VERSION ""

NS_ :

BS_:

BU_: VCU EAC EDS EPS BMS DCDC EVCC OBC
VAL_TABLE_ ALIVE_VCU_0xAB 15 "Invalid" ;
VAL_TABLE_ VCU_EDS_CtrModeReq 2 "Speed" 1 "Tqctr" 0 "inactive" ;
VAL_TABLE_ VCU_EDS_TargetTrqReq 4095 "Invalid" ;
VAL_TABLE_ VCU_EDS_TargetTrqReqV 0 "Valid" 1 "Invalid" ;
VAL_TABLE_ VCU_EDS_TargetSpeedReq 65535 "Invalid" ;
VAL_TABLE_ VCU_EDS_TargetSpeedReqV 0 "Valid" 1 "Invalid" ;
VAL_TABLE_ VCU_EDS_StsModeReq 15 "invaild" 14 "power oFF" 13 "Failure" 12 "aFter run" 11 "shut down" 5 "HVReady" 4 "normal" 3 "precharge" 2 "standby" 1 "init" 0 "deFault" ;
VAL_TABLE_ VCU_ACEnaReq 0 "No request" 1 "request" ;
VAL_TABLE_ VCU_ACSpdReq 8191 "Invalid" ;
VAL_TABLE_ VCU_ACPanelReqLevel 3 "Invalid" 2 "level 2 " 1 "level 1" 0 "oFF" ;
VAL_TABLE_ VCU_FanControl_Sts 0 "oFF" 1 "on" ;
VAL_TABLE_ VCU_ACPipePressSw_Sts 1 "close" 0 "open" ;
VAL_TABLE_ VCU_HVACInletTemp 1023 "Invalid" ;
VAL_TABLE_ ALIVE_VCU_0x155 15 "Invalid" ;
VAL_TABLE_ VCU_VecChrgRqst 0 "Default" 1 "permit" 2 "forbid" ;
VAL_TABLE_ VCU_Vechg_Status 3 "Charging Fault" 2 "Charging Complete" 1 "Charging in process" 0 "Charging not in process" ;
VAL_TABLE_ VCU_VecOptMod 0 "Sleep(休眠)" 1 "Initial(初始化)" 2 "PowerOn(上电)" 3 "Drive(行驶)" 4 "Charging(充电)" 5 "PowerOFF(下电)" 6 "Err(故障)" 7 "LimpHome" 8 "LVCharging(馈电补电)" ;
VAL_TABLE_ VCU_BMSHvPowOnRqst 1 "allow" 0 "forbid" ;
VAL_TABLE_ VCU_VecActGearStsV 1 "Invalid" 0 "Valid" ;
VAL_TABLE_ VCU_VecActGearSts 7 "Fault" 6 "Reserved" 5 "Reserved" 4 "Reserved" 3 "D" 2 "N" 1 "R" 0 "P" ;
VAL_TABLE_ VCU_LV_topupSts 3 "Rserved" 2 "Finish supply" 1 "suppling" 0 "dissupply" ;
VAL_TABLE_ VCU_DrTorqRqstV 1 "Invalid" 0 "Valid" ;
VAL_TABLE_ VCU_ABS_TrqReqOrLmt 65535 "Invalid" ;
VAL_TABLE_ VCU_CreepDisable_stt 0 "Enable" 1 "disable" ;
VAL_TABLE_ VCU_RDCSts 0 "inactive" 1 "Active" ;
VAL_TABLE_ VCU_RBCSts 0 "inactive" 1 "Active" ;
VAL_TABLE_ VCU_BrkPedalSWSts 0 "Notpressed" 1 "pressed" 2 "notused" 3 "Invalid" ;
VAL_TABLE_ Brakefluid_levelSts 0 "Normal" 1 "Low" 2 "Disconnect" 3 "reserve" ;
VAL_TABLE_ VCU_HandBrakeSts 0 "released" 1 "notreleased" ;
VAL_TABLE_ VCU_RegenLevelfeed 0 "OFF" 1 "ON" ;
VAL_TABLE_ VCU_PowerLimit 0 "NoLimit" 1 "Limit" ;
VAL_TABLE_ VCU_AccPedaPosValid 0 "Valid" 1 "Invalid" ;
VAL_TABLE_ VCU_VehicleHVStatus 0 "NotReady" 1 "HVOn" 2 "Ready" ;
VAL_TABLE_ VCUVacuumPresWrn 0 "Normal" 1 "Slight Insufficient" 2 "Serious Insufficient" 3 "Invalid" ;
VAL_TABLE_ VCUVacuumSts 0 "Normal" 1 "slow leak" 2 "quick leak" 3 "Invalid" ;
VAL_TABLE_ VCU_InstantPowerConsump 1023 "Invalid" ;
VAL_TABLE_ VCU_AveragePowerConsump 1023 "Invalid" ;
VAL_TABLE_ VCU_LowSOCWarning 0 "Normal" 1 "Low SOC" ;
VAL_TABLE_ VCU_TqReductionRqstResponse 0 "inactive" 1 "Active" ;
VAL_TABLE_ VCU_DrvModeSts 0 "Normal(正常模式)" 1 "Eco(经济模式)" 2 "Sport(运动模式)" 3 "Reserved(预留)" ;
VAL_TABLE_ VCU_VacuumPumpEna 1 "Enable" 0 "Disable" ;
VAL_TABLE_ VCU_VehicleFailureLevel 0 "Normal" 1 "Slight Fault" 2 "Minor fault" 3 "General fault" 4 "Serious Fault" 5 "Fatal fault" ;
VAL_TABLE_ VCU_EDSCAN_ERR 1 "Error" 0 "Normal" ;
VAL_TABLE_ VCU_BmsCAN_ERR 1 "Error" 0 "Normal" ;
VAL_TABLE_ VCU_DcdcCAN_ERR 1 "Error" 0 "Normal" ;
VAL_TABLE_ VCU_AbsCAN_ERR 1 "Error" 0 "Normal" ;
VAL_TABLE_ VCU_ACUCAN_ERR 1 "Error" 0 "Normal" ;
VAL_TABLE_ VCU_BcmCAN_ERR_reserved 1 "Error" 0 "Normal" ;
VAL_TABLE_ VCU_BrakeSys_Err 1 "Error" 0 "Normal" ;
VAL_TABLE_ VCU_AccPed_ERR 1 "Error" 0 "Normal" ;
VAL_TABLE_ VCU_Shift_ERR 1 "Error" 0 "Normal" ;
VAL_TABLE_ VCU_EPSCAN_ERR 1 "Error" 0 "Normal" ;
VAL_TABLE_ VCU_EvccCAN_ERR 1 "Error" 0 "Normal" ;
VAL_TABLE_ VCU_FlgHVIL_ERR 1 "Error" 0 "Normal" ;
VAL_TABLE_ VCU_ObcCAN_ERR 1 "Error" 0 "Normal" ;
VAL_TABLE_ VCU_SSCAN_ERR 1 "Error" 0 "Normal" ;
VAL_TABLE_ VCU_EacCAN_ERR 1 "Error" 0 "Normal" ;
VAL_TABLE_ VCU_AccPedalOutRange 1 "Error" 0 "Normal" ;
VAL_TABLE_ EDS_VCU_CtrMode 0 "Inactive" 1 "Toque control mode" 2 "Anti-slide slope" 3 "reserved" ;
VAL_TABLE_ EDS_MotorSpdVD 0 "Valid" 1 "Invalid" ;
VAL_TABLE_ EDS_MotorTqVD 0 "Valid" 1 "Invalid" ;
VAL_TABLE_ EDS_MotorTq 65534 "Abnormal" 65535 "Invaild" ;
VAL_TABLE_ EDS_MotorSpd 65534 "Abnormal" 65535 "Invaild" ;
VAL_TABLE_ EDS_HSA_Sts 0 "Inactive" 1 "Active" 2 "Reserved" 3 "Invalid" ;
VAL_TABLE_ EDS_DriveSTS 0 "Regeneration control" 1 "Drive control" 2 "Zero control" ;
VAL_TABLE_ EDS_StsMode 0 "DeFault(默认值)" 1 "Init(初始化)" 2 "Standby(待机)" 3 "Precharge(预充)" 4 "Normal(正常运行)" 5 "HVReady(高压上电完成)" 11 "ShutDown(关闭)" 12 "AFterRun(运行后)" 13 "Failure" 14 "PowerOFF(下电)" ;
VAL_TABLE_ EDS_VehicleFailureLevel 0 "Normal" 1 "Slight Fault" 2 "Minor fault" 3 "General fault" 4 "Serious Fault" 5 "Fatal fault" ;
VAL_TABLE_ EDS_HSA_Fault 0 "Normal" 1 "Level 1" 2 "Level 2" 3 "Invalid" ;
VAL_TABLE_ ALIVE_EDS_0xCA 15 "Invalid" ;
VAL_TABLE_ EDS_ActHV_VoltVD 1 "valid" 0 "invalid" ;
VAL_TABLE_ EDS_ActHV_CurVD 1 "valid" 0 "invalid" ;
VAL_TABLE_ EDS_ActHV_Cur 4095 "Invalid" ;
VAL_TABLE_ EDS_ActHV_Volt 4095 "Invalid" ;
VAL_TABLE_ ALIVE_EDS_0xCE 15 "Invalid" ;
VAL_TABLE_ EDS_MaxSpeedLimit 65535 "Invalid" ;
VAL_TABLE_ ALIVE_EDS_0x367 15 "Invalid" ;
VAL_TABLE_ EDS_MotTempSenFault 0 "Normal" 1 "Error" ;
VAL_TABLE_ EDS_EDSOverTempAlarm 0 "Normal" 1 "Error" ;
VAL_TABLE_ EDS_EDSOverTempFault 0 "Normal" 1 "Error" ;
VAL_TABLE_ EDS_LV_VotagtFault 0 "Normal" 1 "Error" ;
VAL_TABLE_ EDS_PhashOverCurrentSWFault 0 "Normal" 1 "Error" ;
VAL_TABLE_ EDS_EDSCurrentSenVFault 0 "Normal" 1 "Error" ;
VAL_TABLE_ EDS_EDSCurrentSenWFault 0 "Normal" 1 "Error" ;
VAL_TABLE_ EDS_EDSHVOverVoltageAlarm 0 "Normal" 1 "Error" ;
VAL_TABLE_ EDS_EDSHVOverVoltageFault 0 "Normal" 1 "Error" ;
VAL_TABLE_ EDS_EDSHVUnderVoltageAlarm 0 "Normal" 1 "Error" ;
VAL_TABLE_ EDS_EDSHVUnderVoltageFault 0 "Normal" 1 "Error" ;
VAL_TABLE_ EDS_MotOverTempAlarm 0 "Normal" 1 "Error" ;
VAL_TABLE_ EDS_MotOverTempFault 0 "Normal" 1 "Error" ;
VAL_TABLE_ EDS_EDSDisChgFault 0 "Normal" 1 "Error" ;
VAL_TABLE_ EDS_EDSHVSenFault 0 "Normal" 1 "Error" ;
VAL_TABLE_ EDS_12VOverVoltageAlarm 0 "Normal" 1 "Error" ;
VAL_TABLE_ EDS_12VUnderVoltageAlarm 0 "Normal" 1 "Error" ;
VAL_TABLE_ EDS_MotOverAlarm 0 "Normal" 1 "Error" ;
VAL_TABLE_ EDS_MotOverFault 0 "Normal" 1 "Error" ;
VAL_TABLE_ EDS_PhashOverCurrentHWFault 0 "Normal" 1 "Error" ;
VAL_TABLE_ EDS_EDSCurrentSenUFault 0 "Normal" 1 "Error" ;
VAL_TABLE_ EDS_VCULostFault 0 "Normal" 1 "Error" ;
VAL_TABLE_ EDS_BMSLostFault 0 "Normal" 1 "Error" ;
VAL_TABLE_ EDS_MotRotSenFault 0 "Normal" 1 "Error" ;
VAL_TABLE_ EDS_MotBlockedFault 0 "Normal" 1 "Error" ;
VAL_TABLE_ EDS_EDSChksumFault 0 "Normal" 1 "Error" ;
VAL_TABLE_ EDS_MotTrqLimtFault 0 "Normal" 1 "Error" ;
VAL_TABLE_ EDS_VCUChksumFault 0 "Normal" 1 "Error" ;
VAL_TABLE_ EDS_EDSEnableFault 0 "Normal" 1 "Error" ;
VAL_TABLE_ EDS_IGBTFault 0 "Normal" 1 "Error" ;
VAL_TABLE_ EDS_CANBUSOFFFault 0 "Normal" 1 "Error" ;
VAL_TABLE_ EDS_EDSTempSensorErr 0 "Normal" 1 "Error" ;
VAL_TABLE_ EDS_HWCapOverVolt 0 "Normal" 1 "Error" ;
VAL_TABLE_ EDS_SWCapOverVolt 0 "Normal" 1 "Error" ;
VAL_TABLE_ EDS_EDSMemoryFlt 0 "Normal" 1 "Error" ;
VAL_TABLE_ EDS_InitMode 0 "Normal" 1 "Error" ;
VAL_TABLE_ ALIVE_EDS_0x369 15 "Invalid" ;
VAL_TABLE_ EDS_IGBTState 3 "Normal operation" 2 "ASC From lower bridge arm" 1 "Enter ASC From upper bridge arm " 0 "OFF" ;
VAL_TABLE_ EDS_DampingState 1 "Dampingactive" 0 "Dampingdisable" ;
VAL_TABLE_ EDS_StsActiveDisChg 0 "NotActiveDischarge" 1 "ActiveDischarge" 2 "FailedActiveDischarge" 3 "FinishedActiveDischarge" ;
VAL_TABLE_ EDS_Motor_Phase_Curr 65535 "Invalid" ;
VAL_TABLE_ Rolling_counter_0x17E 15 "Invalid" ;
VAL_TABLE_ EPS_S_WarningLampYellow 0 "OFF" 1 "ON" ;
VAL_TABLE_ EPS_S_SaFeLampRed 0 "OFF" 1 "ON" ;
VAL_TABLE_ EPS_SteerWheelAngle 65535 "Invalid" ;
VAL_TABLE_ EPS_SteerWhlRotSpd 16383 "Invalid" ;
VAL_TABLE_ EPS_SteerWheelRotSpdStatus 0 "Valid" 1 "Invalid" ;
VAL_TABLE_ EPS_SteeringAngleValid 0 "Valid" 1 "Invalid" ;
VAL_TABLE_ EPS_VehicleFailureLevel 0 "Normal" 1 "Slight Fault" 2 "Minor fault" 3 "General fault" 4 "Serious Fault" 5 "Fatal fault" ;
VAL_TABLE_ EPS_status 0 "NoFailure" 1 "SlightFailure" 2 "CriticalFailure" 3 "FatalFailure" ;
VAL_TABLE_ EPS_Calibrated 0 "NotCalibrated" 1 "Calibrated" ;
VAL_TABLE_ EPS_Systemstatus 0 "NoFailure" 1 "SlightFailure" 2 "CriticalFailure" 3 "FatalFailure" ;
VAL_TABLE_ Alive_SAS_0x17F 15 "Invalid" ;
VAL_TABLE_ EPS_SteeringTorque 4095 "Invalid" ;
VAL_TABLE_ EPS_SASFailure 0 "Failure" 1 "No failure" ;
VAL_TABLE_ EPS_SASStsSnsr 1 "sensor value valid" 0 "sensor value Invalid" ;
VAL_TABLE_ EPS_TorqSensorStatus 0 "Valid" 1 "Invalid" ;
VAL_TABLE_ EPS_Mode 3 " Invalid" 1 "low assist" 0 "Full assist" ;
VAL_TABLE_ EPS_EpsFailed 1 "Failed" 0 "not Failed" ;
VAL_TABLE_ EAC_Sts 0 "Stop" 1 "Work" ;
VAL_TABLE_ EAC_VehicleFailureLevel 0 "Normal" 1 "Slight Fault" 2 "Minor fault" 3 "General fault" 4 "Serious Fault" 5 "Fatal fault" ;
VAL_TABLE_ EAC_ErrorCode 0 "Normal" 1 "Under Voltage" 2 "Over Voltage" 3 "Over Temperature" 4 "Over Current" 5 "IGBT Fault" 6 "Over Pressure" ;
VAL_TABLE_ Rolling_Counter_0x85 15 "Invalid" ;
VAL_TABLE_ ACU_Crash_Sts 3 "Invalid Value" 2 "Invalid Value" 1 "Crash_Detected" 0 "No_Event" ;
VAL_TABLE_ ACU_Airbag_Deployment_Status 3 "Invalid Value" 2 "Invalid Value" 1 "Airbag_Deployment" 0 "No_Airbag_Deployment" ;
VAL_TABLE_ ALIVE_ABS_0x118 15 "Invalid" ;
VAL_TABLE_ ABS_HazardLightsOnReq 0 "No request" 1 "request" ;
VAL_TABLE_ ABS_BrakeLightsOnReq 0 "No request" 1 "request" ;
VAL_TABLE_ ABS_TcsFlgFlt 1 "Failure" 0 "no Failure" ;
VAL_TABLE_ ABS_TCS_Active 1 "active" 0 "inactive" ;
VAL_TABLE_ ABS_ABSActive 1 "active" 0 "inactive" ;
VAL_TABLE_ ABS_EBDFault 1 "Fault" 0 "Normal" ;
VAL_TABLE_ ABS_ABSFault 1 "Fault" 0 "Normal" ;
VAL_TABLE_ ABS_TCS_OFF_State 1 "open" 0 "close" ;
VAL_TABLE_ ABS_VehicleFailureLevel 0 "Normal" 1 "Slight Fault" 2 "Minor fault" 3 "General fault" 4 "Serious Fault" 5 "Fatal fault" ;
VAL_TABLE_ ABS_RBSInhibitFlag 0 "Not Inhibit" 1 "Inhibit" ;
VAL_TABLE_ ABS_EBDActive 1 "active" 0 "inactive" ;
VAL_TABLE_ ABS_VehicleSpeed 32767 "Invalid" ;
VAL_TABLE_ ABS_VehicleSpeedV 0 "Invalid" 1 "Valid" ;
VAL_TABLE_ BCM_FrontLeftDoorAjarStatus 0 "Closed" 1 "Opened" 2 "Reserved" 3 "Signal invalid" ;
VAL_TABLE_ BCM_FrontRightDoorAjarStatus 0 "Closed" 1 "Opened" 2 "Reserved" 3 "Signal invalid" ;
VAL_TABLE_ BCM_RightDoorLockStatusDrv 0 "Unlcoked" 1 "Locked" 2 "Reserved" 3 "Signal invalid" ;
VAL_TABLE_ BCM_LeftDoorLockStatusDrv 0 "Unlcoked" 1 "Locked" 2 "Reserved" 3 "Signal invalid" ;
VAL_TABLE_ BCM_ATWS_St 0 "Secured" 1 "Unsecured" 2 "Alarm" 3 "Partly secured" 4 "Security Failure" 5 "Reserved" 6 "Reserved" 7 "Signal invalid" ;
VAL_TABLE_ BCM_STAT_DoorSpeedLock 0 "OFF" 1 "5KMH" 2 "10KMH" 3 "15KMH" 4 "20KMH" 5 "25KMH" 6 "Signal invalid" ;
VAL_TABLE_ BCM_LV_topupReq 0 "inactive" 1 "Active" 2 "Rserved" 3 "Rserved" ;
VAL_TABLE_ BCM_BatteryVoltage 597 "Invalid" ;
VAL_TABLE_ BCM_Key_CheckSts 0 "Passed" 1 "Invalid" ;
VAL_TABLE_ BCM_Press_BrkPedal_Alert 0 "inactive" 1 "Active" ;
VAL_TABLE_ BCM_EmergencyStop 0 "Normal" 1 "EmergencyStop" 2 "Rserved" 3 "Invalid" ;
VAL_TABLE_ BCM_IGN1RelayOutputSts 0 "inactive" 1 "Active" 2 "Reserved" 3 "Reserved" ;
VAL_TABLE_ BCM_ACCRelayOutputSts 0 "inactive" 1 "Active" 2 "Reserved" 3 "Reserved" ;
VAL_TABLE_ BCM_FLWIN_Postion_Reserved 0 "NotActive" 1 "Closed(Top)" 2 "Open(Bottom)" 3 "80%-Close(Reserved)" 4 "Open-80%(Reserved)" 5 "opening" 6 "closing" 7 "Reserved" ;
VAL_TABLE_ BCM_KEY_MatchSts 0 "No Match" 1 "Match Success" 2 "Match Failed" 3 "Matching" ;
VAL_TABLE_ BCM_FRWIN_Postion_Reserved 0 "NotActive" 1 "Closed(Top)" 2 "Open(Bottom)" 3 "80%-Close(Reserved)" 4 "Open-80%(Reserved)" 5 "opening" 6 "closing" 7 "Reserved" ;
VAL_TABLE_ BCM_PowerMode 0 "OFF" 1 "ACC" 2 "ON" 3 "START" ;
VAL_TABLE_ BCM_BrakeSwSts 0 "Notpressed" 1 "pressed" 2 "notused" 3 "Invalid" ;
VAL_TABLE_ BCM_VehicleFailureLevel 0 "Normal" 1 "Slight Fault" 2 "Minor fault" 3 "General fault" 4 "Serious Fault" 5 "Fatal fault" ;
VAL_TABLE_ BCM_Anti_theftAlarmSetSts 0 "Light" 1 "Horn" 2 "Both" 3 "Invalid" ;
VAL_TABLE_ BCM_FMH_SetSts 0 "OFF" 1 "30s" 2 "60s" 3 "90s" ;
VAL_TABLE_ BCM_IGN1RelayFaultSts 0 "No Fault" 1 "Fault" 2 "Reserved" 3 "Signal Invalid" ;
VAL_TABLE_ BCM_ACCRelayFaultSts 0 "No Fault" 1 "Fault" 2 "Reserved" 3 "Signal Invalid" ;
VAL_TABLE_ IPC_EnergyRecSet 0 "OFF(关闭)" 1 "ON(开启)" 2 "Reserved(预留)" 3 "Reserved(预留)" ;
VAL_TABLE_ IPC_HSA_Set 0 "OFF" 1 "ON" 2 "Reserved" 3 "Invalid" ;
VAL_TABLE_ IPC_DriveModeSet 0 "NoReq" 1 "NormalMode" 2 "ECOmode" 3 "SportMode(预留)" ;
VAL_TABLE_ IPC_VCU_CreepDisable_Stt 0 "No request" 1 "request" ;
VAL_TABLE_ IPC_DriveLockSpeedCtl 0 "OFF" 1 "5KMH" 2 "10KMH" 3 "15KMH" 4 "20KMH" 5 "25KMH" 6 "Signal invalid" ;
VAL_TABLE_ Rolling_Counter_0x432 15 "Invalid" ;
VAL_TABLE_ IPC_FOTA_State 0 "INIT" 1 "NORMAL" 2 "FOTA FLASHING" 3 "Reserved" 4 "FAIL-SAFE-ERROR" 5 "Reserved" 6 "REMOTE DIAGNOSTICS" 7 "Invalid" ;
VAL_TABLE_ IPC_ChargeScheduleSet 0 "Disable" 1 "Enabled" 2 "No Action" 3 "Reserved" ;
VAL_TABLE_ IPC_ChargingRequest 0 "No Effect" 1 "Request scheduled start charging" 2 "Request stop" 3 "Reserved" ;
VAL_TABLE_ IPC_Year 255 "Invalid" ;
VAL_TABLE_ IPC_Month 15 "Invalid" ;
VAL_TABLE_ IPC_SelFCheckStatus 1 "selF-check Finish" 0 "selF-checking" ;
VAL_TABLE_ IPC_Day 31 "Invalid" ;
VAL_TABLE_ IPC_Hour 31 "Invalid" ;
VAL_TABLE_ IPC_Min 63 "Invalid" ;
VAL_TABLE_ IPC_Sec 63 "Invalid" ;
VAL_TABLE_ IPC_ODO 1048575 "Invalid" ;
VAL_TABLE_ Rolling_Counter_0x108 15 "Invalid" ;
VAL_TABLE_ SS_DriveModeReq_reserved 1 "press" 0 "no press" ;
VAL_TABLE_ SS_TargetGearReq 7 "Reserved" 4 "Invalid" 3 "D" 2 "N" 1 "R" 0 "Stop Charging" ;
VAL_TABLE_ SS_Fault 6 "Received Date from BCM is invalid" 5 "Received Date from VCU is invalid" 4 "Supply voltage failure" 3 "Position sensor failure" 2 "CAN communication fail" 1 "Shifter failure" 0 "normal" ;
VAL_TABLE_ FR_Wipercontrol_switch 7 "Invalid " 6 "reserved " 5 "reserved " 4 "High " 3 "Int2 " 2 "Int1 " 1 "Low " 0 "OFF" ;
VAL_TABLE_ Front_Wash 3 "Invalid " 2 "Wash " 1 "Mist" 0 "OFF" ;
VAL_TABLE_ SS_FogLight_reserved 0 "OFF" 1 "ON" ;
VAL_TABLE_ RR_Wiper 3 "Invalid " 2 "Wash " 1 "Wipe " 0 "OFF" ;
VAL_TABLE_ SS_lane_change_lampSts 0 "OFF" 1 "Left lane change" 2 "Right lane change" 3 "Reserved" ;
VAL_TABLE_ SS_Overtaking_lamp 0 "OFF" 1 "ON" ;
VAL_TABLE_ SS_TurnIndicatorSts 0 "OFF" 1 "Left On" 2 "Right On" 3 "Reserved" ;
VAL_TABLE_ SS_PosLmpSts 0 "OFF " 1 "ON" ;
VAL_TABLE_ SS_LowBeamSts 0 "OFF" 1 "ON" ;
VAL_TABLE_ SS_HighBeamSts 0 "OFF" 1 "ON" ;
VAL_TABLE_ Rolling_Counter_0x216 15 "Invalid" ;
VAL_TABLE_ BMS_RemainChargeTime 16383 "Invalid" ;
VAL_TABLE_ BMS_ChgVoltage_REQ 16383 "Invalid" ;
VAL_TABLE_ BMS_ChgCurrent_REQ 65535 "Invalid" ;
VAL_TABLE_ Rolling_Counter_0x126 15 "Invalid" ;
VAL_TABLE_ BMS_AllowRegCurrPeak 65535 "Invalid" ;
VAL_TABLE_ BMS_AllowRegCurr 65535 "Invalid" ;
VAL_TABLE_ Rolling_Counter_0x209 15 "Invalid" ;
VAL_TABLE_ BMS_MaxDischgPwr_ALW 4095 "Invalid" ;
VAL_TABLE_ BMS_MaxChgPwr_ALW 4095 "Invalid" ;
VAL_TABLE_ BMS_MaxDischgPwr_Peak 4095 "Invalid" ;
VAL_TABLE_ BMS_MaxChgPwr_Peak 4095 "Invalid" ;
VAL_TABLE_ Rolling_Counter_0x249 15 "Invalid" ;
VAL_TABLE_ Rolling_Counter_0x248 15 "Invalid" ;
VAL_TABLE_ BMS_FlowRate_Req 255 "Invalid" ;
VAL_TABLE_ BMS_CoolPwrDemand 4095 "Invalid" ;
VAL_TABLE_ BMS_VCU_ValveOnOff_Req 1 "open " 0 "close" ;
VAL_TABLE_ BMS_HeatPwrDemand 4095 "Invalid" ;
VAL_TABLE_ BMS_VCU_PTCOnOff_Req 1 "ON" 0 "OFF" ;
VAL_TABLE_ Rolling_Counter_0x206 15 "Invalid" ;
VAL_TABLE_ BMS_MaxMinDiffCellVol 8191 "Invalid value if diff > 500mV" ;
VAL_TABLE_ Rolling_Counter_0x332 15 "Invalid" ;
VAL_TABLE_ BMS_PackTemp_Infor 255 "Invalid" ;
VAL_TABLE_ Rolling_Counter_0x330 15 "Invalid" ;
VAL_TABLE_ BMS_ContactorAging 2 "Fault: counter reach 98%" 1 "Warning: counter reach 90%" 0 "Normal" ;
VAL_TABLE_ Rolling_Counter_0x176 15 "Invalid" ;
VAL_TABLE_ BMS_HVLinkVol_MEAS 65535 "Invalid" ;
VAL_TABLE_ BMS_HVPackVol_MEAS 65535 "Invalid" ;
VAL_TABLE_ Rolling_Counter_0x177 15 "Invalid" ;
VAL_TABLE_ BMS_HVBusVol_MEAS 65535 "Invalid" ;
VAL_TABLE_ BMS_HVFuseVol_MEAS 65535 "Invalid" ;
VAL_TABLE_ Rolling_Counter_0x174 15 "Invalid" ;
VAL_TABLE_ BMS_PackCur_MEAS 65535 "Invalid" ;
VAL_TABLE_ BMS_AllowDischgCurr 65535 "Invalid" ;
VAL_TABLE_ BMS_AllowDischgCurrPeak 65535 "Invalid" ;
VAL_TABLE_ Rolling_Counter_0x214 15 "Invalid" ;
VAL_TABLE_ BMS_Display_SOC 1023 "Invalid" ;
VAL_TABLE_ Rolling_Counter_0x215 15 "Invalid" ;
VAL_TABLE_ BMS_SOE 255 "Invalid" ;
VAL_TABLE_ BMS_HWCrash_Sts 1 "Crash " 0 "No Crash" ;
VAL_TABLE_ BMS_HVIL_STS 2 "out of range" 1 "Open" 0 "Closed" ;
VAL_TABLE_ BMS_IGN_Sts 1 "ON " 0 "OFF" ;
VAL_TABLE_ BMS_Sys_STS 8 "Invalid" 7 "Failure, unable to operate" 6 "BCU Sleep mode" 5 "Successful Power Down" 4 "Power Down process" 3 "Successful Power Down of HV" 2 "Successful High Voltage Power Up" 1 "Self-check passes, can be high-voltage" 0 "Initialization of power on, self-checking" ;
VAL_TABLE_ BMS_HVOnOff_STS 3 "Fail to HV on " 2 "HV On " 1 "Precharge " 0 "HV Off" ;
VAL_TABLE_ BMS_Balance_STS 1 "active " 0 "Inactive" ;
VAL_TABLE_ BMS_BatBalance_ERR 1 "normal " 0 "Error" ;
VAL_TABLE_ BMS_ISU_Status 3 "Level3(<100 Ohms/V)" 2 "Level2(<200 Ohms/V)" 1 "Level1 <500 Ohms/V ~ >200 Ohms/V" 0 "Normal (> 500 Ohms/V)" ;
VAL_TABLE_ BMS_ERR_LEV 7 "Battery locked -Reserved" 6 "Fault, needs Shutdown and Wakeup" 5 "Emergency off condition" 4 "Delayed power down with FTTI" 3 "Power down without FTTI" 2 "Limp Home" 1 " Warning (any warning in system)" 0 "No error" ;
VAL_TABLE_ BMS_Vehicle_ERR_LEV 0 "Normal" 1 "Slight Fault" 2 "Minor fault" 3 "General fault" 4 "Serious Fault" 5 "Fatal fault" ;
VAL_TABLE_ BMS_HV_Sts 4 "AC Charging" 3 "DC Charging" 2 "HV ON" 1 "Precharge" 0 "HV Off" ;
VAL_TABLE_ Rolling_Counter_0x225 15 "Invalid" ;
VAL_TABLE_ CDM_bAcvCanComStblMon 1 "Error" 0 "No error" ;
VAL_TABLE_ FRMo_bErrHvbatStReqExtMon 1 "Error" 0 "No error" ;
VAL_TABLE_ FRMo_bErrChrgnAllwdExtMon 1 "Error" 0 "No error" ;
VAL_TABLE_ FRMo_bErrVehCrashStExtMon 1 "Error" 0 "No error" ;
VAL_TABLE_ CDM_bErrComctnLossCanMon 1 "Error" 0 "No error" ;
VAL_TABLE_ CTCMon_bErrCtctrSopcMon 1 "Error" 0 "No error" ;
VAL_TABLE_ CTCMon_bInvldCtctrHisdIFbMon 1 "Error" 0 "No error" ;
VAL_TABLE_ CTCMon_bInvldCtctrLosdUFbMon 1 "Error" 0 "No error" ;
VAL_TABLE_ CTM_bErrCellTDifMaxMon 1 "Error" 0 "No error" ;
VAL_TABLE_ CTM_bErrCellTMaxMon 1 "Error" 0 "No error" ;
VAL_TABLE_ CTM_bErrCellTMinMon 1 "Error" 0 "No error" ;
VAL_TABLE_ CTM_bErrThrwyPredMon 1 "Error" 0 "No error" ;
VAL_TABLE_ CUM_bErrCellUDifMaxMon 1 "Error" 0 "No error" ;
VAL_TABLE_ CUM_bErrCellUMaxMon 1 "Error" 0 "No error" ;
VAL_TABLE_ CUM_bErrCellUMinMon 1 "Error" 0 "No error" ;
VAL_TABLE_ CUM_bErrCellUProtnMaxNvMon 1 "Error" 0 "No error" ;
VAL_TABLE_ CUM_bErrCellUProtnMinNvMon 1 "Error" 0 "No error" ;
VAL_TABLE_ CUM_bErrPackUImplyMon 1 "Error" 0 "No error" ;
VAL_TABLE_ EHPMon_bRdyHvilMon 1 "Error" 0 "No error" ;
VAL_TABLE_ EHPMon_bErrWlddNegNvMon 1 "Error" 0 "No error" ;
VAL_TABLE_ EHPMon_bErrWlddPosNvMon 1 "Error" 0 "No error" ;
VAL_TABLE_ EHPMon_bErrWlddPrechNvMon 1 "Error" 0 "No error" ;
VAL_TABLE_ EHPMon_bErrHvilMon 1 "Error" 0 "No error" ;
VAL_TABLE_ EHPMon_bErrHvilShoMon 1 "Error" 0 "No error" ;
VAL_TABLE_ EHPMon_bErrPackIslnRNvMon 1 "Error" 0 "No error" ;
VAL_TABLE_ EHPMon_bErrVehCrashNvMon 1 "Error" 0 "No error" ;
VAL_TABLE_ EHPMon_bErrVehIslnRNvMon 1 "Error" 0 "No error" ;
VAL_TABLE_ FRMo_bErrMemStorgNvMon 1 "Error" 0 "No error" ;
VAL_TABLE_ L1IM_bErrClmp30MaxMonInp 1 "Error" 0 "No error" ;
VAL_TABLE_ L1IM_bErrClmp30MinMonInp 1 "Error" 0 "No error" ;
VAL_TABLE_ L1IM_bErrCtctrDtrtMonInp 1 "Error" 0 "No error" ;
VAL_TABLE_ L1IM_bErrUActImplyMonInp 1 "Error" 0 "No error" ;
VAL_TABLE_ MCCM_bAcvMdulCtlrStsMon 1 "Error" 0 "No error" ;
VAL_TABLE_ MCCM_bErrLntecSngFltMon 1 "Error" 0 "No error" ;
VAL_TABLE_ MCCM_bErrLntecLtntFltMon 1 "Error" 0 "No error" ;
VAL_TABLE_ MCCM_bErrMdulCellSnsrCfgMon 1 "Error" 0 "No error" ;
VAL_TABLE_ MCCM_bErrMdulCtlrComMon 1 "Error" 0 "No error" ;
VAL_TABLE_ MCCM_bErrSnsrTEltlMon 1 "Error" 0 "No error" ;
VAL_TABLE_ MCCM_bWarnSnsrTEltlMon 1 "Error" 0 "No error" ;
VAL_TABLE_ PCM_bRdySnsrIMon 1 "Error" 0 "No error" ;
VAL_TABLE_ PCM_bErrPackEFlowMaxLimMon 1 "Error" 0 "No error" ;
VAL_TABLE_ PCM_bErrPackIChDchaMaxLimMon 1 "Error" 0 "No error" ;
VAL_TABLE_ PCM_bErrSnsrIImplyMon 1 "Error" 0 "No error" ;
VAL_TABLE_ FRMo_bErrSnsrI1ExtMon 1 "Error" 0 "No error" ;
VAL_TABLE_ PCM_bInvldSnsrI1Mon 1 "Error" 0 "No error" ;
VAL_TABLE_ PCM_bInvldSnsrI2Mon 1 "Error" 0 "No error" ;
VAL_TABLE_ FRMo_bErrSopcLvl3Mon 1 "Error" 0 "No error" ;
VAL_TABLE_ BMS_FRMo_Reserved_1 1 "Error" 0 "No error" ;
VAL_TABLE_ BMS_FRMo_Reserved_2 1 "Error" 0 "No error" ;
VAL_TABLE_ BMS_FRMo_Reserved_3 1 "Error" 0 "No error" ;
VAL_TABLE_ BMS_FRMo_Reserved_4 1 "Error" 0 "No error" ;
VAL_TABLE_ BMS_FRMo_Reserved_5 1 "Error" 0 "No error" ;
VAL_TABLE_ Rolling_Counter_0x125 15 "Invalid" ;
VAL_TABLE_ Rolling_Counter_0x375 15 "Invalid" ;
VAL_TABLE_ BMS_MainPosRelay_ERR 1 "normal " 0 "Error" ;
VAL_TABLE_ BMS_MainPosRelay_STS 4 "stuck open" 3 "stuck closed" 2 "closed" 1 "open" 0 "reserved" ;
VAL_TABLE_ BMS_PreChgRelay_ERR 1 "normal " 0 "error" ;
VAL_TABLE_ BMS_PreChgRelay_STS 4 "stuck open" 3 "stuck closed" 2 "closed" 1 "open" 0 "reserved" ;
VAL_TABLE_ BMS_TotalNegRelay_STS 4 "stuck open" 3 "stuck closed" 2 "closed" 1 "open" 0 "reserved" ;
VAL_TABLE_ BMS_TotalNegRelay_ERR 1 "normal " 0 "Error" ;
VAL_TABLE_ Rolling_Counter_0x205 15 "Invalid" ;
VAL_TABLE_ BMS_MaxCellVol 8191 "Invalid" ;
VAL_TABLE_ BMS_CellNumMaxCellVol 0 "Invalid" ;
VAL_TABLE_ BMS_MinCellVol 8191 "Invalid" ;
VAL_TABLE_ BMS_CellNumMinCellVol 0 "Invalid" ;
VAL_TABLE_ Rolling_Counter_0x245 15 "Invalid" ;
VAL_TABLE_ BMS_PackTemp 255 "Invalid" ;
VAL_TABLE_ BMS_MaxMinDiffCellTemp 255 "Diff Temp" ;
VAL_TABLE_ BMS_MaxCellTemp 255 "Invalid" ;
VAL_TABLE_ BMS_MinCellTemp 255 "Invalid" ;
VAL_TABLE_ BMS_ProbeNumMaxCellTemp 63 "Invalid" 62 "Error" 0 "Invalid" ;
VAL_TABLE_ BMS_ProbeNumMinCellTemp 63 "Invalid" 62 "Error" 0 "Invalid" ;
VAL_TABLE_ Rolling_Counter_0x305 15 "Invalid" ;
VAL_TABLE_ BMS_VCU_Insulation_Mon_Sts 1 "OFF" 0 "ON" ;
VAL_TABLE_ BMS_Warning_Flag_Reserved_08 1 "Warning" 0 "No warning" ;
VAL_TABLE_ BMS_Warning_Flag_Reserved_07 1 "Warning" 0 "No warning" ;
VAL_TABLE_ BMS_Warning_Flag_Reserved_11 1 "Warning" 0 "No warning" ;
VAL_TABLE_ BMS_Warning_Flag_Reserved_10 1 "Warning" 0 "No warning" ;
VAL_TABLE_ BMS_Warning_Flag_Reserved_09 1 "Warning" 0 "No warning" ;
VAL_TABLE_ BMS_Warning_Flag_Reserved_13 1 "Warning" 0 "No warning" ;
VAL_TABLE_ BMS_Warning_Flag_Reserved_12 1 "Warning" 0 "No warning" ;
VAL_TABLE_ BMS_Warning_Flag_Reserved_06 1 "Warning" 0 "No warning" ;
VAL_TABLE_ BMS_Warning_Flag_Reserved_05 1 "Warning" 0 "No warning" ;
VAL_TABLE_ BMS_Warning_Flag_Reserved_04 1 "Warning" 0 "No warning" ;
VAL_TABLE_ BMS_MalfunctionSts 1 "Malfunction indicator lamp ON" 0 "Malfunction indicator lamp OFF" ;
VAL_TABLE_ BMS_LowBattery 2 "Extremely low level" 1 "Low level" 0 "No warning" ;
VAL_TABLE_ BMS_BatteryReplacement 1 "Warning" 0 "No warning" ;
VAL_TABLE_ BMS_PackTempSts 2 "Under Temperature Warning" 1 "Over Temperature Warning" 0 "No warning" ;
VAL_TABLE_ BMS_ThermalRunaway 1 "Warning" 0 "No warning" ;
VAL_TABLE_ Rolling_Counter_0x493 15 "Invalid" ;
VAL_TABLE_ Rolling_Counter_0x455 15 "Invalid" ;
VAL_TABLE_ BMS_PackInsu_ERR 2 "Lv2-Short to vbat and open line" 1 "Lv1 - Short to ground" 0 "Lv0-No Err" ;
VAL_TABLE_ BMS_CellVoltDiff_ERR 3 "Level3 Reserve" 2 "Level2 Serious alarm value" 1 "Level1 General alarm value" 0 "Level0 Normal" ;
VAL_TABLE_ BMS_PackOverCurr_ERR 2 "Serious Alarm value" 1 "General Alarm Value" 0 "Normal" ;
VAL_TABLE_ BMS_HVIL_Err 3 "Level3" 2 "Level2" 1 "Level1" 0 "Normal" ;
VAL_TABLE_ BMS_CellHighVol_ERR 3 "Level3 Reserve" 2 "Level2 Serious alarm value" 1 "Level1 General alarm value" 0 "Level0 Normal" ;
VAL_TABLE_ BMS_CellLowVol_ERR 3 "Level3 Reserve" 2 "Level2 Serious alarm value" 1 "Level1 General alarm value" 0 "Level0 Normal" ;
VAL_TABLE_ BMS_PackLowVol_ERR 3 "Level3 Reserve" 2 "Level2 Serious alarm value" 1 "Level1 General alarm value" 0 "Level0 Normal" ;
VAL_TABLE_ BMS_PackHighVol_ERR 3 "Level3 Reserve" 2 "Level2 Serious alarm value" 1 "Level1 General alarm value" 0 "Level0 Normal" ;
VAL_TABLE_ BMS_ProbeHighTemp_ERR 3 "Level3 Reserve" 2 "Level2 Serious alarm value" 1 "Level1 General alarm value" 0 "Level0 Normal" ;
VAL_TABLE_ BMS_ProbeTempDiff_ERR 3 "Level3 Reserve" 2 "Level2 Serious alarm value" 1 "Level1 General alarm value" 0 "Level0 Normal" ;
VAL_TABLE_ BMS_FuseStatus_ERR 1 "Fuse blow" 0 "Normal" ;
VAL_TABLE_ BMS_ProbeLowTemp_ERR 3 "Level3 Reserve" 2 "Level2 Serious alarm value" 1 "Level1 General alarm value" 0 "Level0 Normal" ;
VAL_TABLE_ softwore_version 1 "valid" 0 "Invalid" ;
VAL_TABLE_ BMS_QMMo_Reserved_9 1 "Error" 0 "No Error" ;
VAL_TABLE_ BMS_QMMo_Reserved_8 1 "Error" 0 "No Error" ;
VAL_TABLE_ BMS_QMMo_Reserved_7 1 "Error" 0 "No Error" ;
VAL_TABLE_ BMS_QMMo_Reserved_6 1 "Error" 0 "No Error" ;
VAL_TABLE_ BMS_QMMo_Reserved_5 1 "Error" 0 "No Error" ;
VAL_TABLE_ BMS_QMMo_Reserved_4 1 "Error" 0 "No Error" ;
VAL_TABLE_ BMS_QMMo_Reserved_3 1 "Error" 0 "No Error" ;
VAL_TABLE_ BMS_QMMo_Reserved_2 1 "Error" 0 "No Error" ;
VAL_TABLE_ BMS_QMMo_Reserved_11 1 "Error" 0 "No Error" ;
VAL_TABLE_ BMS_QMMo_Reserved_10 1 "Error" 0 "No Error" ;
VAL_TABLE_ BMS_QMMo_Reserved_1 1 "Error" 0 "No Error" ;
VAL_TABLE_ BMS_QMMo_Reserved_0 1 "Error" 0 "No Error" ;
VAL_TABLE_ Rolling_Counter_0x5E4 15 "Invalid" ;
VAL_TABLE_ Rolling_Counter_0x20B 15 "Invalid" ;
VAL_TABLE_ POD_DCDC_Max_Current_Out 1023 "Invalid" ;
VAL_TABLE_ DCDC_Temp_mosfet 255 "Invalid" ;
VAL_TABLE_ DCDC_Voltage_Output 1023 "Invalid" ;
VAL_TABLE_ DCDC_Current_Output 255 "Invalid" ;
VAL_TABLE_ DCDC_Output_STS 0 "DCDC_OFF" 1 "DCDC_STANDBY" 2 "DCDC_ON" 3 "DCDC_RESERVED" 4 "DCDC_DEGRAEDED" 5 "DCDC_FAULT_SHUTDOWN" 6 "DCDC_EMEGENCY_SHUTDOWN" 7 "DCDC_SNA" ;
VAL_TABLE_ DCDC_Temp_heatsink 255 "Invalid" ;
VAL_TABLE_ Rolling_Counter_0x286 15 "Invalid" ;
VAL_TABLE_ DCFC_OUT_DC_V 65535 "Invalid" ;
VAL_TABLE_ DCFC_OUT_DC_I_Reserved 16383 "Invalid" ;
VAL_TABLE_ DCFC_DCCharge_line_V 65535 "Invalid" ;
VAL_TABLE_ DCDC_evt_BUS_OFF 1 "Error" 0 "Normal" ;
VAL_TABLE_ DCDC_evt_MIA 1 "Error" 0 "Normal" ;
VAL_TABLE_ DCDC_evt_E2E 1 "Error" 0 "Normal" ;
VAL_TABLE_ DCDC_evt_Calibration_Flt 1 "Error" 0 "Normal" ;
VAL_TABLE_ DCDC_evt_flash_Failure 1 "Error" 0 "Normal" ;
VAL_TABLE_ DCDC_evt_FaultLatchCircuit 1 "Error" 0 "Normal" ;
VAL_TABLE_ DCDC_evt_HV_VoltSensFlt 1 "Error" 0 "Normal" ;
VAL_TABLE_ DCDC_evt_HV_OverVoltFlt 1 "Error" 0 "Normal" ;
VAL_TABLE_ DCDC_evt_HV_UnderVoltFlt 1 "Error" 0 "Normal" ;
VAL_TABLE_ DCDC_evt_LV_VoltSensFlt 1 "Error" 0 "Normal" ;
VAL_TABLE_ DCDC_evt_LVBatt_OverVoltFlt 1 "Error" 0 "Normal" ;
VAL_TABLE_ DCDC_evt_LVBatt_UnderVoltFlt 1 "Error" 0 "Normal" ;
VAL_TABLE_ DCDC_evt_LVBatt_SensorFlt 1 "Error" 0 "Normal" ;
VAL_TABLE_ DCDC_evt_LV_RedundancyFlt 1 "Error" 0 "Normal" ;
VAL_TABLE_ DCDC_evt_LV_CurrSensFlt 1 "Error" 0 "Normal" ;
VAL_TABLE_ DCDC_evt_LV_OverCurr 1 "Error" 0 "Normal" ;
VAL_TABLE_ DCDC_evt_ReverseCurrFlt 1 "Error" 0 "Normal" ;
VAL_TABLE_ DCDC_evt_Heater_TempSensorFlt 1 "Error" 0 "Normal" ;
VAL_TABLE_ DCDC_evt_Mosfet_TempSensorFlt 1 "Error" 0 "Normal" ;
VAL_TABLE_ DCDC_evt_Mosfet_OverTemp 1 "Error" 0 "Normal" ;
VAL_TABLE_ DCDC_evt_HeatSink_TempSensorFlt 1 "Error" 0 "Normal" ;
VAL_TABLE_ DCDC_evt_HeatSink_OverTemp 1 "Error" 0 "Normal" ;
VAL_TABLE_ DCDC_evt_Heater_OverTempFlt 1 "Error" 0 "Normal" ;
VAL_TABLE_ DCDC_evt_Heater_ShortIGBTFlt 1 "Error" 0 "Normal" ;
VAL_TABLE_ DCDC_evt_LV_ShortOutputFlt 1 "Error" 0 "Normal" ;
VAL_TABLE_ DCDC_evt_sw_BMS_CrashFlt 1 "Error" 0 "Normal" ;
VAL_TABLE_ DCDC_evt_BMS_HVILFlt 1 "Error" 0 "Normal" ;
VAL_TABLE_ DCFC_evt_BusbarSensFlt 1 "Error" 0 "Normal" ;
VAL_TABLE_ DCFC_evt_Contactor_Welded 1 "Error" 0 "Normal" ;
VAL_TABLE_ DCFC_evt_ContactorStuckOpen 1 "Error" 0 "Normal" ;
VAL_TABLE_ DCFC_evt_CP_UnderVoltFlt 1 "Error" 0 "Normal" ;
VAL_TABLE_ DCFC_evt_DataInvalidVCUFlt 1 "Error" 0 "Normal" ;
VAL_TABLE_ DCFC_evt_ChargePortSensFlt 1 "Error" 0 "Normal" ;
VAL_TABLE_ DCFC_evt_OverChargePortFlt 1 "Error" 0 "Normal" ;
VAL_TABLE_ DCFC_evt_OverBusbarTemp 1 "Error" 0 "Normal" ;
VAL_TABLE_ DCFC_evt_E2E_Flt 1 "Error" 0 "Normal" ;
VAL_TABLE_ DCFC_evt_MIA_Flt 1 "Error" 0 "Normal" ;
VAL_TABLE_ Rolling_Counter_0x406 15 "Invalid" ;
VAL_TABLE_ DCDC_FaultLevel 5 "Level5,Fatal fault" 4 "Level4,Serious fault" 3 "Level3,General fault" 2 "Level2,Minor fault" 1 "Level1,slight fault" 0 "No Fault" ;
VAL_TABLE_ DCFC_FaultLevel 0 "No Fault" 2 "Level2: Serous Fault " 3 "Level3: Fatal Fault" ;
VAL_TABLE_ Rolling_Counter_0x20A 15 "Invalid" ;
VAL_TABLE_ DCFC_Voltage_Input 1023 "Invalid" ;
VAL_TABLE_ DCDC_PTC_Temp_Reserved 255 "Invalid" ;
VAL_TABLE_ DCFC_Neg_Temp_BusBar 255 "Invalid" ;
VAL_TABLE_ DCFC_STATE 0 "DCFC_Contactors_Open_e" 1 "DCFC_Contactors_Closing" 2 "DCFC_Contactors_Close" 3 "DCFC_Contactors_Opening" 4 "DCFC_Contactors_Weld" 7 "DCFC_SNA" ;
VAL_TABLE_ DCFC_PTC_Status_Reserved 3 "invalid" 2 "reserved" 1 "ON" 0 "OFF" ;
VAL_TABLE_ Rolling_Counter_0x3E0 15 "Invalid" ;
VAL_TABLE_ EVCC_IPC_Ack_ChgSche_stt 0 "Disabled" 1 "Enabled" 2 "Reserved" 3 "Invalid" ;
VAL_TABLE_ Rolling_Counter_0x2D5 15 "Invalid" ;
VAL_TABLE_ VCU_DCDC_Output_REQ 0 "Disable" 1 "Enable" ;
VAL_TABLE_ VCU_DCDC_OutVoltage_REQ 65535 "Invalid" ;
VAL_TABLE_ VCU_DCDCAllowedPower 65535 "Invalid" ;
VAL_TABLE_ Rolling_Counter_0x2A1 15 "Invalid" ;
VAL_TABLE_ EVCC_ChargeGunSts 1 "Plug In" 0 "no Plug in" ;
VAL_TABLE_ EVCC_VehicleFailureLevel 0 "Normal" 1 "Slight Fault" 2 "Minor fault" 3 "General fault" 4 "Serious Fault" 5 "Fatal fault" ;
VAL_TABLE_ EVCC_ChargeMode 2 "DC Mode " 1 "AC Mode " 0 "Default" ;
VAL_TABLE_ EVCC_CP_Sts 12 "F~" 11 "E~" 10 "D~" 9 "C~" 8 "B~" 7 "A~" 6 "F" 5 "E" 4 "D" 3 "C" 2 "B" 1 "A" 0 "No CP" ;
VAL_TABLE_ EVCC_PP_Value 7 "CC GND" 6 "1500" 5 "680" 4 "220" 3 "100" 2 "Connection" 1 "Half Connection " 0 "No Connection" ;
VAL_TABLE_ EVCC_Lock_Sts 4 "Error" 3 "Unlocking" 2 "Locked" 1 "Locking " 0 "Unlock" ;
VAL_TABLE_ EVCC_DCFCPortsTempErr 1 "Error" 0 "Normal" ;
VAL_TABLE_ Rolling_Counter_0x2AA 15 "Invalid" ;
VAL_TABLE_ EVCC_PLC_CommSts 2 "PLC communication Fail" 1 "PLC communication Success" 0 "No PLC communication" ;
VAL_TABLE_ EVCC_DC_ChargeProcess 10 "Charge Error" 9 "After Charge" 8 "Charge Stoping" 7 "Charging" 6 "Precharge waiting" 5 "Insulation Monitor From Charge Station" 4 "Information exchange" 3 "Charging authentication" 2 "TCP Connecting" 1 "PLC Linking" 0 "No Charge" ;
VAL_TABLE_ EVCC_BMS_InsulationMonReq 1 "off" 0 "on" ;
VAL_TABLE_ Rolling_Counter_0x2AB 15 "Invalid" ;
VAL_TABLE_ EVCC_OBC_PowerReq 127 "Invalid" ;
VAL_TABLE_ EVCC_OBC_VoltageReq 8191 "Invalid" ;
VAL_TABLE_ EVCC_OBC_CurrentReq 1023 "Invalid" ;
VAL_TABLE_ EVCC_OBC_Control 1 "enable" 0 "disable" ;
VAL_TABLE_ EVCC_AC_ChargeSts 4 "Charge Err" 3 "Afer Charge" 2 "Charge Stoping" 1 "Charging " 0 "No charge" ;
VAL_TABLE_ Rolling_Counter_0x219 15 "Invalid" ;
VAL_TABLE_ EVCC_ChargeAllow 1 "Allow " 0 "Not allow" ;
VAL_TABLE_ Rolling_Counter_0x2F5 15 "Invalid" ;
VAL_TABLE_ EVCC_Charge_Control 0 "Request Open" 1 "Request Close" ;
VAL_TABLE_ EVCC_DC_chargeSock_temp1 2047 "Invaild" ;
VAL_TABLE_ EVCC_DC_chargeSock_temp2 2047 "Invaild" ;
VAL_TABLE_ EVCC_ChargeIndicatorCtrlSts_Red 3 "Red light always on" 2 "Green light always on" 1 "green light flashing" 0 "closed" ;
VAL_TABLE_ EVCC_ChargeIndicatorSts_Red 1 "Error" 0 "NO Error" ;
VAL_TABLE_ Rolling_Counter_0x356 15 "Invalid" ;
VAL_TABLE_ OBC_WorkStatus 7 "CHG_LOCK_FAULT_STATE " 6 "CHG_RECV_FAULT_STATE " 5 " CHG_SLEEP_STATE" 4 "CHG_CHARG_OVER_STATE" 3 "CHG_CHARG_CV_STATE" 2 "CHG_CHARG_CC_STATE" 1 "CHG_STANDBY_STATE" 0 "Initial" ;
VAL_TABLE_ OBC_Sys_STS 3 "fault" 2 "warning" 1 "ok" 0 "init" ;
VAL_TABLE_ OBC_StartStatus 1 "Close Output" 0 "Start Output" ;
VAL_TABLE_ Rolling_Counter_0x366 15 "Invalid" ;
VAL_TABLE_ OBC_Charge_air_temp 255 "Invalid" ;
VAL_TABLE_ OBC_Temp 255 "Invalid" ;
VAL_TABLE_ Rolling_Counter_0x275 15 "Invalid" ;
VAL_TABLE_ OBC_OUT_DC_V 65535 "Invalid" ;
VAL_TABLE_ OBC_OUT_DC_I 16383 "Invalid" ;
VAL_TABLE_ OBC_DCCharge_line_V 65535 "Invalid" ;
VAL_TABLE_ Rolling_Counter_0x276 15 "Invalid" ;
VAL_TABLE_ OBC_Input_U 65535 "Invalid" ;
VAL_TABLE_ OBC_IN_Main_V 65535 "Invalid" ;
VAL_TABLE_ OBC_IN_Main_I 1023 "Invalid" ;
VAL_TABLE_ Rolling_Counter_0x296 15 "Invalid" ;
VAL_TABLE_ OBC_MaxOutputChgU 8191 "Invalid" ;
VAL_TABLE_ OBC_MaxOutputChgI 511 "Invalid" ;
VAL_TABLE_ OBC_MaxOutputPwr 127 "Invalid" ;
VAL_TABLE_ OBC_FailGrade_ERR 5 "Level5,Fatal fault" 4 "Level4,Serious fault" 3 "Level3,General fault" 2 "Level2,Minor fault" 1 "Level1,slight fault" 0 "No Fault" ;
VAL_TABLE_ OBC_ErrorFlag 11 "FAULT_MUTEX " 10 "FAULT_OUT_OV " 9 "FAULT_OUT_UV" 8 "FAULT_PFC_UVPFC" 7 "FAULT_PFC_OVPFC" 6 "FAULT_IN_OV" 5 "FAULT_IN_UV" 4 "FAULT_COMM_OUT" 3 "FAULT_OUT_OC " 2 " FAULT_OTP_ALL " 1 "FAULT_OTP_RT " 0 "Initial" ;
VAL_TABLE_ OBC_Hardware_ERR 1 "Error" 0 "Normal" ;
VAL_TABLE_ OBC_OTemp_ERR 2 "Level2 - stop" 1 "Level1 - limit" 0 "Normal" ;
VAL_TABLE_ OBC_OCofOut_ERR 1 "Error" 0 "Normal" ;
VAL_TABLE_ OBC_CANcomoverT_ERR 1 "Error" 0 "Normal" ;
VAL_TABLE_ OBC_UVofIn_ERR 1 "Error" 0 "Normal" ;
VAL_TABLE_ OBC_OVofIn_ERR 1 "Error" 0 "Normal" ;
VAL_TABLE_ OBC_OVofPFC_ERR 1 "Error" 0 "Normal" ;
VAL_TABLE_ OBC_UVofPFC_ERR 1 "Error" 0 "Normal" ;
VAL_TABLE_ OBC_UVofOut_ERR 1 "Error" 0 "Normal" ;
VAL_TABLE_ OBC_OVofOut_ERR 1 "Error" 0 "Normal" ;

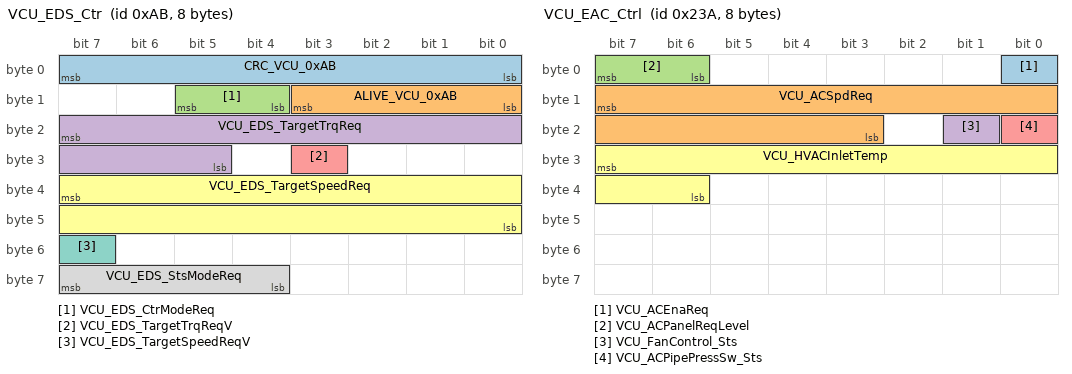
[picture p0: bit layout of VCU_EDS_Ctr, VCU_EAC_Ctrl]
BO_ 171 VCU_EDS_Ctr: 8 VCU
 SG_ CRC_VCU_0xAB : 7|8@0+ (1,0) [0|255] ""  EDS,EVCC
 SG_ ALIVE_VCU_0xAB : 11|4@0+ (1,0) [0|15] ""  EDS,EVCC
 SG_ VCU_EDS_CtrModeReq : 13|2@0+ (1,0) [0|3] ""  EDS,EVCC
 SG_ VCU_EDS_TargetTrqReq : 23|11@0+ (0.5,-500) [-500|500] "Nm"  EDS,EVCC
 SG_ VCU_EDS_TargetTrqReqV : 27|1@0+ (1,0) [0|1] ""  EDS,EVCC
 SG_ VCU_EDS_TargetSpeedReq : 39|16@0+ (1,-20000) [-20000|45535] "rpm"  EDS,EVCC
 SG_ VCU_EDS_TargetSpeedReqV : 55|1@0+ (1,0) [0|1] ""  EDS,EVCC
 SG_ VCU_EDS_StsModeReq : 63|4@0+ (1,0) [0|15] ""  EDS,EVCC

BO_ 570 VCU_EAC_Ctrl: 8 VCU
 SG_ VCU_ACEnaReq : 0|1@0+ (1,0) [0|1] ""  EAC,EVCC
 SG_ VCU_ACSpdReq : 15|13@0+ (1,0) [0|8000] "rpm"  EAC,EVCC
 SG_ VCU_ACPanelReqLevel : 7|2@0+ (1,0) [0|3] ""  EAC,EVCC
 SG_ VCU_FanControl_Sts : 17|1@0+ (1,0) [0|1] ""  EAC,EVCC
 SG_ VCU_ACPipePressSw_Sts : 16|1@0+ (1,0) [0|1] ""  EAC,EVCC
 SG_ VCU_HVACInletTemp : 31|10@0+ (0.1,-20) [-20|80] "degree"  EAC,EVCC

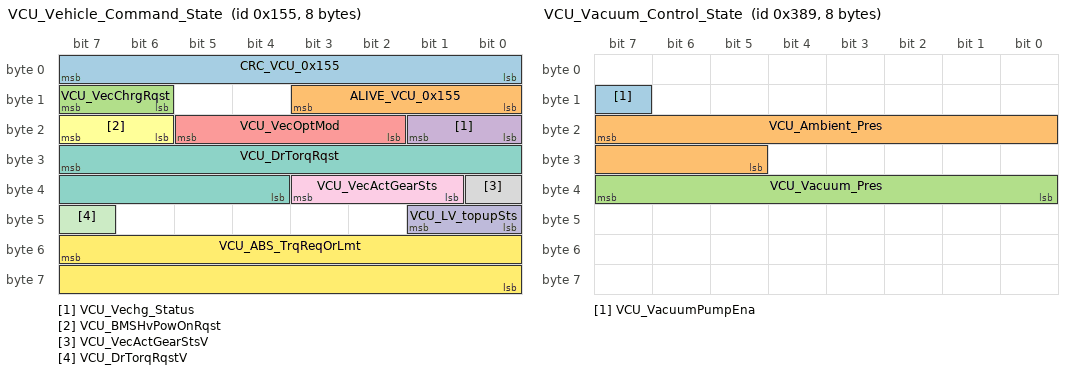
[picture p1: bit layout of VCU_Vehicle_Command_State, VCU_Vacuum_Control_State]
BO_ 341 VCU_Vehicle_Command_State: 8 VCU
 SG_ CRC_VCU_0x155 : 7|8@0+ (1,0) [0|255] ""  EDS,BMS,EVCC,OBC
 SG_ ALIVE_VCU_0x155 : 11|4@0+ (1,0) [0|15] ""  EDS,BMS,EVCC,OBC
 SG_ VCU_VecChrgRqst : 15|2@0+ (1,0) [0|3] ""  EDS,EVCC,OBC
 SG_ VCU_Vechg_Status : 17|2@0+ (1,0) [0|3] ""  EDS,EVCC,OBC
 SG_ VCU_VecOptMod : 21|4@0+ (1,0) [0|15] ""  EDS,BMS,DCDC,EVCC,OBC
 SG_ VCU_BMSHvPowOnRqst : 23|2@0+ (1,0) [0|3] ""  EDS,BMS,EVCC,OBC
 SG_ VCU_DrTorqRqst : 31|12@0+ (0.25,-511) [-511|511] "Nm"  EDS,EVCC,OBC
 SG_ VCU_VecActGearStsV : 32|1@0+ (1,0) [0|1] ""  EDS,EVCC,OBC
 SG_ VCU_VecActGearSts : 35|3@0+ (1,0) [0|7] ""  EDS,EVCC,OBC
 SG_ VCU_LV_topupSts : 41|2@0+ (1,0) [0|3] ""  EDS,EVCC,OBC
 SG_ VCU_DrTorqRqstV : 47|1@0+ (1,0) [0|1] ""  EDS,EVCC,OBC
 SG_ VCU_ABS_TrqReqOrLmt : 55|16@0+ (0.1,-2000) [-2000|2000] "Nm"  EDS,EVCC,OBC

BO_ 1221 VCU_Status: 8 VCU
 SG_ CRC_VCU_0x4C5 : 7|8@0+ (1,0) [0|255] ""  EDS,EPS,EVCC
 SG_ ALIVE_VCU_0x4C5 : 11|4@0+ (1,0) [0|15] ""  EDS,EPS,EVCC
 SG_ VCU_CreepDisable_stt : 13|1@0+ (1,0) [0|1] ""  EDS,EPS,EVCC
 SG_ VCU_RDCSts : 14|1@0+ (1,0) [0|1] ""  EDS,EPS,EVCC
 SG_ VCU_RBCSts : 15|1@0+ (1,0) [0|1] ""  EDS,EPS,EVCC
 SG_ VCU_BrkPedalSWSts : 17|2@0+ (1,0) [0|3] ""  EDS,EPS,EVCC
 SG_ Brakefluid_levelSts : 19|2@0+ (1,0) [0|3] ""  EDS,EPS,EVCC
 SG_ VCU_HandBrakeSts : 20|1@0+ (1,0) [0|1] ""  EDS,EPS,EVCC
 SG_ VCU_RegenLevelfeed : 21|1@0+ (1,0) [0|1] ""  EDS,EPS,EVCC
 SG_ VCU_PowerLimit : 22|1@0+ (1,0) [0|1] ""  EDS,EPS,EVCC
 SG_ VCU_AccPedaPosValid : 23|1@0+ (1,0) [0|1] ""  EDS,EPS,EVCC
 SG_ VCU_AccPedaPos : 31|8@0+ (1,0) [0|100] "%"  EDS,EPS,EVCC
 SG_ VCU_VehicleHVStatus : 33|2@0+ (1,0) [0|3] ""  EDS,EPS,EVCC
 SG_ VCUVacuumPresWrn : 35|2@0+ (1,0) [0|3] ""  EDS,EPS,EVCC
 SG_ VCUVacuumSts : 37|2@0+ (1,0) [0|3] ""  EDS,EPS,EVCC
 SG_ VCU_InstantPowerConsump : 47|10@0+ (0.1,0) [0|100] "kwh/100km"  EDS,EPS,EVCC
 SG_ VCU_AveragePowerConsump : 53|10@0+ (0.1,0) [0|100] "kwh/100km"  EDS,EPS,EVCC
 SG_ VCU_LowSOCWarning : 56|1@0+ (1,0) [0|1] ""  EDS,EPS,EVCC
 SG_ VCU_TqReductionRqstResponse : 57|1@0+ (1,0) [0|1] ""  EDS,EPS,EVCC
 SG_ VCU_DrvModeSts : 59|2@0+ (1,0) [0|3] ""  EDS,EPS,EVCC

BO_ 905 VCU_Vacuum_Control_State: 8 VCU
 SG_ VCU_VacuumPumpEna : 15|1@0+ (1,0) [0|1] "" Vector__XXX
 SG_ VCU_Ambient_Pres : 23|11@0+ (0.1,0) [0|150] "kPa" Vector__XXX
 SG_ VCU_Vacuum_Pres : 39|8@0+ (1,-150) [-150|50] "kPa" Vector__XXX

BO_ 1145 VCU_Error_0x479: 8 VCU
 SG_ VCU_FaultCode : 7|8@0+ (1,0) [0|255] ""  EVCC
 SG_ VCU_VehicleFailureLevel : 10|3@0+ (1,0) [0|7] ""  EVCC
 SG_ VCU_EDSCAN_ERR : 16|1@0+ (1,0) [0|1] ""  EVCC
 SG_ VCU_BmsCAN_ERR : 17|1@0+ (1,0) [0|1] ""  EVCC
 SG_ VCU_DcdcCAN_ERR : 18|1@0+ (1,0) [0|1] ""  EVCC
 SG_ VCU_AbsCAN_ERR : 19|1@0+ (1,0) [0|1] ""  EVCC
 SG_ VCU_ACUCAN_ERR : 20|1@0+ (1,0) [0|1] ""  EVCC
 SG_ VCU_BcmCAN_ERR_reserved : 21|1@0+ (1,0) [0|1] ""  EVCC
 SG_ VCU_BrakeSys_Err : 22|1@0+ (1,0) [0|1] ""  EVCC
 SG_ VCU_AccPed_ERR : 23|1@0+ (1,0) [0|1] ""  EVCC
 SG_ VCU_Shift_ERR : 24|1@0+ (1,0) [0|1] ""  EVCC
 SG_ VCU_EPSCAN_ERR : 25|1@0+ (1,0) [0|1] ""  EVCC
 SG_ VCU_EvccCAN_ERR : 26|1@0+ (1,0) [0|1] ""  EVCC
 SG_ VCU_FlgHVIL_ERR : 27|1@0+ (1,0) [0|1] ""  EVCC
 SG_ VCU_ObcCAN_ERR : 41|1@0+ (1,0) [0|1] ""  EVCC
 SG_ VCU_SSCAN_ERR : 39|1@0+ (1,0) [0|1] ""  EVCC
 SG_ VCU_EacCAN_ERR : 38|1@0+ (1,0) [0|1] ""  EVCC
 SG_ VCU_AccPedalOutRange : 40|1@0+ (1,0) [0|1] ""  EVCC

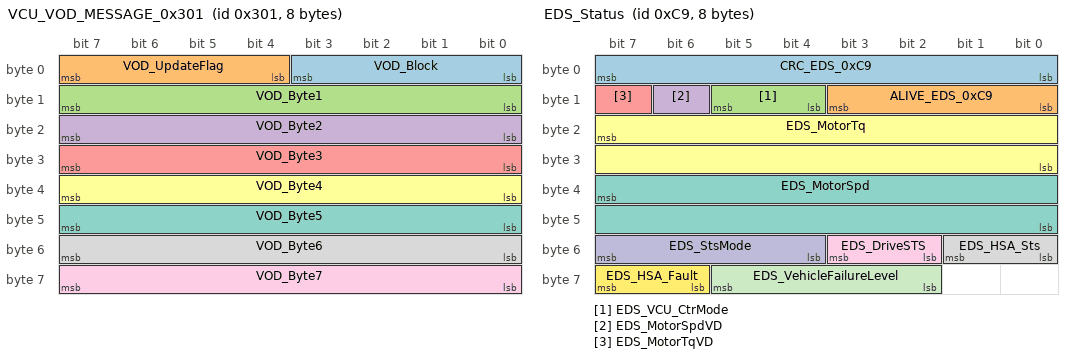
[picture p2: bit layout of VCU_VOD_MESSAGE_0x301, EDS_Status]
BO_ 769 VCU_VOD_MESSAGE_0x301: 8 VCU
 SG_ VOD_Block : 3|4@0+ (1,0) [0|7] "" Vector__XXX
 SG_ VOD_UpdateFlag : 7|4@0+ (1,0) [0|7] "" Vector__XXX
 SG_ VOD_Byte1 : 15|8@0+ (1,0) [0|255] "" Vector__XXX
 SG_ VOD_Byte2 : 23|8@0+ (1,0) [0|255] "" Vector__XXX
 SG_ VOD_Byte3 : 31|8@0+ (1,0) [0|255] "" Vector__XXX
 SG_ VOD_Byte4 : 39|8@0+ (1,0) [0|255] "" Vector__XXX
 SG_ VOD_Byte5 : 47|8@0+ (1,0) [0|255] "" Vector__XXX
 SG_ VOD_Byte6 : 55|8@0+ (1,0) [0|255] "" Vector__XXX
 SG_ VOD_Byte7 : 63|8@0+ (1,0) [0|255] "" Vector__XXX

BO_ 201 EDS_Status: 8 EDS
 SG_ CRC_EDS_0xC9 : 7|8@0+ (1,0) [0|255] ""  VCU,EVCC
 SG_ ALIVE_EDS_0xC9 : 11|4@0+ (1,0) [0|15] ""  VCU,EVCC
 SG_ EDS_VCU_CtrMode : 13|2@0+ (1,0) [0|3] ""  VCU,EVCC
 SG_ EDS_MotorSpdVD : 14|1@0+ (1,0) [0|1] ""  VCU,EVCC
 SG_ EDS_MotorTqVD : 15|1@0+ (1,0) [0|1] ""  VCU,EVCC
 SG_ EDS_MotorTq : 23|16@0+ (0.1,-1200) [-1200|1200] "Nm"  VCU,EVCC
 SG_ EDS_MotorSpd : 39|16@0+ (1,-20000) [-20000|45531] "rpm"  VCU,EVCC
 SG_ EDS_HSA_Sts : 49|2@0+ (1,0) [0|3] ""  VCU,EVCC
 SG_ EDS_DriveSTS : 51|2@0+ (1,0) [0|3] ""  VCU,EVCC
 SG_ EDS_StsMode : 55|4@0+ (1,0) [0|15] ""  VCU,EVCC
 SG_ EDS_VehicleFailureLevel : 61|4@0+ (1,0) [0|7] ""  VCU,EVCC
 SG_ EDS_HSA_Fault : 63|2@0+ (1,0) [0|3] ""  VCU,EVCC

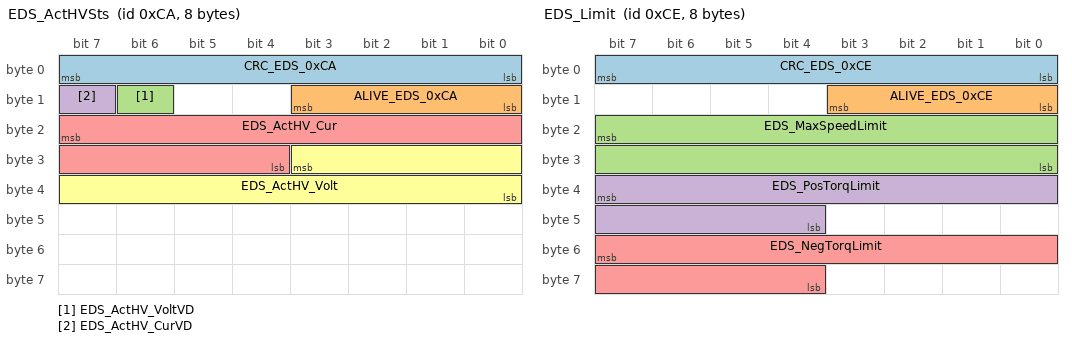
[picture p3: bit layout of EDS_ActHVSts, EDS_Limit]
BO_ 202 EDS_ActHVSts: 8 EDS
 SG_ CRC_EDS_0xCA : 7|8@0+ (1,0) [0|255] ""  VCU,EVCC
 SG_ ALIVE_EDS_0xCA : 11|4@0+ (1,0) [0|15] ""  VCU,EVCC
 SG_ EDS_ActHV_VoltVD : 14|1@0+ (1,0) [0|1] ""  VCU,EVCC
 SG_ EDS_ActHV_CurVD : 15|1@0+ (1,0) [0|1] ""  VCU,EVCC
 SG_ EDS_ActHV_Cur : 23|12@0+ (0.5,-1000) [-1000|1000] "A"  VCU,EVCC
 SG_ EDS_ActHV_Volt : 27|12@0+ (0.5,0) [0|1000] "V"  VCU,EVCC

BO_ 206 EDS_Limit: 8 EDS
 SG_ CRC_EDS_0xCE : 7|8@0+ (1,0) [0|255] ""  VCU
 SG_ ALIVE_EDS_0xCE : 11|4@0+ (1,0) [0|15] ""  VCU
 SG_ EDS_MaxSpeedLimit : 23|16@0+ (1,-20000) [-20000|20000] "rpm"  VCU
 SG_ EDS_PosTorqLimit : 39|12@0+ (0.1,0) [0|400] "Nm"  VCU
 SG_ EDS_NegTorqLimit : 55|12@0+ (0.1,-400) [-400|0] "Nm"  VCU

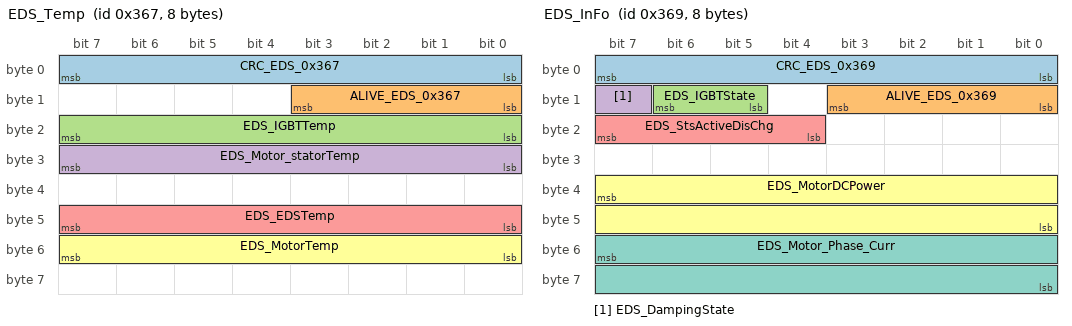
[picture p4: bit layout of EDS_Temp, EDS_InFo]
BO_ 871 EDS_Temp: 8 EDS
 SG_ CRC_EDS_0x367 : 7|8@0+ (1,0) [0|255] ""  VCU
 SG_ ALIVE_EDS_0x367 : 11|4@0+ (1,0) [0|15] ""  VCU
 SG_ EDS_IGBTTemp : 23|8@0+ (1,-40) [-40|210] "" Vector__XXX
 SG_ EDS_Motor_statorTemp : 31|8@0+ (1,-40) [-40|210] "" Vector__XXX
 SG_ EDS_EDSTemp : 47|8@0+ (1,-40) [-40|210] "" Vector__XXX
 SG_ EDS_MotorTemp : 55|8@0+ (1,-40) [-40|210] "" Vector__XXX

BO_ 872 EDS_Fault: 8 EDS
 SG_ EDS_MotTempSenFault : 0|1@0+ (1,0) [0|1] ""  VCU,EVCC
 SG_ EDS_EDSOverTempAlarm : 4|1@0+ (1,0) [0|1] ""  VCU,EVCC
 SG_ EDS_EDSOverTempFault : 5|1@0+ (1,0) [0|1] ""  VCU,EVCC
 SG_ EDS_LV_VotagtFault : 6|1@0+ (1,0) [0|1] ""  VCU,EVCC
 SG_ EDS_PhashOverCurrentSWFault : 7|1@0+ (1,0) [0|1] ""  VCU,EVCC
 SG_ EDS_EDSCurrentSenVFault : 8|1@0+ (1,0) [0|1] ""  VCU,EVCC
 SG_ EDS_EDSCurrentSenWFault : 9|1@0+ (1,0) [0|1] ""  VCU,EVCC
 SG_ EDS_EDSHVOverVoltageAlarm : 10|1@0+ (1,0) [0|1] ""  VCU,EVCC
 SG_ EDS_EDSHVOverVoltageFault : 11|1@0+ (1,0) [0|1] ""  VCU,EVCC
 SG_ EDS_EDSHVUnderVoltageAlarm : 12|1@0+ (1,0) [0|1] ""  VCU,EVCC
 SG_ EDS_EDSHVUnderVoltageFault : 13|1@0+ (1,0) [0|1] ""  VCU,EVCC
 SG_ EDS_MotOverTempAlarm : 14|1@0+ (1,0) [0|1] ""  VCU,EVCC
 SG_ EDS_MotOverTempFault : 15|1@0+ (1,0) [0|1] ""  VCU,EVCC
 SG_ EDS_EDSDisChgFault : 16|1@0+ (1,0) [0|1] ""  VCU,EVCC
 SG_ EDS_EDSHVSenFault : 17|1@0+ (1,0) [0|1] ""  VCU,EVCC
 SG_ EDS_12VOverVoltageAlarm : 18|1@0+ (1,0) [0|1] ""  VCU,EVCC
 SG_ EDS_12VUnderVoltageAlarm : 19|1@0+ (1,0) [0|1] ""  VCU,EVCC
 SG_ EDS_MotOverAlarm : 20|1@0+ (1,0) [0|1] ""  VCU,EVCC
 SG_ EDS_MotOverFault : 21|1@0+ (1,0) [0|1] ""  VCU,EVCC
 SG_ EDS_PhashOverCurrentHWFault : 22|1@0+ (1,0) [0|1] ""  VCU,EVCC
 SG_ EDS_EDSCurrentSenUFault : 23|1@0+ (1,0) [0|1] ""  VCU,EVCC
 SG_ EDS_VCULostFault : 24|1@0+ (1,0) [0|1] ""  VCU,EVCC
 SG_ EDS_BMSLostFault : 25|1@0+ (1,0) [0|1] ""  VCU,EVCC
 SG_ EDS_MotRotSenFault : 26|1@0+ (1,0) [0|1] ""  VCU,EVCC
 SG_ EDS_MotBlockedFault : 27|1@0+ (1,0) [0|1] ""  VCU,EVCC
 SG_ EDS_EDSChksumFault : 28|1@0+ (1,0) [0|1] ""  VCU,EVCC
 SG_ EDS_MotTrqLimtFault : 29|1@0+ (1,0) [0|1] ""  VCU,EVCC
 SG_ EDS_VCUChksumFault : 30|1@0+ (1,0) [0|1] ""  VCU,EVCC
 SG_ EDS_EDSEnableFault : 31|1@0+ (1,0) [0|1] ""  VCU,EVCC
 SG_ EDS_IGBTFault : 38|1@0+ (1,0) [0|1] ""  VCU,EVCC
 SG_ EDS_CANBUSOFFFault : 39|1@0+ (1,0) [0|1] ""  VCU,EVCC
 SG_ EDS_EDSTempSensorErr : 43|1@0+ (1,0) [0|1] ""  VCU,EVCC
 SG_ EDS_HWCapOverVolt : 44|1@0+ (1,0) [0|1] ""  VCU,EVCC
 SG_ EDS_SWCapOverVolt : 45|1@0+ (1,0) [0|1] ""  VCU,EVCC
 SG_ EDS_EDSMemoryFlt : 46|1@0+ (1,0) [0|1] ""  VCU,EVCC
 SG_ EDS_InitMode : 47|1@0+ (1,0) [0|1] ""  VCU,EVCC
 SG_ EDS_MotorSN : 51|4@0+ (1,0) [0|1] ""  VCU,EVCC
 SG_ EDS_EDSFaultCode : 63|8@0+ (1,0) [0|255] ""  VCU,EVCC

BO_ 873 EDS_InFo: 8 EDS
 SG_ CRC_EDS_0x369 : 7|8@0+ (1,0) [0|255] ""  VCU
 SG_ ALIVE_EDS_0x369 : 11|4@0+ (1,0) [0|15] ""  VCU
 SG_ EDS_IGBTState : 14|2@0+ (1,0) [0|3] ""  VCU
 SG_ EDS_DampingState : 15|1@0+ (1,0) [0|1] ""  VCU
 SG_ EDS_StsActiveDisChg : 23|4@0+ (1,0) [0|3] ""  VCU
 SG_ EDS_MotorDCPower : 39|16@0+ (0.1,-1000) [-1000|1000] "Kw"  VCU
 SG_ EDS_Motor_Phase_Curr : 55|16@0+ (0.05,-1600) [-1600|1612.75] "A"  VCU

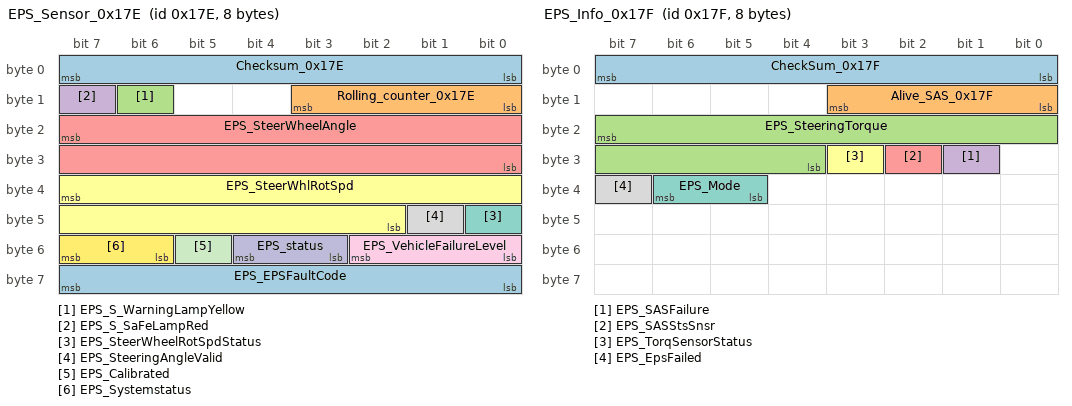
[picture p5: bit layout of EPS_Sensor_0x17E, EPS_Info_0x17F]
BO_ 382 EPS_Sensor_0x17E: 8 EPS
 SG_ Checksum_0x17E : 7|8@0+ (1,0) [0|255] ""  VCU
 SG_ Rolling_counter_0x17E : 11|4@0+ (1,0) [0|15] ""  VCU
 SG_ EPS_S_WarningLampYellow : 14|1@0+ (1,0) [0|1] ""  VCU
 SG_ EPS_S_SaFeLampRed : 15|1@0+ (1,0) [0|1] ""  VCU
 SG_ EPS_SteerWheelAngle : 23|16@0+ (0.0238,-780) [-780|779.7] "deg"  VCU
 SG_ EPS_SteerWhlRotSpd : 39|14@0+ (0.125,-1024) [-1024|1023.75] "degs"  VCU
 SG_ EPS_SteerWheelRotSpdStatus : 40|1@0+ (1,0) [0|1] ""  VCU
 SG_ EPS_SteeringAngleValid : 41|1@0+ (1,0) [0|1] ""  VCU
 SG_ EPS_VehicleFailureLevel : 50|3@0+ (1,0) [0|7] ""  VCU
 SG_ EPS_status : 52|2@0+ (1,0) [0|3] ""  VCU
 SG_ EPS_Calibrated : 53|1@0+ (1,0) [0|1] ""  VCU
 SG_ EPS_Systemstatus : 55|2@0+ (1,0) [0|3] ""  VCU
 SG_ EPS_EPSFaultCode : 63|8@0+ (1,0) [0|63] ""  VCU

BO_ 383 EPS_Info_0x17F: 8 EPS
 SG_ CheckSum_0x17F : 7|8@0+ (1,0) [0|255] ""  VCU
 SG_ Alive_SAS_0x17F : 11|4@0+ (1,0) [0|15] ""  VCU
 SG_ EPS_SteeringTorque : 23|12@0+ (0.01,-10.24) [-10.24|10.23] "N*m"  VCU
 SG_ EPS_SASFailure : 25|1@0+ (1,0) [0|1] ""  VCU
 SG_ EPS_SASStsSnsr : 26|1@0+ (1,0) [0|1] ""  VCU
 SG_ EPS_TorqSensorStatus : 27|1@0+ (1,0) [0|1] ""  VCU
 SG_ EPS_Mode : 38|2@0+ (1,0) [0|3] ""  VCU
 SG_ EPS_EpsFailed : 39|1@0+ (1,0) [0|1] ""  VCU

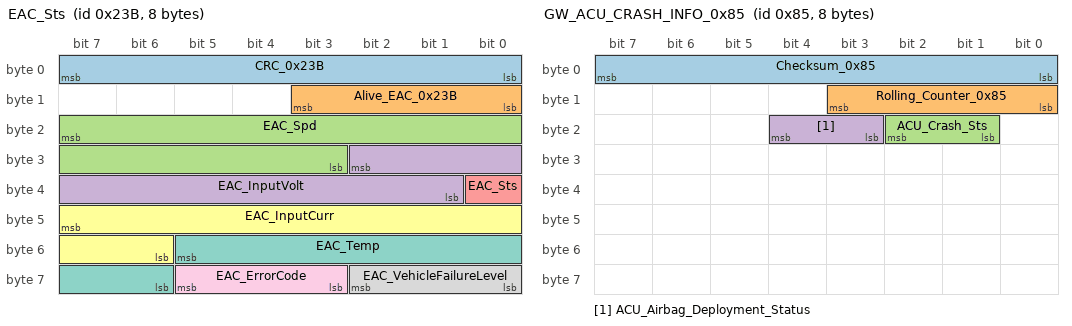
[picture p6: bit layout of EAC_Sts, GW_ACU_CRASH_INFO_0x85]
BO_ 571 EAC_Sts: 8 EAC
 SG_ CRC_0x23B : 7|8@0+ (1,0) [0|255] ""  VCU,EVCC
 SG_ Alive_EAC_0x23B : 11|4@0+ (1,0) [0|15] ""  VCU,EVCC
 SG_ EAC_Spd : 23|13@0+ (1,0) [0|6000] "rpm"  VCU,EVCC
 SG_ EAC_InputVolt : 26|10@0+ (0.5,0) [0|500] "V"  VCU,EVCC
 SG_ EAC_Sts : 32|1@0+ (1,0) [0|1] ""  VCU,EVCC
 SG_ EAC_InputCurr : 47|10@0+ (0.1,0) [0|100] "A"  VCU,EVCC
 SG_ EAC_Temp : 53|8@0+ (1,0) [0|150] ""  EVCC
 SG_ EAC_VehicleFailureLevel : 58|3@0+ (1,0) [0|7] ""  VCU,EVCC
 SG_ EAC_ErrorCode : 61|3@0+ (1,0) [0|7] ""  VCU,EVCC

BO_ 1249 EAC_SW_VersionP1: 8 EAC
 SG_ SW_Group_ID : 7|24@0+ (1,0) [0|16777215] "" Vector__XXX
 SG_ SW_Base_Number : 31|32@0+ (1,0) [0|4294967295] "" Vector__XXX

BO_ 1253 EAC_SW_VersionP2: 8 EAC
 SG_ SW_Major_Version_Number : 7|16@0+ (1,0) [0|65535] "" Vector__XXX
 SG_ SW_Minor_Version_Number : 23|8@0+ (1,0) [0|255] "" Vector__XXX

BO_ 1257 EAC_HW_VersionP1: 8 EAC
 SG_ HW_Group_ID : 7|24@0+ (1,0) [0|16777215] "" Vector__XXX
 SG_ HW_Base_Number : 31|32@0+ (1,0) [0|4294967295] "" Vector__XXX

BO_ 1259 EAC_HW_VersionP2: 8 EAC
 SG_ HW_Major_Version_Number : 7|16@0+ (1,0) [0|65535] "" Vector__XXX
 SG_ HW_Minor_Version_Number : 23|8@0+ (1,0) [0|255] "" Vector__XXX

BO_ 133 GW_ACU_CRASH_INFO_0x85: 8 VCU
 SG_ Checksum_0x85 : 7|8@0+ (1,0) [0|255] ""  EDS,BMS,EVCC
 SG_ Rolling_Counter_0x85 : 11|4@0+ (1,0) [0|15] ""  EDS,BMS,EVCC
 SG_ ACU_Crash_Sts : 18|2@0+ (1,0) [0|3] ""  EDS,BMS,EVCC
 SG_ ACU_Airbag_Deployment_Status : 20|2@0+ (1,0) [0|3] ""  EDS,BMS,EVCC

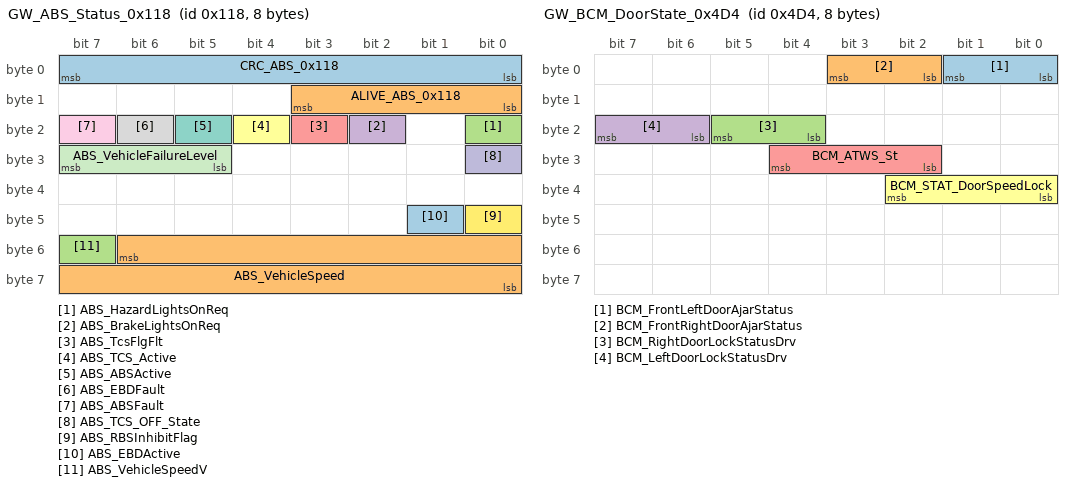
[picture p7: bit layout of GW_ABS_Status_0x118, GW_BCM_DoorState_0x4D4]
BO_ 280 GW_ABS_Status_0x118: 8 VCU
 SG_ CRC_ABS_0x118 : 7|8@0+ (1,0) [0|255] ""  EDS,EPS,BMS,DCDC,EVCC,OBC
 SG_ ALIVE_ABS_0x118 : 11|4@0+ (1,0) [0|15] ""  EDS,EPS,BMS,DCDC,EVCC,OBC
 SG_ ABS_HazardLightsOnReq : 16|1@0+ (1,0) [0|1] ""  EDS,EPS,BMS,DCDC,EVCC,OBC
 SG_ ABS_BrakeLightsOnReq : 18|1@0+ (1,0) [0|1] ""  EDS,EPS,BMS,DCDC,EVCC,OBC
 SG_ ABS_TcsFlgFlt : 19|1@0+ (1,0) [0|1] ""  EDS,EPS,BMS,DCDC,EVCC,OBC
 SG_ ABS_TCS_Active : 20|1@0+ (1,0) [0|1] ""  EDS,EPS,BMS,DCDC,EVCC,OBC
 SG_ ABS_ABSActive : 21|1@0+ (1,0) [0|1] ""  EDS,EPS,BMS,DCDC,EVCC,OBC
 SG_ ABS_EBDFault : 22|1@0+ (1,0) [0|1] ""  EDS,EPS,BMS,DCDC,EVCC,OBC
 SG_ ABS_ABSFault : 23|1@0+ (1,0) [0|1] ""  EDS,EPS,BMS,DCDC,EVCC,OBC
 SG_ ABS_TCS_OFF_State : 24|1@0+ (1,0) [0|1] ""  EDS,EPS,BMS,DCDC,EVCC,OBC
 SG_ ABS_VehicleFailureLevel : 31|3@0+ (1,0) [0|7] ""  EDS,EPS,BMS,DCDC,EVCC,OBC
 SG_ ABS_RBSInhibitFlag : 40|1@0+ (1,0) [0|1] ""  EDS,EPS,BMS,DCDC,EVCC,OBC
 SG_ ABS_EBDActive : 41|1@0+ (1,0) [0|1] ""  EDS,EPS,BMS,DCDC,EVCC,OBC
 SG_ ABS_VehicleSpeed : 54|15@0+ (0.015625,0) [0|360] "km/h"  EDS,EPS,BMS,DCDC,EVCC,OBC
 SG_ ABS_VehicleSpeedV : 55|1@0+ (1,0) [0|1] ""  EDS,EPS,BMS,DCDC,EVCC,OBC

BO_ 1236 GW_BCM_DoorState_0x4D4: 8 VCU
 SG_ BCM_FrontLeftDoorAjarStatus : 1|2@0+ (1,0) [0|1] ""  EDS,EVCC
 SG_ BCM_FrontRightDoorAjarStatus : 3|2@0+ (1,0) [0|1] ""  EDS,EVCC
 SG_ BCM_RightDoorLockStatusDrv : 21|2@0+ (1,0) [0|3] ""  EVCC
 SG_ BCM_LeftDoorLockStatusDrv : 23|2@0+ (1,0) [0|3] ""  EVCC
 SG_ BCM_ATWS_St : 28|3@0+ (1,0) [0|7] ""  EVCC
 SG_ BCM_STAT_DoorSpeedLock : 34|3@0+ (1,0) [0|7] ""  EVCC

BO_ 513 GW_BCM_Status_0x201: 8 VCU
 SG_ CRC_BCM_0x201 : 7|8@0+ (1,0) [0|255] ""  EAC,EDS,EPS,BMS,DCDC,EVCC,OBC
 SG_ ALIVE_BCM_0x201 : 11|4@0+ (1,0) [0|15] ""  EAC,EDS,EPS,BMS,DCDC,EVCC,OBC
 SG_ BCM_LV_topupReq : 15|4@0+ (1,0) [0|3] ""  EAC,EDS,EPS,BMS,DCDC,EVCC,OBC
 SG_ BCM_BatteryVoltage : 23|8@0+ (0.1,0) [0|25.4] "V"  EAC,EDS,EPS,BMS,DCDC,EVCC,OBC
 SG_ BCM_Key_CheckSts : 24|1@0+ (1,0) [0|1] ""  EAC,EDS,EPS,BMS,DCDC,EVCC,OBC
 SG_ BCM_Press_BrkPedal_Alert : 25|1@0+ (1,0) [0|1] ""  EAC,EDS,EPS,BMS,DCDC,EVCC,OBC
 SG_ BCM_EmergencyStop : 27|2@0+ (1,0) [0|3] ""  EAC,EDS,EPS,BMS,DCDC,EVCC,OBC
 SG_ BCM_IGN1RelayOutputSts : 29|2@0+ (1,0) [0|3] ""  EAC,EDS,EPS,BMS,DCDC,EVCC,OBC
 SG_ BCM_ACCRelayOutputSts : 31|2@0+ (1,0) [0|3] ""  EAC,EDS,EPS,BMS,DCDC,EVCC,OBC
 SG_ BCM_FLWIN_Postion_Reserved : 34|3@0+ (1,0) [0|7] ""  EAC,EDS,EPS,BMS,DCDC,EVCC,OBC
 SG_ BCM_KEY_MatchSts : 36|2@0+ (1,0) [0|3] ""  EAC,EDS,EPS,BMS,DCDC,EVCC,OBC
 SG_ BCM_FRWIN_Postion_Reserved : 39|3@0+ (1,0) [0|7] ""  EAC,EDS,EPS,BMS,DCDC,EVCC,OBC
 SG_ BCM_BCMFaultCode : 47|8@0+ (1,0) [0|255] ""  EAC,EDS,EPS,BMS,DCDC,EVCC,OBC
 SG_ BCM_PowerMode : 49|2@0+ (1,0) [0|3] ""  EAC,EDS,EPS,BMS,DCDC,EVCC,OBC
 SG_ BCM_BrakeSwSts : 51|2@0+ (1,0) [0|3] ""  EAC,EDS,EPS,BMS,DCDC,EVCC,OBC
 SG_ BCM_VehicleFailureLevel : 55|3@0+ (1,0) [0|7] ""  EAC,EDS,EPS,BMS,DCDC,EVCC,OBC
 SG_ BCM_Anti_theftAlarmSetSts : 57|2@0+ (1,0) [0|3] ""  EAC,EDS,EPS,BMS,DCDC,EVCC,OBC
 SG_ BCM_FMH_SetSts : 59|2@0+ (1,0) [0|3] ""  EAC,EDS,EPS,BMS,DCDC,EVCC,OBC
 SG_ BCM_IGN1RelayFaultSts : 61|2@0+ (1,0) [0|3] ""  EAC,EDS,EPS,BMS,DCDC,EVCC,OBC
 SG_ BCM_ACCRelayFaultSts : 63|2@0+ (1,0) [0|3] ""  EAC,EDS,EPS,BMS,DCDC,EVCC,OBC

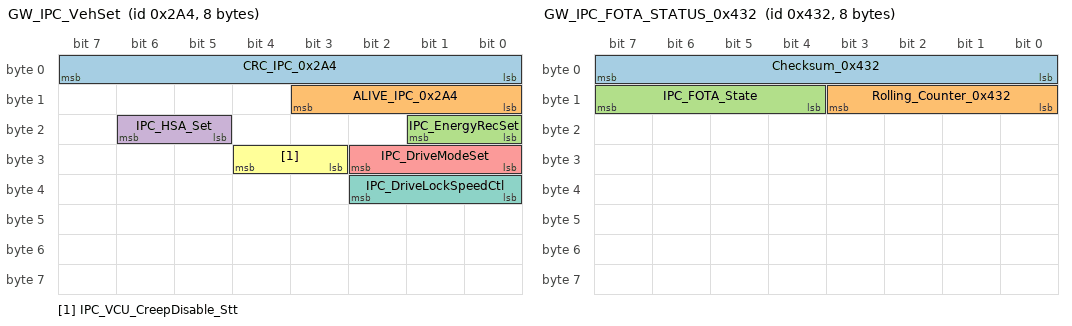
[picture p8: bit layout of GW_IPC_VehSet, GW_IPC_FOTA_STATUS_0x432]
BO_ 676 GW_IPC_VehSet: 8 VCU
 SG_ CRC_IPC_0x2A4 : 7|8@0+ (1,0) [0|255] "" Vector__XXX
 SG_ ALIVE_IPC_0x2A4 : 11|4@0+ (1,0) [0|15] "" Vector__XXX
 SG_ IPC_EnergyRecSet : 17|2@0+ (1,0) [0|3] "" Vector__XXX
 SG_ IPC_HSA_Set : 22|2@0+ (1,0) [0|3] ""  EDS
 SG_ IPC_DriveModeSet : 26|3@0+ (1,0) [0|7] "" Vector__XXX
 SG_ IPC_VCU_CreepDisable_Stt : 28|2@0+ (1,0) [0|3] "" Vector__XXX
 SG_ IPC_DriveLockSpeedCtl : 34|3@0+ (1,0) [0|7] "" Vector__XXX

BO_ 1074 GW_IPC_FOTA_STATUS_0x432: 8 VCU
 SG_ Checksum_0x432 : 7|8@0+ (1,0) [0|255] ""  EDS,EPS,BMS,DCDC,EVCC,OBC
 SG_ Rolling_Counter_0x432 : 11|4@0+ (1,0) [0|14] ""  EDS,EPS,BMS,DCDC,EVCC,OBC
 SG_ IPC_FOTA_State : 15|4@0+ (1,0) [0|14] ""  EDS,EPS,BMS,DCDC,EVCC,OBC

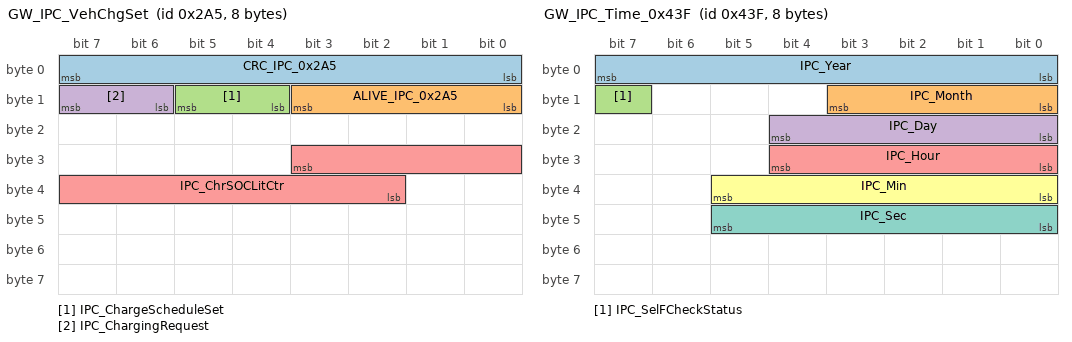
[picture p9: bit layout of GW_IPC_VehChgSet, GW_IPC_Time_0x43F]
BO_ 677 GW_IPC_VehChgSet: 8 VCU
 SG_ CRC_IPC_0x2A5 : 7|8@0+ (1,0) [0|255] ""  EVCC
 SG_ ALIVE_IPC_0x2A5 : 11|4@0+ (1,0) [0|15] ""  EVCC
 SG_ IPC_ChargeScheduleSet : 13|2@0+ (1,0) [0|3] ""  EVCC
 SG_ IPC_ChargingRequest : 15|2@0+ (1,0) [0|3] ""  EVCC
 SG_ IPC_ChrSOCLitCtr : 27|10@0+ (0.1,0) [0|1000] "%"  EVCC

BO_ 1087 GW_IPC_Time_0x43F: 8 VCU
 SG_ IPC_Year : 7|8@0+ (1,2000) [2000|2255] ""  EDS,EPS,BMS,DCDC,EVCC,OBC
 SG_ IPC_Month : 11|4@0+ (1,0) [1|12] ""  EDS,EPS,BMS,DCDC,EVCC,OBC
 SG_ IPC_SelFCheckStatus : 15|1@0+ (1,0) [0|1] ""  EDS,EPS,BMS,DCDC,EVCC,OBC
 SG_ IPC_Day : 20|5@0+ (1,0) [1|31] ""  EDS,EPS,BMS,DCDC,EVCC,OBC
 SG_ IPC_Hour : 28|5@0+ (1,0) [0|31] "hour"  EDS,EPS,BMS,DCDC,EVCC,OBC
 SG_ IPC_Min : 37|6@0+ (1,0) [0|63] "min"  EDS,EPS,BMS,DCDC,EVCC,OBC
 SG_ IPC_Sec : 45|6@0+ (1,0) [0|63] "second"  EDS,EPS,BMS,DCDC,EVCC,OBC

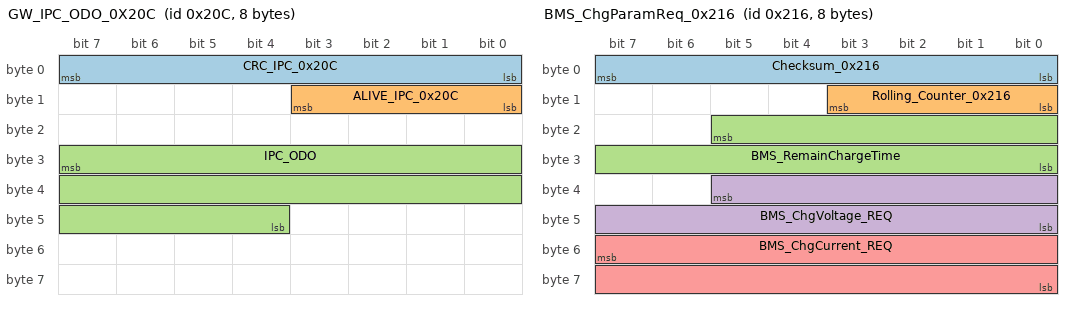
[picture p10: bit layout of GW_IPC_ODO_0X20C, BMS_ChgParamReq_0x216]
BO_ 524 GW_IPC_ODO_0X20C: 8 VCU
 SG_ CRC_IPC_0x20C : 7|8@0+ (1,0) [0|255] ""  BMS,DCDC,EVCC,OBC
 SG_ ALIVE_IPC_0x20C : 11|4@0+ (1,0) [0|15] ""  BMS,DCDC,EVCC,OBC
 SG_ IPC_ODO : 31|20@0+ (1,0) [0|999999] "km"  BMS,DCDC,EVCC,OBC

BO_ 264 GW_SS_DriveReq_0x108: 8 VCU
 SG_ Checksum_0x108 : 7|8@0+ (1,0) [0|255] ""  EVCC
 SG_ Rolling_Counter_0x108 : 11|4@0+ (1,0) [0|15] ""  EVCC
 SG_ SS_DriveModeReq_reserved : 16|1@0+ (1,0) [0|1] ""  EVCC
 SG_ SS_TargetGearReq : 23|3@0+ (1,0) [0|7] ""  EVCC
 SG_ SS_Fault : 27|4@0+ (1,0) [0|15] ""  EVCC
 SG_ FR_Wipercontrol_switch : 34|3@0+ (1,0) [0|7] ""  EVCC
 SG_ Front_Wash : 36|2@0+ (1,0) [0|3] ""  EVCC
 SG_ SS_FogLight_reserved : 37|1@0+ (1,0) [0|1] ""  EVCC
 SG_ RR_Wiper : 39|2@0+ (1,0) [0|3] ""  EVCC
 SG_ SS_lane_change_lampSts : 41|2@0+ (1,0) [0|3] ""  EVCC
 SG_ SS_Overtaking_lamp : 42|1@0+ (1,0) [0|1] ""  EVCC
 SG_ SS_TurnIndicatorSts : 44|2@0+ (1,0) [0|3] ""  EVCC
 SG_ SS_PosLmpSts : 45|1@0+ (1,0) [0|1] ""  EVCC
 SG_ SS_LowBeamSts : 46|1@0+ (1,0) [0|1] ""  EVCC
 SG_ SS_HighBeamSts : 47|1@0+ (1,0) [0|1] ""  EVCC
 SG_ SS_HardNumLow : 51|4@0+ (1,0) [0|15] ""  EVCC
 SG_ SS_HardNumHigh : 55|4@0+ (1,0) [0|15] ""  EVCC
 SG_ SS_SoftNumLow : 59|4@0+ (1,0) [0|15] ""  EVCC
 SG_ SS_SoftNumHigh : 63|4@0+ (1,0) [0|15] ""  EVCC

BO_ 534 BMS_ChgParamReq_0x216: 8 BMS
 SG_ Checksum_0x216 : 7|8@0+ (1,0) [0|255] ""  VCU,EVCC
 SG_ Rolling_Counter_0x216 : 11|4@0+ (1,0) [0|15] ""  VCU,EVCC
 SG_ BMS_RemainChargeTime : 21|14@0+ (1,0) [0|16383] "min"  VCU,EVCC
 SG_ BMS_ChgVoltage_REQ : 37|14@0+ (0.1,0) [0|800] "V"  VCU,EVCC
 SG_ BMS_ChgCurrent_REQ : 55|16@0+ (0.1,0) [0|1500] "A"  VCU,EVCC

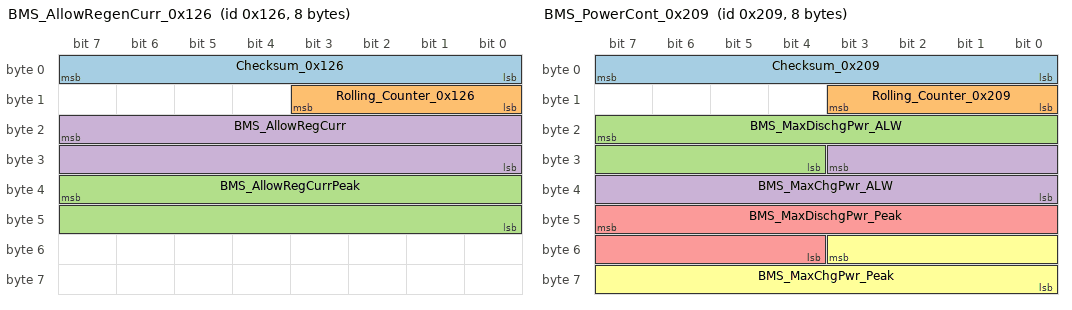
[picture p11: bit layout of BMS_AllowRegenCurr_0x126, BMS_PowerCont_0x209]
BO_ 294 BMS_AllowRegenCurr_0x126: 8 BMS
 SG_ Checksum_0x126 : 7|8@0+ (1,0) [0|255] ""  VCU,EVCC
 SG_ Rolling_Counter_0x126 : 11|4@0+ (1,0) [0|15] ""  VCU,EVCC
 SG_ BMS_AllowRegCurrPeak : 39|16@0+ (0.1,0) [0|1500] "A"  VCU,EVCC
 SG_ BMS_AllowRegCurr : 23|16@0+ (0.1,0) [0|1500] "A"  VCU,EVCC

BO_ 521 BMS_PowerCont_0x209: 8 BMS
 SG_ Checksum_0x209 : 7|8@0+ (1,0) [0|255] ""  VCU,EVCC
 SG_ Rolling_Counter_0x209 : 11|4@0+ (1,0) [0|15] ""  VCU,EVCC
 SG_ BMS_MaxDischgPwr_ALW : 23|12@0+ (0.1,0) [0|400] "KW"  VCU,EVCC
 SG_ BMS_MaxChgPwr_ALW : 27|12@0+ (0.1,0) [0|400] "KW"  VCU,EVCC
 SG_ BMS_MaxDischgPwr_Peak : 47|12@0+ (0.2,0) [0|800] "kw"  VCU,EVCC
 SG_ BMS_MaxChgPwr_Peak : 51|12@0+ (0.2,0) [0|800] "kw"  VCU,EVCC

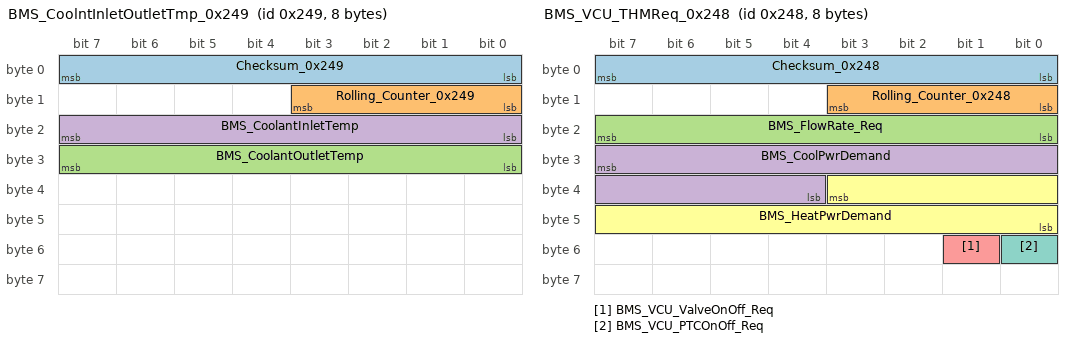
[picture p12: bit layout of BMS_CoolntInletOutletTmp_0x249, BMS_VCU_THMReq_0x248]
BO_ 585 BMS_CoolntInletOutletTmp_0x249: 8 BMS
 SG_ Checksum_0x249 : 7|8@0+ (1,0) [0|255] ""  VCU
 SG_ Rolling_Counter_0x249 : 11|4@0+ (1,0) [0|15] ""  VCU
 SG_ BMS_CoolantOutletTemp : 31|8@0+ (1,-40) [-40|215] "degree" Vector__XXX
 SG_ BMS_CoolantInletTemp : 23|8@0+ (1,-40) [-40|215] "degree" Vector__XXX

BO_ 584 BMS_VCU_THMReq_0x248: 8 BMS
 SG_ Checksum_0x248 : 7|8@0+ (1,0) [0|255] ""  VCU
 SG_ Rolling_Counter_0x248 : 11|4@0+ (1,0) [0|15] ""  VCU
 SG_ BMS_FlowRate_Req : 23|8@0+ (1,0) [0|50] "L/min"  VCU
 SG_ BMS_CoolPwrDemand : 31|12@0+ (0.1,0) [0|10] "KW"  VCU
 SG_ BMS_VCU_ValveOnOff_Req : 49|1@0+ (1,0) [0|1] ""  VCU
 SG_ BMS_HeatPwrDemand : 35|12@0+ (0.1,0) [0|10] "KW"  VCU
 SG_ BMS_VCU_PTCOnOff_Req : 48|1@0+ (1,0) [0|1] ""  VCU

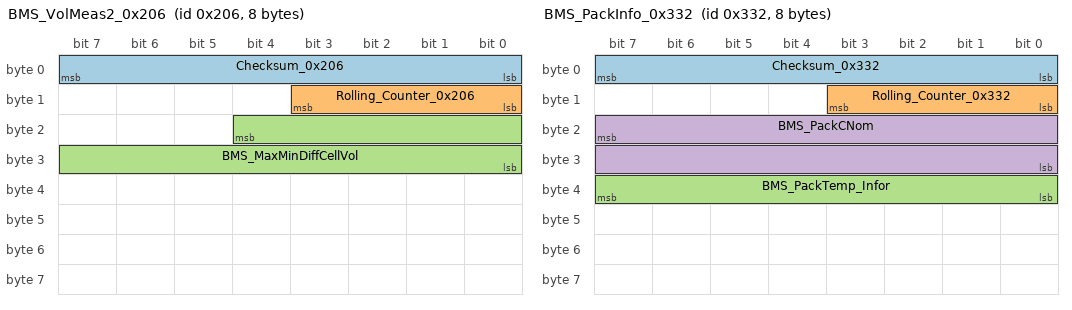
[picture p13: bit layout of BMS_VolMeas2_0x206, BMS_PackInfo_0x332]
BO_ 518 BMS_VolMeas2_0x206: 8 BMS
 SG_ Checksum_0x206 : 7|8@0+ (1,0) [0|255] ""  VCU,EVCC
 SG_ Rolling_Counter_0x206 : 11|4@0+ (1,0) [0|15] ""  VCU,EVCC
 SG_ BMS_MaxMinDiffCellVol : 20|13@0+ (0.001,0) [0|2] "V"  VCU,EVCC

BO_ 818 BMS_PackInfo_0x332: 8 BMS
 SG_ Checksum_0x332 : 7|8@0+ (1,0) [0|255] ""  VCU,EVCC
 SG_ Rolling_Counter_0x332 : 11|4@0+ (1,0) [0|15] ""  VCU,EVCC
 SG_ BMS_PackTemp_Infor : 39|8@0+ (1,-40) [-40|215] "" Vector__XXX
 SG_ BMS_PackCNom : 23|16@0+ (0.1,0) [0|6553.5] "kwh"  VCU,EVCC

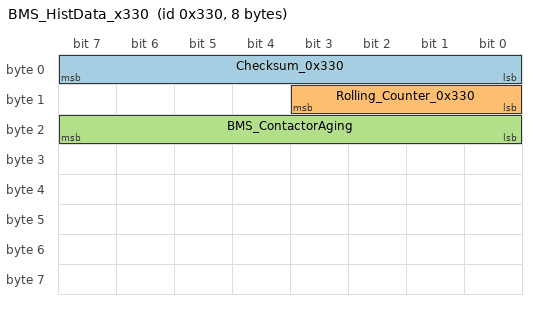
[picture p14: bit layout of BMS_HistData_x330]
BO_ 816 BMS_HistData_x330: 8 BMS
 SG_ Checksum_0x330 : 7|8@0+ (1,0) [0|255] ""  VCU
 SG_ Rolling_Counter_0x330 : 11|4@0+ (1,0) [0|15] ""  VCU
 SG_ BMS_ContactorAging : 23|8@0+ (1,0) [0|100] "%"  VCU

CM_ SG_ 171 CRC_VCU_0xAB "CRC_VCU_0xAB校验和";
CM_ SG_ 171 ALIVE_VCU_0xAB "ALIVE_VCU_0xAB循环计数";
CM_ SG_ 171 VCU_EDS_CtrModeReq "EDS control modeEDS控制模式";
CM_ SG_ 171 VCU_EDS_TargetTrqReq "Target motor torque request目标电机扭矩请求";
CM_ SG_ 171 VCU_EDS_TargetTrqReqV "Target motor torque request validity目标电机扭矩请求有效性";
CM_ SG_ 171 VCU_EDS_TargetSpeedReq "Target motor speed request目标电机转速请求";
CM_ SG_ 171 VCU_EDS_TargetSpeedReqV "Target motor speed request validity目标电机转速请求有效性";
CM_ SG_ 171 VCU_EDS_StsModeReq "Mode Request模式请求";
CM_ SG_ 570 VCU_ACEnaReq "AC Control Enable Request空调压缩机控制使能请求";
CM_ SG_ 570 VCU_ACSpdReq "AC Speed Request空调压缩机转速请求";
CM_ SG_ 570 VCU_ACPanelReqLevel "Panel request level空调面板请求等级";
CM_ SG_ 570 VCU_FanControl_Sts "Fan Control status";
CM_ SG_ 570 VCU_ACPipePressSw_Sts "AC Pipe Pressure Switch states压力开关状态";
CM_ SG_ 570 VCU_HVACInletTemp "HVAC inlet temperature";
CM_ SG_ 341 CRC_VCU_0x155 "CRC_VCU_0x155校验";
CM_ SG_ 341 ALIVE_VCU_0x155 "ALIVE_VCU_0x155循环计数";
CM_ SG_ 341 VCU_VecChrgRqst "Vehicle charging request整车充电请求";
CM_ SG_ 341 VCU_Vechg_Status "Vehicle charging state整车充电状态";
CM_ SG_ 341 VCU_VecOptMod "Vehicle operation mode整车运行模式";
CM_ SG_ 341 VCU_BMSHvPowOnRqst "VCU_BMSHvPowOnRqst电池高压上下电指令";
CM_ SG_ 341 VCU_DrTorqRqst "Drive torque request for EDS驱动扭矩请求";
CM_ SG_ 341 VCU_VecActGearStsV "Vehicle actual gear availability 整车实际档位有效性";
CM_ SG_ 341 VCU_VecActGearSts "Current actual gear state oF the vehicle   整车当前实际档位状态";
CM_ SG_ 341 VCU_LV_topupSts "LV_topupSts  低压补电状态";
CM_ SG_ 341 VCU_DrTorqRqstV "Drive torque request validity";
CM_ SG_ 341 VCU_ABS_TrqReqOrLmt "Driver requested torque for ABS";
CM_ SG_ 1221 CRC_VCU_0x4C5 "CRC_VCU_0x4C5校验";
CM_ SG_ 1221 ALIVE_VCU_0x4C5 "ALIVE_VCU_0x4C5循环计数";
CM_ SG_ 1221 VCU_CreepDisable_stt "Feedback for Creep disable request";
CM_ SG_ 1221 VCU_RDCSts "Regenerative coasted";
CM_ SG_ 1221 VCU_RBCSts "Regenerative Braking";
CM_ SG_ 1221 VCU_BrkPedalSWSts "Brake switch condition 制动开关状态";
CM_ SG_ 1221 Brakefluid_levelSts "Brakefluid_levelSts制动液位状态";
CM_ SG_ 1221 VCU_HandBrakeSts "VCU send hand brake sts   机械手刹状态";
CM_ SG_ 1221 VCU_RegenLevelfeed "VCU current regen stats";
CM_ SG_ 1221 VCU_PowerLimit "Vehicle power limit";
CM_ SG_ 1221 VCU_AccPedaPosValid "Accelerator pedal position valid加速踏板位置有效性";
CM_ SG_ 1221 VCU_AccPedaPos "Accelerator pedal position   加速踏板位置";
CM_ SG_ 1221 VCU_VehicleHVStatus "Vehicle high pressure condition      整车高压状态";
CM_ SG_ 1221 VCUVacuumPresWrn "The warm state of Vacuum 真空度状态";
CM_ SG_ 1221 VCUVacuumSts "The leak state of vacuume  真空泄漏状态";
CM_ SG_ 1221 VCU_InstantPowerConsump "Instant power consumption";
CM_ SG_ 1221 VCU_AveragePowerConsump "Average power comsumption";
CM_ SG_ 1221 VCU_LowSOCWarning "Low SOC WarningsVCU VCU低电量警告";
CM_ SG_ 1221 VCU_TqReductionRqstResponse "Indicate the response for the RBS/TCS request torque DTC/ASR";
CM_ SG_ 1221 VCU_DrvModeSts "Vehicle Driving Mode   整车驾驶模式";
CM_ SG_ 905 VCU_VacuumPumpEna "Vacuum pump enable flag";
CM_ SG_ 905 VCU_Ambient_Pres "indicate Ambient Pressure";
CM_ SG_ 905 VCU_Vacuum_Pres "indicate Vacuum Tank Pressure";
CM_ SG_ 1145 VCU_FaultCode "VCU Fault Code";
CM_ SG_ 1145 VCU_VehicleFailureLevel "VehicleFaultLevel";
CM_ SG_ 1145 VCU_EDSCAN_ERR "EDS CAN Communication Error(lost EDS node)";
CM_ SG_ 1145 VCU_BmsCAN_ERR "BMS CAN Communication(LossBMSNote)";
CM_ SG_ 1145 VCU_DcdcCAN_ERR "DCDC communication Failure(lost DCDC node)";
CM_ SG_ 1145 VCU_AbsCAN_ERR "ABS communication Failure(lost ABS node)";
CM_ SG_ 1145 VCU_ACUCAN_ERR "ACU communication Failure(lost ACU node)";
CM_ SG_ 1145 VCU_BcmCAN_ERR_reserved "BCM communication Failure(lost BCM node)";
CM_ SG_ 1145 VCU_BrakeSys_Err "Brake system Failure (Reserved)";
CM_ SG_ 1145 VCU_AccPed_ERR "Throttle pedal malFunction";
CM_ SG_ 1145 VCU_Shift_ERR "Gear Shift fault";
CM_ SG_ 1145 VCU_EPSCAN_ERR "EPS Module Failure";
CM_ SG_ 1145 VCU_EvccCAN_ERR "EVCC communication failure(lost EVCC node)";
CM_ SG_ 1145 VCU_FlgHVIL_ERR "HVIL Failure";
CM_ SG_ 1145 VCU_ObcCAN_ERR "OBC  communication failure(lost OBC  node)";
CM_ SG_ 1145 VCU_SSCAN_ERR "SS communication Failure(lost SS node)";
CM_ SG_ 1145 VCU_EacCAN_ERR "EAC Module Failure";
CM_ SG_ 1145 VCU_AccPedalOutRange "Accelerator pedal over range fault";
CM_ SG_ 201 CRC_EDS_0xC9 "Check校验";
CM_ SG_ 201 ALIVE_EDS_0xC9 "RollingCounter循环计数";
CM_ SG_ 201 EDS_VCU_CtrMode "EDS control modeEDS控制模式";
CM_ SG_ 201 EDS_MotorSpdVD "Motor speed eFFectiveness 电机转速有效性";
CM_ SG_ 201 EDS_MotorTqVD "Motor torque eFFectiveness电机扭矩有效性";
CM_ SG_ 201 EDS_MotorTq "Motor torque  电机扭矩";
CM_ SG_ 201 EDS_MotorSpd "Motor speed   电机转速";
CM_ SG_ 201 EDS_HSA_Sts "Hill assist active status  坡道辅助激活状态";
CM_ SG_ 201 EDS_DriveSTS "EDS Drive StateEDS    EDS驱动状态";
CM_ SG_ 201 EDS_StsMode "EDS operating modeEDS工作模式";
CM_ SG_ 201 EDS_VehicleFailureLevel "EDS Vehicle Failure Level";
CM_ SG_ 201 EDS_HSA_Fault "HSA fault status 坡道辅助故障状态";
CM_ SG_ 202 CRC_EDS_0xCA "CheckSum校验和";
CM_ SG_ 202 ALIVE_EDS_0xCA "RollingCounter循环计数";
CM_ SG_ 202 EDS_ActHV_VoltVD "Actual voltage availability of bus 母线实际电压有效性";
CM_ SG_ 202 EDS_ActHV_CurVD "Actual current availability of the bus母线实际电流有效性";
CM_ SG_ 202 EDS_ActHV_Cur "Actual current of bus 母线实际电流";
CM_ SG_ 202 EDS_ActHV_Volt "Actual voltage of bus 母线实际电压";
CM_ SG_ 206 CRC_EDS_0xCE "CheckSum校验和";
CM_ SG_ 206 ALIVE_EDS_0xCE "RollingCounter循环计数";
CM_ SG_ 206 EDS_MaxSpeedLimit "motor speed limit";
CM_ SG_ 206 EDS_PosTorqLimit "Motor positive torque limit   电机正扭矩限制";
CM_ SG_ 206 EDS_NegTorqLimit "Motor negative torque limit     电机负扭矩限制";
CM_ SG_ 871 CRC_EDS_0x367 "CheckSum校验和";
CM_ SG_ 871 ALIVE_EDS_0x367 "RollingCounter循环计数";
CM_ SG_ 871 EDS_IGBTTemp "IGBT temperature";
CM_ SG_ 871 EDS_Motor_statorTemp "Motor stator temperature";
CM_ SG_ 871 EDS_EDSTemp "EDS temperatureEDS温度";
CM_ SG_ 871 EDS_MotorTemp "Motor temperature 电机温度";
CM_ SG_ 872 EDS_MotTempSenFault "Motor temperature sensor Failure    电机温度传感器故障";
CM_ SG_ 872 EDS_EDSOverTempAlarm "EDS overtemperature alarmEDS过温报警";
CM_ SG_ 872 EDS_EDSOverTempFault "EDS over-temperature FaultEDS过温故障";
CM_ SG_ 872 EDS_LV_VotagtFault "EDS low voltage power supply FailureEDS低压供电故障";
CM_ SG_ 872 EDS_PhashOverCurrentSWFault "Phase current overcurrent software Fault相电流过流软件故障";
CM_ SG_ 872 EDS_EDSCurrentSenVFault "EDS current V sensor FaultEDS电流V传感器故障";
CM_ SG_ 872 EDS_EDSCurrentSenWFault "EDS current W sensor FaultEDS电流W传感器故障";
CM_ SG_ 872 EDS_EDSHVOverVoltageAlarm "High voltage bus voltage alarm高压母线电压过高报警";
CM_ SG_ 872 EDS_EDSHVOverVoltageFault "High voltage bus voltage Fault高压母线电压过高故障";
CM_ SG_ 872 EDS_EDSHVUnderVoltageAlarm "High voltage bus voltage low alarm   高压母线电压过低报警";
CM_ SG_ 872 EDS_EDSHVUnderVoltageFault "Low voltage Fault oF high voltage bus  高压母线电压过低故障";
CM_ SG_ 872 EDS_MotOverTempAlarm "Motor overtemperature alarm电机过温报警";
CM_ SG_ 872 EDS_MotOverTempFault "Motor overtemperature Fault  电机过温故障";
CM_ SG_ 872 EDS_EDSDisChgFault "EDS active discharge FaultEDS主动放电故障";
CM_ SG_ 872 EDS_EDSHVSenFault "EDS high pressure sensor FaultEDS高压传感器故障";
CM_ SG_ 872 EDS_12VOverVoltageAlarm "12V input voltage high alarm12V输入电压过高报警";
CM_ SG_ 872 EDS_12VUnderVoltageAlarm "12V input voltage low alarm12V输入电压过低报警";
CM_ SG_ 872 EDS_MotOverAlarm "High motor speed alarm 电机速度过高报警";
CM_ SG_ 872 EDS_MotOverFault "High motor speed Fault  电机速度过高故障";
CM_ SG_ 872 EDS_PhashOverCurrentHWFault "Phase current overcurrent hardware Failure相电流过流硬件故障";
CM_ SG_ 872 EDS_EDSCurrentSenUFault "EDS current U sensor FaultEDS电流U传感器故障";
CM_ SG_ 872 EDS_VCULostFault "VCU lost communication FailureVCU丢失通信故障";
CM_ SG_ 872 EDS_BMSLostFault "BMS lost Communication FailureBMS丢失通信故障";
CM_ SG_ 872 EDS_MotRotSenFault "Motor transFormer Fault电机变压器故障";
CM_ SG_ 872 EDS_MotBlockedFault "Motor blocking Fault  电机堵转故障";
CM_ SG_ 872 EDS_EDSChksumFault "EDS Torque request checksum error messageEDS扭矩请求checksum报错";
CM_ SG_ 872 EDS_MotTrqLimtFault "Motor torque limit Fault 电机限扭故障";
CM_ SG_ 872 EDS_VCUChksumFault "VCU Checksum error";
CM_ SG_ 872 EDS_EDSEnableFault "EDS enable FailureEDS使能故障";
CM_ SG_ 872 EDS_IGBTFault "IGBT FaultIGBT故障";
CM_ SG_ 872 EDS_CANBUSOFFFault "CAN BUSOFF FaultCAN BUSOFF故障";
CM_ SG_ 872 EDS_EDSTempSensorErr "Controller temperature sensor Failure   控制器温度传感器故障";
CM_ SG_ 872 EDS_HWCapOverVolt "SoFtware detects capacitor overvoltage硬件检测电容过压";
CM_ SG_ 872 EDS_SWCapOverVolt "SoFtware testing capacitor over voltage   软件检测电容过压";
CM_ SG_ 872 EDS_EDSMemoryFlt "Controller memory unit Failure控制器存储单元故障";
CM_ SG_ 872 EDS_InitMode "EDS initializationEDS初始化";
CM_ SG_ 872 EDS_MotorSN "Motor serial number电机序号";
CM_ SG_ 872 EDS_EDSFaultCode "EDSFaultCodeEDS故障码";
CM_ SG_ 873 CRC_EDS_0x369 "CheckSum校验和";
CM_ SG_ 873 ALIVE_EDS_0x369 "RollingCounter循环计数";
CM_ SG_ 873 EDS_IGBTState "EDS IGBT StateIGBT状态";
CM_ SG_ 873 EDS_DampingState "EDS Damping State阻尼状态";
CM_ SG_ 873 EDS_StsActiveDisChg "Motor active discharge state电机主动放电状态";
CM_ SG_ 873 EDS_MotorDCPower "Motor DC power  电机直流功率";
CM_ SG_ 873 EDS_Motor_Phase_Curr "Motor phase current电机相电流";
CM_ SG_ 382 Checksum_0x17E "Check sum";
CM_ SG_ 382 Rolling_counter_0x17E "Rolling Counter";
CM_ SG_ 382 EPS_S_WarningLampYellow "The warning lamp (yellow)警告灯";
CM_ SG_ 382 EPS_S_SaFeLampRed "The saFe lamp (red)安全指示灯";
CM_ SG_ 382 EPS_SteerWheelAngle "The current angle oF the steering wheel(Positive, to leFt Negative, to right)";
CM_ SG_ 382 EPS_SteerWhlRotSpd "The current rotation speed oF the steering wheel.";
CM_ SG_ 382 EPS_SteerWheelRotSpdStatus "The status oF SteerWheelRotSpd    方向盘转速有效性";
CM_ SG_ 382 EPS_SteeringAngleValid "steeing angle singal valid转角信号有效性";
CM_ SG_ 382 EPS_VehicleFailureLevel "EPS Vehicle Failure Level";
CM_ SG_ 382 EPS_status "EPS statusEPS_状态";
CM_ SG_ 382 EPS_Calibrated "SAS calibration state oF steer angle sensor转向角传感器的SAS校准状态";
CM_ SG_ 382 EPS_Systemstatus "EPS system statusEPS系统状态";
CM_ SG_ 382 EPS_EPSFaultCode "EPSFaultCodeEPSEPS故障码";
CM_ SG_ 383 CheckSum_0x17F "CheckSum_0x17F校验和";
CM_ SG_ 383 Alive_SAS_0x17F "RollingCounter_0x17F循环计数";
CM_ SG_ 383 EPS_SteeringTorque "Steering torque (Positive, to left Negative, to right)";
CM_ SG_ 383 EPS_SASFailure "Angle sensor disabled";
CM_ SG_ 383 EPS_SASStsSnsr "the flag of  SAS status Punch:Steering angle status";
CM_ SG_ 383 EPS_TorqSensorStatus "Validation bit of torsion bar torque";
CM_ SG_ 383 EPS_Mode "Electric steering mode";
CM_ SG_ 383 EPS_EpsFailed "EPS Failed bit";
CM_ SG_ 571 CRC_0x23B "CRC_0x23B";
CM_ SG_ 571 Alive_EAC_0x23B "Rolling_counter_0x23B";
CM_ SG_ 571 EAC_Spd "EAC SpeedEAC转速";
CM_ SG_ 571 EAC_InputVolt "EAC Input VoltageEAC输入电压";
CM_ SG_ 571 EAC_Sts "EAC statusEAC状态";
CM_ SG_ 571 EAC_InputCurr "EAC Input CurrentEAC输入电流";
CM_ SG_ 571 EAC_Temp "EAC TemperatureEAC温度";
CM_ SG_ 571 EAC_VehicleFailureLevel "EAC Fault LevelEAC 故障等级";
CM_ SG_ 571 EAC_ErrorCode "EAC Error CodeEAC 故障码";
CM_ SG_ 1249 SW_Group_ID "The group material of software(ASCII Code)";
CM_ SG_ 1249 SW_Base_Number "The base number of software";
CM_ SG_ 1253 SW_Major_Version_Number "Major Version Number of software(ASCII Code)";
CM_ SG_ 1253 SW_Minor_Version_Number "Minor Version Number of software";
CM_ SG_ 1257 HW_Group_ID "The group material of hardware(ASCII Code)";
CM_ SG_ 1257 HW_Base_Number "The base number of hardware";
CM_ SG_ 1259 HW_Major_Version_Number "Major Version Number of hardware (ASCII Code)";
CM_ SG_ 1259 HW_Minor_Version_Number "Minor Version Number of hardware";
CM_ SG_ 133 Checksum_0x85 "Checksum";
CM_ SG_ 133 Rolling_Counter_0x85 "Rolling Counter";
CM_ SG_ 133 ACU_Crash_Sts "Crash status";
CM_ SG_ 133 ACU_Airbag_Deployment_Status "Signal to indicate if airbag/pretensioner/pyrofuse is deployed";
CM_ SG_ 280 CRC_ABS_0x118 "CRC_ABS_0x118校验和";
CM_ SG_ 280 ALIVE_ABS_0x118 "ALIVE_ABS_0x118 循环计数";
CM_ SG_ 280 ABS_HazardLightsOnReq "ABS Request to light hazard warning lights (reserved)ABS请求点亮危险警报灯（预留）";
CM_ SG_ 280 ABS_BrakeLightsOnReq "ABS request to light brake light (reserved)";
CM_ SG_ 280 ABS_TcsFlgFlt "Detect the TCS Function Fault status";
CM_ SG_ 280 ABS_TCS_Active "Indicate TCS  Function is active or not";
CM_ SG_ 280 ABS_ABSActive "ABS active stateABS激活状态";
CM_ SG_ 280 ABS_EBDFault "EBD system FailureEBD系统故障";
CM_ SG_ 280 ABS_ABSFault "ABS system FailureABS系统故障";
CM_ SG_ 280 ABS_TCS_OFF_State "Indicate the TCS Function open or close";
CM_ SG_ 280 ABS_VehicleFailureLevel "ABS Vehicle failure levelABS整车故障等级";
CM_ SG_ 280 ABS_RBSInhibitFlag "Energy recovery prohibited Flag bit 能量回收禁止标志位";
CM_ SG_ 280 ABS_EBDActive "EBD activation statusEBD激活状态";
CM_ SG_ 280 ABS_VehicleSpeed "Speed车速";
CM_ SG_ 280 ABS_VehicleSpeedV "Speed signal validity 车速信号有效性";
CM_ SG_ 1236 BCM_FrontLeftDoorAjarStatus "Signal from BCM to indicate the ajar/close status of driver doorBCM信号提示任意左前（驾驶员）车门开启／关闭状态";
CM_ SG_ 1236 BCM_FrontRightDoorAjarStatus "Signal from BCM to indicate the ajar/close status of passenger doorBCM信号提示右前车门开启／关闭状态";
CM_ SG_ 1236 BCM_RightDoorLockStatusDrv "Right Driver Door Lock Status 右前门锁状态";
CM_ SG_ 1236 BCM_LeftDoorLockStatusDrv "Left Driver Door Lock Status 左前门锁状态";
CM_ SG_ 1236 BCM_ATWS_St "BCM Anti thelf warning status 防盗报警状态";
CM_ SG_ 1236 BCM_STAT_DoorSpeedLock "Status feedback from BCM for Setting Door speed lock modeBCM状态反馈，用于设置门锁模式";
CM_ SG_ 513 CRC_BCM_0x201 "CRC_BCM_0x201校验和";
CM_ SG_ 513 ALIVE_BCM_0x201 "ALIVE_BCM_0x201 循环计数";
CM_ SG_ 513 BCM_LV_topupReq "LV_topupReq  低压补电请求";
CM_ SG_ 513 BCM_BatteryVoltage "Input Voltage  低压电池输入电压";
CM_ SG_ 513 BCM_Key_CheckSts "Key status Check 钥匙状态检测";
CM_ SG_ 513 BCM_Press_BrkPedal_Alert "Please step on the brake pedal to remind请踩制动踏板提醒";
CM_ SG_ 513 BCM_EmergencyStop "Emergency power-off    紧急下电（熄火）";
CM_ SG_ 513 BCM_IGN1RelayOutputSts "IGN1Relays output status";
CM_ SG_ 513 BCM_ACCRelayOutputSts "ACCRelays output status";
CM_ SG_ 513 BCM_FLWIN_Postion_Reserved "FL window postion  左前窗位置";
CM_ SG_ 513 BCM_KEY_MatchSts "Match status with Key";
CM_ SG_ 513 BCM_FRWIN_Postion_Reserved "FR window postion 右前窗位置";
CM_ SG_ 513 BCM_BCMFaultCode "BCM fault codeBCM故障码";
CM_ SG_ 513 BCM_PowerMode "BCM Power Distribution StatusBCM电源状态";
CM_ SG_ 513 BCM_BrakeSwSts "Break switch Status 刹车开关状态";
CM_ SG_ 513 BCM_VehicleFailureLevel "BCM Vehicle failure levelBCM整车故障等级";
CM_ SG_ 513 BCM_Anti_theftAlarmSetSts "Anti_thef tAlarm Set Status防盗警报设置状态";
CM_ SG_ 513 BCM_FMH_SetSts "Follow me home Set Sts伴我回家设置状态";
CM_ SG_ 513 BCM_IGN1RelayFaultSts "IGN1Relays Fault Status";
CM_ SG_ 513 BCM_ACCRelayFaultSts "ACCRelays Fault Status";
CM_ SG_ 676 CRC_IPC_0x2A4 "CRC_IPC_0x2A4校验和";
CM_ SG_ 676 ALIVE_IPC_0x2A4 "ALIVE_IPC_0x2A4心跳";
CM_ SG_ 676 IPC_EnergyRecSet "Energy recovery state能量回收状态";
CM_ SG_ 676 IPC_HSA_Set "Hill assist function  control 坡道辅助控制";
CM_ SG_ 676 IPC_DriveModeSet "Drive mode command  驾驶模式指令";
CM_ SG_ 676 IPC_VCU_CreepDisable_Stt "Request for VCU to disable creep funtion";
CM_ SG_ 676 IPC_DriveLockSpeedCtl "Driving lock speed control  行车落锁速度控制";
CM_ SG_ 1074 Checksum_0x432 "Checksum";
CM_ SG_ 1074 Rolling_Counter_0x432 "Rolling_Counter";
CM_ SG_ 1074 IPC_FOTA_State "0 ''INIT''1 ''NORMAL''2 ''FOTA FLASHING''3 ''Reserved''4 ''FAIL-SAFE-ERROR''5 ''Reserved''6 ''REMOTE DIAGNOSTICS''7 ''Invalid''";
CM_ SG_ 677 CRC_IPC_0x2A5 "CRC_IPC_0x2A5校验和";
CM_ SG_ 677 ALIVE_IPC_0x2A5 "ALIVE_IPC_0x2A5心跳";
CM_ SG_ 677 IPC_ChargeScheduleSet "Request  enable/disable Charging Scheduling";
CM_ SG_ 677 IPC_ChargingRequest "IPC charging requestIPC充电请求";
CM_ SG_ 677 IPC_ChrSOCLitCtr "SOC charge limit controlSOC充电限制控制";
CM_ SG_ 1087 IPC_Year "Represents the current year.";
CM_ SG_ 1087 IPC_Month "Represents the current month.0, 13 to 15 = Invalid";
CM_ SG_ 1087 IPC_SelFCheckStatus "Power on selF check status";
CM_ SG_ 1087 IPC_Day "Represents the current dayInvalid value = 0";
CM_ SG_ 1087 IPC_Hour "Represents the current hour, 24 - 30 = not used";
CM_ SG_ 1087 IPC_Min "Represents the current minute. 60 - 63 = Invalid";
CM_ SG_ 1087 IPC_Sec "Represents the current second.60 - 63 = Invalid";
CM_ SG_ 524 CRC_IPC_0x20C "CRC_IPC_0x20C校验和";
CM_ SG_ 524 ALIVE_IPC_0x20C "ALIVE_IPC_0x20C心跳";
CM_ SG_ 524 IPC_ODO "odograph";
CM_ SG_ 264 Checksum_0x108 "Check sum";
CM_ SG_ 264 Rolling_Counter_0x108 "Rolling Counter";
CM_ SG_ 264 SS_DriveModeReq_reserved "The drive mode request";
CM_ SG_ 264 SS_TargetGearReq "Target gear request";
CM_ SG_ 264 SS_Fault "Fault statue";
CM_ SG_ 264 FR_Wipercontrol_switch "Front Wiper control switch";
CM_ SG_ 264 Front_Wash "Front Wash Status";
CM_ SG_ 264 SS_FogLight_reserved "status of fog light";
CM_ SG_ 264 RR_Wiper "Rear wiper";
CM_ SG_ 264 SS_lane_change_lampSts "lane change light output Status";
CM_ SG_ 264 SS_Overtaking_lamp "Overtaking lamp output Status";
CM_ SG_ 264 SS_TurnIndicatorSts "Turn light output  Status";
CM_ SG_ 264 SS_PosLmpSts "Position light output Status";
CM_ SG_ 264 SS_LowBeamSts "Low beam output  Status";
CM_ SG_ 264 SS_HighBeamSts "High beam output Status";
CM_ SG_ 264 SS_HardNumLow "Hard Number Low";
CM_ SG_ 264 SS_HardNumHigh "Hard Number High";
CM_ SG_ 264 SS_SoftNumLow "Soft Number Low";
CM_ SG_ 264 SS_SoftNumHigh "Soft Number High";
CM_ SG_ 534 Checksum_0x216 "Checksum";
CM_ SG_ 534 Rolling_Counter_0x216 "Rolling_Counter";
CM_ SG_ 534 BMS_RemainChargeTime "Charge remaining time (VCU - IPC)";
CM_ SG_ 534 BMS_ChgVoltage_REQ "BMS requires charging voltage";
CM_ SG_ 534 BMS_ChgCurrent_REQ "BMS requires charging current";
CM_ SG_ 294 Checksum_0x126 "Checksum";
CM_ SG_ 294 Rolling_Counter_0x126 "Rolling_Counter";
CM_ SG_ 294 BMS_AllowRegCurrPeak "Peak allowable charge current of battery";
CM_ SG_ 294 BMS_AllowRegCurr "Continuous maximum allowable charge current of battery";
CM_ SG_ 521 Checksum_0x209 "Checksum";
CM_ SG_ 521 Rolling_Counter_0x209 "Rolling_Counter";
CM_ SG_ 521 BMS_MaxDischgPwr_ALW "Allow Max Discharge Power";
CM_ SG_ 521 BMS_MaxChgPwr_ALW "Allow Max Regenerative Power";
CM_ SG_ 521 BMS_MaxDischgPwr_Peak "Peak Discharge Power";
CM_ SG_ 521 BMS_MaxChgPwr_Peak "Peak Regenerative Power";
CM_ SG_ 585 Checksum_0x249 "Checksum";
CM_ SG_ 585 Rolling_Counter_0x249 "Rolling Counter";
CM_ SG_ 585 BMS_CoolantOutletTemp "Temperature of Battery Coolant Outlet";
CM_ SG_ 585 BMS_CoolantInletTemp "Temperature of Battery Coolant Inlet";
CM_ SG_ 584 Checksum_0x248 "Checksum";
CM_ SG_ 584 Rolling_Counter_0x248 "Rolling Counter";
CM_ SG_ 584 BMS_FlowRate_Req "Flow rate required";
CM_ SG_ 584 BMS_CoolPwrDemand "requesting the cooling power required fro the battery pack";
CM_ SG_ 584 BMS_VCU_ValveOnOff_Req "requesting VCU to turn on and off the valve";
CM_ SG_ 584 BMS_HeatPwrDemand "requesting the heating power required fro the battery pack";
CM_ SG_ 584 BMS_VCU_PTCOnOff_Req "PTC Heater turn on and off request";
CM_ SG_ 518 Checksum_0x206 "Checksum";
CM_ SG_ 518 Rolling_Counter_0x206 "Rolling Counter";
CM_ SG_ 518 BMS_MaxMinDiffCellVol "max and min cell voltage differences";
CM_ SG_ 818 Checksum_0x332 "Checksum";
CM_ SG_ 818 Rolling_Counter_0x332 "Rolling Counter";
CM_ SG_ 818 BMS_PackTemp_Infor "Pack Temperature";
CM_ SG_ 818 BMS_PackCNom "Nominal capacity of the battery pack";
CM_ SG_ 816 Checksum_0x330 "CheckSum校验和";
CM_ SG_ 816 Rolling_Counter_0x330 "Rolling Counter";
CM_ SG_ 816 BMS_ContactorAging "Aging condition of contactor";
BA_DEF_ BO_  "DiagRequest" ENUM  "No","Yes";
BA_DEF_ BO_  "DiagResponse" ENUM  "No","Yes";
BA_DEF_ BO_  "GenMsgCycleTime" INT 0 65535;
BA_DEF_ BO_  "GenMsgCycleTimeFast" INT 0 65535;
BA_DEF_ BO_  "GenMsgDelayTime" INT 0 65535;
BA_DEF_ BO_  "GenMsgILSupport" ENUM  "No","Yes";
BA_DEF_ BO_  "GenMsgNrOfRepetition" INT 0 65535;
BA_DEF_ BO_  "GenMsgSendType" ENUM  "Cycle","Event","IfActive","CE","CA";
BA_DEF_ BO_  "NmAsrMessage" ENUM  "No","Yes";
BA_DEF_ BO_  "NmMessage" ENUM  "No","Yes";
BA_DEF_ SG_  "GenSigSendType" ENUM  "Cycle","OnWrite","OnWriteWithRepetition","OnChange","OnChangeWithRepetition","IfActive","IfActiveWithRepetition";
BA_DEF_ SG_  "GenSigStartValue" INT 0 2147483647;
BA_DEF_ SG_  "GenSigInvalidValue" INT 0 2147483647;
BA_DEF_ SG_  "GenSigInactiveValue" INT 0 2147483647;
BA_DEF_ BU_  "ILUsed" ENUM  "No","Yes";
BA_DEF_ BU_  "NmAsrCanMsgReducedTime" INT 320 640;
BA_DEF_ BU_  "NmAsrNode" ENUM  "No","Yes";
BA_DEF_  "Baudrate" INT 0 1000000;
BA_DEF_  "BusType" STRING ;
BA_DEF_  "Manufacturer" STRING ;
BA_DEF_  "NmAsrBaseAddress" HEX 0 2047;
BA_DEF_  "NmAsrCanMsgCycleTime" INT 0 65535;
BA_DEF_  "NmAsrMessageCount" INT 1 256;
BA_DEF_  "NmAsrRepeatMessageTime" INT 0 65535;
BA_DEF_  "NmAsrTimeoutTime" INT 0 65535;
BA_DEF_  "NmAsrWaitBusSleepTime" INT 0 65535;
BA_DEF_  "NmType" STRING ;
BA_DEF_DEF_  "DiagRequest" "No";
BA_DEF_DEF_  "DiagResponse" "No";
BA_DEF_DEF_  "GenMsgCycleTime" 0;
BA_DEF_DEF_  "GenMsgCycleTimeFast" 0;
BA_DEF_DEF_  "GenMsgDelayTime" 0;
BA_DEF_DEF_  "GenMsgILSupport" "Yes";
BA_DEF_DEF_  "GenMsgNrOfRepetition" 0;
BA_DEF_DEF_  "GenMsgSendType" "";
BA_DEF_DEF_  "NmAsrMessage" "No";
BA_DEF_DEF_  "NmMessage" "No";
BA_DEF_DEF_  "GenSigSendType" "";
BA_DEF_DEF_  "GenSigStartValue" 0;
BA_DEF_DEF_  "GenSigInvalidValue" 0;
BA_DEF_DEF_  "GenSigInactiveValue" 0;
BA_DEF_DEF_  "ILUsed" "Yes";
BA_DEF_DEF_  "NmAsrCanMsgReducedTime" 320;
BA_DEF_DEF_  "NmAsrNode" "No";
BA_DEF_DEF_  "Baudrate" 500000;
BA_DEF_DEF_  "BusType" "CAN";
BA_DEF_DEF_  "Manufacturer" "Launch";
BA_DEF_DEF_  "NmAsrBaseAddress" 1280;
BA_DEF_DEF_  "NmAsrCanMsgCycleTime" 640;
BA_DEF_DEF_  "NmAsrMessageCount" 128;
BA_DEF_DEF_  "NmAsrRepeatMessageTime" 3200;
BA_DEF_DEF_  "NmAsrTimeoutTime" 2000;
BA_DEF_DEF_  "NmAsrWaitBusSleepTime" 1500;
BA_DEF_DEF_  "NmType" "NmAsr";
BA_ "NmAsrNode" BU_ VCU 1;
BA_ "NmAsrNode" BU_ BMS 1;
BA_ "NmAsrNode" BU_ DCDC 1;
BA_ "NmAsrNode" BU_ EVCC 1;
BA_ "NmAsrNode" BU_ OBC 1;
BA_ "GenMsgCycleTime" BO_ 171 10;
BA_ "GenMsgSendType" BO_ 171 0;
BA_ "GenMsgCycleTime" BO_ 570 100;
BA_ "GenMsgSendType" BO_ 570 0;
BA_ "GenMsgCycleTime" BO_ 341 10;
BA_ "GenMsgSendType" BO_ 341 0;
BA_ "GenMsgCycleTime" BO_ 1221 20;
BA_ "GenMsgSendType" BO_ 1221 0;
BA_ "GenMsgCycleTime" BO_ 905 100;
BA_ "GenMsgSendType" BO_ 905 0;
BA_ "GenMsgCycleTime" BO_ 1145 100;
BA_ "GenMsgSendType" BO_ 1145 0;
BA_ "GenMsgCycleTime" BO_ 769 200;
BA_ "GenMsgSendType" BO_ 769 0;
BA_ "GenMsgCycleTime" BO_ 201 10;
BA_ "GenMsgSendType" BO_ 201 0;
BA_ "GenMsgCycleTime" BO_ 202 10;
BA_ "GenMsgSendType" BO_ 202 0;
BA_ "GenMsgCycleTime" BO_ 206 100;
BA_ "GenMsgSendType" BO_ 206 0;
BA_ "GenMsgCycleTime" BO_ 871 500;
BA_ "GenMsgSendType" BO_ 871 0;
BA_ "GenMsgCycleTime" BO_ 872 500;
BA_ "GenMsgSendType" BO_ 872 0;
BA_ "GenMsgCycleTime" BO_ 873 500;
BA_ "GenMsgSendType" BO_ 873 0;
BA_ "GenMsgCycleTime" BO_ 382 10;
BA_ "GenMsgSendType" BO_ 382 0;
BA_ "GenMsgCycleTime" BO_ 383 10;
BA_ "GenMsgSendType" BO_ 383 0;
BA_ "GenMsgCycleTime" BO_ 571 100;
BA_ "GenMsgSendType" BO_ 571 0;
BA_ "GenMsgCycleTime" BO_ 1249 2000;
BA_ "GenMsgSendType" BO_ 1249 0;
BA_ "GenMsgCycleTime" BO_ 1253 2000;
BA_ "GenMsgSendType" BO_ 1253 0;
BA_ "GenMsgCycleTime" BO_ 1257 2000;
BA_ "GenMsgSendType" BO_ 1257 0;
BA_ "GenMsgCycleTime" BO_ 1259 2000;
BA_ "GenMsgSendType" BO_ 1259 0;
BA_ "GenMsgCycleTime" BO_ 133 20;
BA_ "GenMsgSendType" BO_ 133 0;
BA_ "GenMsgCycleTime" BO_ 280 10;
BA_ "GenMsgSendType" BO_ 280 0;
BA_ "GenMsgCycleTime" BO_ 1236 150;
BA_ "GenMsgSendType" BO_ 1236 0;
BA_ "GenMsgCycleTime" BO_ 513 100;
BA_ "GenMsgSendType" BO_ 513 0;
BA_ "GenMsgCycleTime" BO_ 676 100;
BA_ "GenMsgSendType" BO_ 676 0;
BA_ "GenMsgCycleTime" BO_ 1074 100;
BA_ "GenMsgSendType" BO_ 1074 0;
BA_ "GenMsgCycleTime" BO_ 677 200;
BA_ "GenMsgSendType" BO_ 677 0;
BA_ "GenMsgCycleTime" BO_ 1087 1000;
BA_ "GenMsgSendType" BO_ 1087 0;
BA_ "GenMsgCycleTime" BO_ 524 100;
BA_ "GenMsgSendType" BO_ 524 0;
BA_ "GenMsgCycleTime" BO_ 264 50;
BA_ "GenMsgSendType" BO_ 264 0;
BA_ "GenMsgCycleTime" BO_ 534 50;
BA_ "GenMsgSendType" BO_ 534 0;
BA_ "GenMsgCycleTime" BO_ 294 20;
BA_ "GenMsgSendType" BO_ 294 0;
BA_ "GenMsgCycleTime" BO_ 521 20;
BA_ "GenMsgSendType" BO_ 521 0;
BA_ "GenMsgCycleTime" BO_ 585 100;
BA_ "GenMsgSendType" BO_ 585 0;
BA_ "GenMsgCycleTime" BO_ 584 100;
BA_ "GenMsgSendType" BO_ 584 0;
BA_ "GenMsgCycleTime" BO_ 518 20;
BA_ "GenMsgSendType" BO_ 518 0;
BA_ "GenMsgCycleTime" BO_ 818 100;
BA_ "GenMsgSendType" BO_ 818 0;
BA_ "GenMsgCycleTime" BO_ 816 100;
BA_ "GenMsgSendType" BO_ 816 0;
BA_ "GenSigStartValue" SG_ 171 CRC_VCU_0xAB 255;
BA_ "GenSigSendType" SG_ 171 CRC_VCU_0xAB 0;
BA_ "GenSigInvalidValue" SG_ 171 ALIVE_VCU_0xAB 15;
BA_ "GenSigSendType" SG_ 171 ALIVE_VCU_0xAB 0;
BA_ "GenSigSendType" SG_ 171 VCU_EDS_CtrModeReq 0;
BA_ "GenSigStartValue" SG_ 171 VCU_EDS_TargetTrqReq 1000;
BA_ "GenSigSendType" SG_ 171 VCU_EDS_TargetTrqReq 0;
BA_ "GenSigSendType" SG_ 171 VCU_EDS_TargetTrqReqV 0;
BA_ "GenSigStartValue" SG_ 171 VCU_EDS_TargetSpeedReq 20000;
BA_ "GenSigSendType" SG_ 171 VCU_EDS_TargetSpeedReq 0;
BA_ "GenSigSendType" SG_ 171 VCU_EDS_TargetSpeedReqV 0;
BA_ "GenSigInvalidValue" SG_ 171 VCU_EDS_StsModeReq 15;
BA_ "GenSigSendType" SG_ 171 VCU_EDS_StsModeReq 0;
BA_ "GenSigSendType" SG_ 570 VCU_ACEnaReq 0;
BA_ "GenSigInvalidValue" SG_ 570 VCU_ACSpdReq 8191;
BA_ "GenSigSendType" SG_ 570 VCU_ACSpdReq 0;
BA_ "GenSigInvalidValue" SG_ 570 VCU_ACPanelReqLevel 3;
BA_ "GenSigSendType" SG_ 570 VCU_ACPanelReqLevel 0;
BA_ "GenSigSendType" SG_ 570 VCU_FanControl_Sts 0;
BA_ "GenSigSendType" SG_ 570 VCU_ACPipePressSw_Sts 0;
BA_ "GenSigStartValue" SG_ 570 VCU_HVACInletTemp 400;
BA_ "GenSigInvalidValue" SG_ 570 VCU_HVACInletTemp 1023;
BA_ "GenSigSendType" SG_ 570 VCU_HVACInletTemp 0;
BA_ "GenSigStartValue" SG_ 341 CRC_VCU_0x155 255;
BA_ "GenSigSendType" SG_ 341 CRC_VCU_0x155 0;
BA_ "GenSigInvalidValue" SG_ 341 ALIVE_VCU_0x155 15;
BA_ "GenSigSendType" SG_ 341 ALIVE_VCU_0x155 0;
BA_ "GenSigSendType" SG_ 341 VCU_VecChrgRqst 0;
BA_ "GenSigSendType" SG_ 341 VCU_Vechg_Status 0;
BA_ "GenSigSendType" SG_ 341 VCU_VecOptMod 0;
BA_ "GenSigSendType" SG_ 341 VCU_BMSHvPowOnRqst 0;
BA_ "GenSigStartValue" SG_ 341 VCU_DrTorqRqst 2044;
BA_ "GenSigSendType" SG_ 341 VCU_DrTorqRqst 0;
BA_ "GenSigSendType" SG_ 341 VCU_VecActGearStsV 0;
BA_ "GenSigSendType" SG_ 341 VCU_VecActGearSts 0;
BA_ "GenSigSendType" SG_ 341 VCU_LV_topupSts 0;
BA_ "GenSigInvalidValue" SG_ 341 VCU_DrTorqRqstV 1;
BA_ "GenSigSendType" SG_ 341 VCU_DrTorqRqstV 0;
BA_ "GenSigStartValue" SG_ 341 VCU_ABS_TrqReqOrLmt 20000;
BA_ "GenSigInvalidValue" SG_ 341 VCU_ABS_TrqReqOrLmt 65535;
BA_ "GenSigSendType" SG_ 341 VCU_ABS_TrqReqOrLmt 0;
BA_ "GenSigStartValue" SG_ 1221 CRC_VCU_0x4C5 255;
BA_ "GenSigSendType" SG_ 1221 CRC_VCU_0x4C5 0;
BA_ "GenSigInvalidValue" SG_ 1221 ALIVE_VCU_0x4C5 15;
BA_ "GenSigSendType" SG_ 1221 ALIVE_VCU_0x4C5 0;
BA_ "GenSigSendType" SG_ 1221 VCU_CreepDisable_stt 0;
BA_ "GenSigSendType" SG_ 1221 VCU_RDCSts 0;
BA_ "GenSigSendType" SG_ 1221 VCU_RBCSts 0;
BA_ "GenSigSendType" SG_ 1221 VCU_BrkPedalSWSts 0;
BA_ "GenSigSendType" SG_ 1221 Brakefluid_levelSts 0;
BA_ "GenSigSendType" SG_ 1221 VCU_HandBrakeSts 0;
BA_ "GenSigSendType" SG_ 1221 VCU_RegenLevelfeed 0;
BA_ "GenSigSendType" SG_ 1221 VCU_PowerLimit 0;
BA_ "GenSigSendType" SG_ 1221 VCU_AccPedaPosValid 0;
BA_ "GenSigSendType" SG_ 1221 VCU_AccPedaPos 0;
BA_ "GenSigSendType" SG_ 1221 VCU_VehicleHVStatus 0;
BA_ "GenSigSendType" SG_ 1221 VCUVacuumPresWrn 0;
BA_ "GenSigSendType" SG_ 1221 VCUVacuumSts 0;
BA_ "GenSigSendType" SG_ 1221 VCU_InstantPowerConsump 0;
BA_ "GenSigSendType" SG_ 1221 VCU_AveragePowerConsump 0;
BA_ "GenSigSendType" SG_ 1221 VCU_LowSOCWarning 0;
BA_ "GenSigSendType" SG_ 1221 VCU_TqReductionRqstResponse 0;
BA_ "GenSigSendType" SG_ 1221 VCU_DrvModeSts 0;
BA_ "GenSigSendType" SG_ 905 VCU_VacuumPumpEna 0;
BA_ "GenSigSendType" SG_ 905 VCU_Ambient_Pres 0;
BA_ "GenSigStartValue" SG_ 905 VCU_Vacuum_Pres 150;
BA_ "GenSigSendType" SG_ 905 VCU_Vacuum_Pres 0;
BA_ "GenSigSendType" SG_ 1145 VCU_FaultCode 0;
BA_ "GenSigSendType" SG_ 1145 VCU_VehicleFailureLevel 0;
BA_ "GenSigSendType" SG_ 1145 VCU_EDSCAN_ERR 0;
BA_ "GenSigSendType" SG_ 1145 VCU_BmsCAN_ERR 0;
BA_ "GenSigSendType" SG_ 1145 VCU_DcdcCAN_ERR 0;
BA_ "GenSigSendType" SG_ 1145 VCU_AbsCAN_ERR 0;
BA_ "GenSigSendType" SG_ 1145 VCU_ACUCAN_ERR 0;
BA_ "GenSigSendType" SG_ 1145 VCU_BcmCAN_ERR_reserved 0;
BA_ "GenSigSendType" SG_ 1145 VCU_BrakeSys_Err 0;
BA_ "GenSigSendType" SG_ 1145 VCU_AccPed_ERR 0;
BA_ "GenSigSendType" SG_ 1145 VCU_Shift_ERR 0;
BA_ "GenSigSendType" SG_ 1145 VCU_EPSCAN_ERR 0;
BA_ "GenSigSendType" SG_ 1145 VCU_EvccCAN_ERR 0;
BA_ "GenSigSendType" SG_ 1145 VCU_FlgHVIL_ERR 0;
BA_ "GenSigSendType" SG_ 1145 VCU_ObcCAN_ERR 0;
BA_ "GenSigSendType" SG_ 1145 VCU_SSCAN_ERR 0;
BA_ "GenSigSendType" SG_ 1145 VCU_EacCAN_ERR 0;
BA_ "GenSigSendType" SG_ 1145 VCU_AccPedalOutRange 0;
BA_ "GenSigSendType" SG_ 769 VOD_Block 0;
BA_ "GenSigSendType" SG_ 769 VOD_UpdateFlag 0;
BA_ "GenSigStartValue" SG_ 769 VOD_Byte1 255;
BA_ "GenSigSendType" SG_ 769 VOD_Byte1 0;
BA_ "GenSigStartValue" SG_ 769 VOD_Byte2 255;
BA_ "GenSigSendType" SG_ 769 VOD_Byte2 0;
BA_ "GenSigStartValue" SG_ 769 VOD_Byte3 255;
BA_ "GenSigSendType" SG_ 769 VOD_Byte3 0;
BA_ "GenSigStartValue" SG_ 769 VOD_Byte4 255;
BA_ "GenSigSendType" SG_ 769 VOD_Byte4 0;
BA_ "GenSigStartValue" SG_ 769 VOD_Byte5 255;
BA_ "GenSigSendType" SG_ 769 VOD_Byte5 0;
BA_ "GenSigStartValue" SG_ 769 VOD_Byte6 255;
BA_ "GenSigSendType" SG_ 769 VOD_Byte6 0;
BA_ "GenSigStartValue" SG_ 769 VOD_Byte7 255;
BA_ "GenSigSendType" SG_ 769 VOD_Byte7 0;
BA_ "GenSigStartValue" SG_ 201 CRC_EDS_0xC9 255;
BA_ "GenSigSendType" SG_ 201 CRC_EDS_0xC9 0;
BA_ "GenSigInvalidValue" SG_ 201 ALIVE_EDS_0xC9 15;
BA_ "GenSigSendType" SG_ 201 ALIVE_EDS_0xC9 0;
BA_ "GenSigSendType" SG_ 201 EDS_VCU_CtrMode 0;
BA_ "GenSigInvalidValue" SG_ 201 EDS_MotorSpdVD 1;
BA_ "GenSigSendType" SG_ 201 EDS_MotorSpdVD 0;
BA_ "GenSigInvalidValue" SG_ 201 EDS_MotorTqVD 1;
BA_ "GenSigSendType" SG_ 201 EDS_MotorTqVD 0;
BA_ "GenSigStartValue" SG_ 201 EDS_MotorTq 12000;
BA_ "GenSigSendType" SG_ 201 EDS_MotorTq 0;
BA_ "GenSigStartValue" SG_ 201 EDS_MotorSpd 20000;
BA_ "GenSigSendType" SG_ 201 EDS_MotorSpd 0;
BA_ "GenSigSendType" SG_ 201 EDS_HSA_Sts 0;
BA_ "GenSigSendType" SG_ 201 EDS_DriveSTS 0;
BA_ "GenSigSendType" SG_ 201 EDS_StsMode 0;
BA_ "GenSigSendType" SG_ 201 EDS_VehicleFailureLevel 0;
BA_ "GenSigSendType" SG_ 201 EDS_HSA_Fault 0;
BA_ "GenSigStartValue" SG_ 202 CRC_EDS_0xCA 255;
BA_ "GenSigSendType" SG_ 202 CRC_EDS_0xCA 0;
BA_ "GenSigInvalidValue" SG_ 202 ALIVE_EDS_0xCA 15;
BA_ "GenSigSendType" SG_ 202 ALIVE_EDS_0xCA 0;
BA_ "GenSigSendType" SG_ 202 EDS_ActHV_VoltVD 0;
BA_ "GenSigSendType" SG_ 202 EDS_ActHV_CurVD 0;
BA_ "GenSigStartValue" SG_ 202 EDS_ActHV_Cur 2000;
BA_ "GenSigSendType" SG_ 202 EDS_ActHV_Cur 0;
BA_ "GenSigSendType" SG_ 202 EDS_ActHV_Volt 0;
BA_ "GenSigStartValue" SG_ 206 CRC_EDS_0xCE 255;
BA_ "GenSigSendType" SG_ 206 CRC_EDS_0xCE 0;
BA_ "GenSigInvalidValue" SG_ 206 ALIVE_EDS_0xCE 15;
BA_ "GenSigSendType" SG_ 206 ALIVE_EDS_0xCE 0;
BA_ "GenSigStartValue" SG_ 206 EDS_MaxSpeedLimit 20000;
BA_ "GenSigInvalidValue" SG_ 206 EDS_MaxSpeedLimit 65535;
BA_ "GenSigSendType" SG_ 206 EDS_MaxSpeedLimit 0;
BA_ "GenSigSendType" SG_ 206 EDS_PosTorqLimit 0;
BA_ "GenSigSendType" SG_ 206 EDS_NegTorqLimit 0;
BA_ "GenSigStartValue" SG_ 871 CRC_EDS_0x367 255;
BA_ "GenSigSendType" SG_ 871 CRC_EDS_0x367 0;
BA_ "GenSigInvalidValue" SG_ 871 ALIVE_EDS_0x367 15;
BA_ "GenSigSendType" SG_ 871 ALIVE_EDS_0x367 0;
BA_ "GenSigStartValue" SG_ 871 EDS_IGBTTemp 40;
BA_ "GenSigSendType" SG_ 871 EDS_IGBTTemp 0;
BA_ "GenSigStartValue" SG_ 871 EDS_Motor_statorTemp 40;
BA_ "GenSigSendType" SG_ 871 EDS_Motor_statorTemp 0;
BA_ "GenSigStartValue" SG_ 871 EDS_EDSTemp 40;
BA_ "GenSigSendType" SG_ 871 EDS_EDSTemp 0;
BA_ "GenSigStartValue" SG_ 871 EDS_MotorTemp 40;
BA_ "GenSigSendType" SG_ 871 EDS_MotorTemp 0;
BA_ "GenSigSendType" SG_ 872 EDS_MotTempSenFault 0;
BA_ "GenSigSendType" SG_ 872 EDS_EDSOverTempAlarm 0;
BA_ "GenSigSendType" SG_ 872 EDS_EDSOverTempFault 0;
BA_ "GenSigSendType" SG_ 872 EDS_LV_VotagtFault 0;
BA_ "GenSigSendType" SG_ 872 EDS_PhashOverCurrentSWFault 0;
BA_ "GenSigSendType" SG_ 872 EDS_EDSCurrentSenVFault 0;
BA_ "GenSigSendType" SG_ 872 EDS_EDSCurrentSenWFault 0;
BA_ "GenSigSendType" SG_ 872 EDS_EDSHVOverVoltageAlarm 0;
BA_ "GenSigSendType" SG_ 872 EDS_EDSHVOverVoltageFault 0;
BA_ "GenSigSendType" SG_ 872 EDS_EDSHVUnderVoltageAlarm 0;
BA_ "GenSigSendType" SG_ 872 EDS_EDSHVUnderVoltageFault 0;
BA_ "GenSigSendType" SG_ 872 EDS_MotOverTempAlarm 0;
BA_ "GenSigSendType" SG_ 872 EDS_MotOverTempFault 0;
BA_ "GenSigSendType" SG_ 872 EDS_EDSDisChgFault 0;
BA_ "GenSigSendType" SG_ 872 EDS_EDSHVSenFault 0;
BA_ "GenSigSendType" SG_ 872 EDS_12VOverVoltageAlarm 0;
BA_ "GenSigSendType" SG_ 872 EDS_12VUnderVoltageAlarm 0;
BA_ "GenSigSendType" SG_ 872 EDS_MotOverAlarm 0;
BA_ "GenSigSendType" SG_ 872 EDS_MotOverFault 0;
BA_ "GenSigSendType" SG_ 872 EDS_PhashOverCurrentHWFault 0;
BA_ "GenSigSendType" SG_ 872 EDS_EDSCurrentSenUFault 0;
BA_ "GenSigSendType" SG_ 872 EDS_VCULostFault 0;
BA_ "GenSigSendType" SG_ 872 EDS_BMSLostFault 0;
BA_ "GenSigSendType" SG_ 872 EDS_MotRotSenFault 0;
BA_ "GenSigSendType" SG_ 872 EDS_MotBlockedFault 0;
BA_ "GenSigSendType" SG_ 872 EDS_EDSChksumFault 0;
BA_ "GenSigSendType" SG_ 872 EDS_MotTrqLimtFault 0;
BA_ "GenSigSendType" SG_ 872 EDS_VCUChksumFault 0;
BA_ "GenSigSendType" SG_ 872 EDS_EDSEnableFault 0;
BA_ "GenSigSendType" SG_ 872 EDS_IGBTFault 0;
BA_ "GenSigSendType" SG_ 872 EDS_CANBUSOFFFault 0;
BA_ "GenSigSendType" SG_ 872 EDS_EDSTempSensorErr 0;
BA_ "GenSigSendType" SG_ 872 EDS_HWCapOverVolt 0;
BA_ "GenSigSendType" SG_ 872 EDS_SWCapOverVolt 0;
BA_ "GenSigSendType" SG_ 872 EDS_EDSMemoryFlt 0;
BA_ "GenSigSendType" SG_ 872 EDS_InitMode 0;
BA_ "GenSigSendType" SG_ 872 EDS_MotorSN 0;
BA_ "GenSigSendType" SG_ 872 EDS_EDSFaultCode 0;
BA_ "GenSigStartValue" SG_ 873 CRC_EDS_0x369 255;
BA_ "GenSigSendType" SG_ 873 CRC_EDS_0x369 0;
BA_ "GenSigInvalidValue" SG_ 873 ALIVE_EDS_0x369 15;
BA_ "GenSigSendType" SG_ 873 ALIVE_EDS_0x369 0;
BA_ "GenSigSendType" SG_ 873 EDS_IGBTState 0;
BA_ "GenSigSendType" SG_ 873 EDS_DampingState 0;
BA_ "GenSigSendType" SG_ 873 EDS_StsActiveDisChg 0;
BA_ "GenSigStartValue" SG_ 873 EDS_MotorDCPower 10000;
BA_ "GenSigInvalidValue" SG_ 873 EDS_MotorDCPower 65535;
BA_ "GenSigSendType" SG_ 873 EDS_MotorDCPower 0;
BA_ "GenSigStartValue" SG_ 873 EDS_Motor_Phase_Curr 32000;
BA_ "GenSigInvalidValue" SG_ 873 EDS_Motor_Phase_Curr 65535;
BA_ "GenSigSendType" SG_ 873 EDS_Motor_Phase_Curr 0;
BA_ "GenSigStartValue" SG_ 382 Checksum_0x17E 255;
BA_ "GenSigSendType" SG_ 382 Checksum_0x17E 0;
BA_ "GenSigInvalidValue" SG_ 382 Rolling_counter_0x17E 15;
BA_ "GenSigSendType" SG_ 382 Rolling_counter_0x17E 0;
BA_ "GenSigSendType" SG_ 382 EPS_S_WarningLampYellow 0;
BA_ "GenSigStartValue" SG_ 382 EPS_S_SaFeLampRed 1;
BA_ "GenSigSendType" SG_ 382 EPS_S_SaFeLampRed 0;
BA_ "GenSigStartValue" SG_ 382 EPS_SteerWheelAngle 32773;
BA_ "GenSigInvalidValue" SG_ 382 EPS_SteerWheelAngle 65535;
BA_ "GenSigSendType" SG_ 382 EPS_SteerWheelAngle 0;
BA_ "GenSigStartValue" SG_ 382 EPS_SteerWhlRotSpd 8192;
BA_ "GenSigInvalidValue" SG_ 382 EPS_SteerWhlRotSpd 16383;
BA_ "GenSigSendType" SG_ 382 EPS_SteerWhlRotSpd 0;
BA_ "GenSigInvalidValue" SG_ 382 EPS_SteerWheelRotSpdStatus 1;
BA_ "GenSigSendType" SG_ 382 EPS_SteerWheelRotSpdStatus 0;
BA_ "GenSigInvalidValue" SG_ 382 EPS_SteeringAngleValid 1;
BA_ "GenSigSendType" SG_ 382 EPS_SteeringAngleValid 0;
BA_ "GenSigSendType" SG_ 382 EPS_VehicleFailureLevel 0;
BA_ "GenSigSendType" SG_ 382 EPS_status 0;
BA_ "GenSigSendType" SG_ 382 EPS_Calibrated 0;
BA_ "GenSigSendType" SG_ 382 EPS_Systemstatus 0;
BA_ "GenSigSendType" SG_ 382 EPS_EPSFaultCode 0;
BA_ "GenSigStartValue" SG_ 383 CheckSum_0x17F 255;
BA_ "GenSigSendType" SG_ 383 CheckSum_0x17F 0;
BA_ "GenSigInvalidValue" SG_ 383 Alive_SAS_0x17F 15;
BA_ "GenSigSendType" SG_ 383 Alive_SAS_0x17F 0;
BA_ "GenSigStartValue" SG_ 383 EPS_SteeringTorque 1024;
BA_ "GenSigInvalidValue" SG_ 383 EPS_SteeringTorque 4095;
BA_ "GenSigSendType" SG_ 383 EPS_SteeringTorque 0;
BA_ "GenSigSendType" SG_ 383 EPS_SASFailure 0;
BA_ "GenSigSendType" SG_ 383 EPS_SASStsSnsr 0;
BA_ "GenSigSendType" SG_ 383 EPS_TorqSensorStatus 0;
BA_ "GenSigInvalidValue" SG_ 383 EPS_Mode 3;
BA_ "GenSigSendType" SG_ 383 EPS_Mode 0;
BA_ "GenSigStartValue" SG_ 383 EPS_EpsFailed 1;
BA_ "GenSigInvalidValue" SG_ 383 EPS_EpsFailed 1;
BA_ "GenSigSendType" SG_ 383 EPS_EpsFailed 0;
BA_ "GenSigStartValue" SG_ 571 CRC_0x23B 255;
BA_ "GenSigSendType" SG_ 571 CRC_0x23B 0;
BA_ "GenSigInvalidValue" SG_ 571 Alive_EAC_0x23B 15;
BA_ "GenSigSendType" SG_ 571 Alive_EAC_0x23B 0;
BA_ "GenSigSendType" SG_ 571 EAC_Spd 0;
BA_ "GenSigSendType" SG_ 571 EAC_InputVolt 0;
BA_ "GenSigSendType" SG_ 571 EAC_Sts 0;
BA_ "GenSigSendType" SG_ 571 EAC_InputCurr 0;
BA_ "GenSigSendType" SG_ 571 EAC_Temp 0;
BA_ "GenSigSendType" SG_ 571 EAC_VehicleFailureLevel 0;
BA_ "GenSigSendType" SG_ 571 EAC_ErrorCode 0;
BA_ "GenSigSendType" SG_ 1249 SW_Group_ID 0;
BA_ "GenSigSendType" SG_ 1249 SW_Base_Number 0;
BA_ "GenSigSendType" SG_ 1253 SW_Major_Version_Number 0;
BA_ "GenSigSendType" SG_ 1253 SW_Minor_Version_Number 0;
BA_ "GenSigSendType" SG_ 1257 HW_Group_ID 0;
BA_ "GenSigSendType" SG_ 1257 HW_Base_Number 0;
BA_ "GenSigSendType" SG_ 1259 HW_Major_Version_Number 0;
BA_ "GenSigSendType" SG_ 1259 HW_Minor_Version_Number 0;
BA_ "GenSigStartValue" SG_ 133 Checksum_0x85 255;
BA_ "GenSigSendType" SG_ 133 Checksum_0x85 0;
BA_ "GenSigInvalidValue" SG_ 133 Rolling_Counter_0x85 15;
BA_ "GenSigSendType" SG_ 133 Rolling_Counter_0x85 0;
BA_ "GenSigInvalidValue" SG_ 133 ACU_Crash_Sts 3;
BA_ "GenSigSendType" SG_ 133 ACU_Crash_Sts 0;
BA_ "GenSigInvalidValue" SG_ 133 ACU_Airbag_Deployment_Status 3;
BA_ "GenSigSendType" SG_ 133 ACU_Airbag_Deployment_Status 0;
BA_ "GenSigStartValue" SG_ 280 CRC_ABS_0x118 255;
BA_ "GenSigSendType" SG_ 280 CRC_ABS_0x118 0;
BA_ "GenSigInvalidValue" SG_ 280 ALIVE_ABS_0x118 15;
BA_ "GenSigSendType" SG_ 280 ALIVE_ABS_0x118 0;
BA_ "GenSigStartValue" SG_ 280 ABS_HazardLightsOnReq 1;
BA_ "GenSigSendType" SG_ 280 ABS_HazardLightsOnReq 0;
BA_ "GenSigStartValue" SG_ 280 ABS_BrakeLightsOnReq 1;
BA_ "GenSigSendType" SG_ 280 ABS_BrakeLightsOnReq 0;
BA_ "GenSigSendType" SG_ 280 ABS_TcsFlgFlt 0;
BA_ "GenSigSendType" SG_ 280 ABS_TCS_Active 0;
BA_ "GenSigSendType" SG_ 280 ABS_ABSActive 0;
BA_ "GenSigSendType" SG_ 280 ABS_EBDFault 0;
BA_ "GenSigSendType" SG_ 280 ABS_ABSFault 0;
BA_ "GenSigSendType" SG_ 280 ABS_TCS_OFF_State 0;
BA_ "GenSigSendType" SG_ 280 ABS_VehicleFailureLevel 0;
BA_ "GenSigSendType" SG_ 280 ABS_RBSInhibitFlag 0;
BA_ "GenSigSendType" SG_ 280 ABS_EBDActive 0;
BA_ "GenSigInvalidValue" SG_ 280 ABS_VehicleSpeed 32767;
BA_ "GenSigSendType" SG_ 280 ABS_VehicleSpeed 0;
BA_ "GenSigSendType" SG_ 280 ABS_VehicleSpeedV 0;
BA_ "GenSigSendType" SG_ 1236 BCM_FrontLeftDoorAjarStatus 0;
BA_ "GenSigSendType" SG_ 1236 BCM_FrontRightDoorAjarStatus 0;
BA_ "GenSigSendType" SG_ 1236 BCM_RightDoorLockStatusDrv 0;
BA_ "GenSigSendType" SG_ 1236 BCM_LeftDoorLockStatusDrv 0;
BA_ "GenSigSendType" SG_ 1236 BCM_ATWS_St 0;
BA_ "GenSigSendType" SG_ 1236 BCM_STAT_DoorSpeedLock 0;
BA_ "GenSigStartValue" SG_ 513 CRC_BCM_0x201 255;
BA_ "GenSigSendType" SG_ 513 CRC_BCM_0x201 0;
BA_ "GenSigInvalidValue" SG_ 513 ALIVE_BCM_0x201 15;
BA_ "GenSigSendType" SG_ 513 ALIVE_BCM_0x201 0;
BA_ "GenSigSendType" SG_ 513 BCM_LV_topupReq 0;
BA_ "GenSigSendType" SG_ 513 BCM_BatteryVoltage 0;
BA_ "GenSigSendType" SG_ 513 BCM_Key_CheckSts 0;
BA_ "GenSigSendType" SG_ 513 BCM_Press_BrkPedal_Alert 0;
BA_ "GenSigSendType" SG_ 513 BCM_EmergencyStop 0;
BA_ "GenSigSendType" SG_ 513 BCM_IGN1RelayOutputSts 0;
BA_ "GenSigSendType" SG_ 513 BCM_ACCRelayOutputSts 0;
BA_ "GenSigSendType" SG_ 513 BCM_FLWIN_Postion_Reserved 0;
BA_ "GenSigSendType" SG_ 513 BCM_KEY_MatchSts 0;
BA_ "GenSigSendType" SG_ 513 BCM_FRWIN_Postion_Reserved 0;
BA_ "GenSigSendType" SG_ 513 BCM_BCMFaultCode 0;
BA_ "GenSigSendType" SG_ 513 BCM_PowerMode 0;
BA_ "GenSigSendType" SG_ 513 BCM_BrakeSwSts 0;
BA_ "GenSigSendType" SG_ 513 BCM_VehicleFailureLevel 0;
BA_ "GenSigStartValue" SG_ 513 BCM_Anti_theftAlarmSetSts 2;
BA_ "GenSigSendType" SG_ 513 BCM_Anti_theftAlarmSetSts 0;
BA_ "GenSigSendType" SG_ 513 BCM_FMH_SetSts 0;
BA_ "GenSigSendType" SG_ 513 BCM_IGN1RelayFaultSts 0;
BA_ "GenSigSendType" SG_ 513 BCM_ACCRelayFaultSts 0;
BA_ "GenSigStartValue" SG_ 676 CRC_IPC_0x2A4 255;
BA_ "GenSigSendType" SG_ 676 CRC_IPC_0x2A4 0;
BA_ "GenSigInvalidValue" SG_ 676 ALIVE_IPC_0x2A4 15;
BA_ "GenSigSendType" SG_ 676 ALIVE_IPC_0x2A4 0;
BA_ "GenSigSendType" SG_ 676 IPC_EnergyRecSet 0;
BA_ "GenSigSendType" SG_ 676 IPC_HSA_Set 0;
BA_ "GenSigSendType" SG_ 676 IPC_DriveModeSet 0;
BA_ "GenSigSendType" SG_ 676 IPC_VCU_CreepDisable_Stt 0;
BA_ "GenSigSendType" SG_ 676 IPC_DriveLockSpeedCtl 0;
BA_ "GenSigStartValue" SG_ 1074 Checksum_0x432 255;
BA_ "GenSigSendType" SG_ 1074 Checksum_0x432 0;
BA_ "GenSigInvalidValue" SG_ 1074 Rolling_Counter_0x432 15;
BA_ "GenSigSendType" SG_ 1074 Rolling_Counter_0x432 0;
BA_ "GenSigSendType" SG_ 1074 IPC_FOTA_State 0;
BA_ "GenSigStartValue" SG_ 677 CRC_IPC_0x2A5 255;
BA_ "GenSigSendType" SG_ 677 CRC_IPC_0x2A5 0;
BA_ "GenSigInvalidValue" SG_ 677 ALIVE_IPC_0x2A5 15;
BA_ "GenSigSendType" SG_ 677 ALIVE_IPC_0x2A5 0;
BA_ "GenSigSendType" SG_ 677 IPC_ChargeScheduleSet 0;
BA_ "GenSigSendType" SG_ 677 IPC_ChargingRequest 0;
BA_ "GenSigStartValue" SG_ 677 IPC_ChrSOCLitCtr 1000;
BA_ "GenSigSendType" SG_ 677 IPC_ChrSOCLitCtr 0;
BA_ "GenSigInvalidValue" SG_ 1087 IPC_Year 255;
BA_ "GenSigSendType" SG_ 1087 IPC_Year 0;
BA_ "GenSigStartValue" SG_ 1087 IPC_Month 1;
BA_ "GenSigInvalidValue" SG_ 1087 IPC_Month 15;
BA_ "GenSigSendType" SG_ 1087 IPC_Month 0;
BA_ "GenSigSendType" SG_ 1087 IPC_SelFCheckStatus 0;
BA_ "GenSigStartValue" SG_ 1087 IPC_Day 1;
BA_ "GenSigInvalidValue" SG_ 1087 IPC_Day 31;
BA_ "GenSigSendType" SG_ 1087 IPC_Day 0;
BA_ "GenSigInvalidValue" SG_ 1087 IPC_Hour 31;
BA_ "GenSigSendType" SG_ 1087 IPC_Hour 0;
BA_ "GenSigInvalidValue" SG_ 1087 IPC_Min 63;
BA_ "GenSigSendType" SG_ 1087 IPC_Min 0;
BA_ "GenSigInvalidValue" SG_ 1087 IPC_Sec 63;
BA_ "GenSigSendType" SG_ 1087 IPC_Sec 0;
BA_ "GenSigStartValue" SG_ 524 CRC_IPC_0x20C 255;
BA_ "GenSigSendType" SG_ 524 CRC_IPC_0x20C 0;
BA_ "GenSigInvalidValue" SG_ 524 ALIVE_IPC_0x20C 15;
BA_ "GenSigSendType" SG_ 524 ALIVE_IPC_0x20C 0;
BA_ "GenSigStartValue" SG_ 524 IPC_ODO 1048575;
BA_ "GenSigSendType" SG_ 524 IPC_ODO 0;
BA_ "GenSigStartValue" SG_ 264 Checksum_0x108 255;
BA_ "GenSigSendType" SG_ 264 Checksum_0x108 0;
BA_ "GenSigInvalidValue" SG_ 264 Rolling_Counter_0x108 15;
BA_ "GenSigSendType" SG_ 264 Rolling_Counter_0x108 0;
BA_ "GenSigSendType" SG_ 264 SS_DriveModeReq_reserved 0;
BA_ "GenSigInvalidValue" SG_ 264 SS_TargetGearReq 4;
BA_ "GenSigSendType" SG_ 264 SS_TargetGearReq 0;
BA_ "GenSigSendType" SG_ 264 SS_Fault 0;
BA_ "GenSigSendType" SG_ 264 FR_Wipercontrol_switch 0;
BA_ "GenSigSendType" SG_ 264 Front_Wash 0;
BA_ "GenSigSendType" SG_ 264 SS_FogLight_reserved 0;
BA_ "GenSigSendType" SG_ 264 RR_Wiper 0;
BA_ "GenSigSendType" SG_ 264 SS_lane_change_lampSts 0;
BA_ "GenSigSendType" SG_ 264 SS_Overtaking_lamp 0;
BA_ "GenSigSendType" SG_ 264 SS_TurnIndicatorSts 0;
BA_ "GenSigSendType" SG_ 264 SS_PosLmpSts 0;
BA_ "GenSigSendType" SG_ 264 SS_LowBeamSts 0;
BA_ "GenSigSendType" SG_ 264 SS_HighBeamSts 0;
BA_ "GenSigStartValue" SG_ 264 SS_HardNumLow 15;
BA_ "GenSigSendType" SG_ 264 SS_HardNumLow 0;
BA_ "GenSigStartValue" SG_ 264 SS_HardNumHigh 15;
BA_ "GenSigSendType" SG_ 264 SS_HardNumHigh 0;
BA_ "GenSigStartValue" SG_ 264 SS_SoftNumLow 15;
BA_ "GenSigSendType" SG_ 264 SS_SoftNumLow 0;
BA_ "GenSigStartValue" SG_ 264 SS_SoftNumHigh 15;
BA_ "GenSigSendType" SG_ 264 SS_SoftNumHigh 0;
BA_ "GenSigStartValue" SG_ 534 Checksum_0x216 255;
BA_ "GenSigSendType" SG_ 534 Checksum_0x216 0;
BA_ "GenSigInvalidValue" SG_ 534 Rolling_Counter_0x216 15;
BA_ "GenSigSendType" SG_ 534 Rolling_Counter_0x216 0;
BA_ "GenSigInvalidValue" SG_ 534 BMS_RemainChargeTime 16383;
BA_ "GenSigSendType" SG_ 534 BMS_RemainChargeTime 0;
BA_ "GenSigInvalidValue" SG_ 534 BMS_ChgVoltage_REQ 16383;
BA_ "GenSigSendType" SG_ 534 BMS_ChgVoltage_REQ 0;
BA_ "GenSigInvalidValue" SG_ 534 BMS_ChgCurrent_REQ 65535;
BA_ "GenSigSendType" SG_ 534 BMS_ChgCurrent_REQ 0;
BA_ "GenSigStartValue" SG_ 294 Checksum_0x126 255;
BA_ "GenSigSendType" SG_ 294 Checksum_0x126 0;
BA_ "GenSigInvalidValue" SG_ 294 Rolling_Counter_0x126 15;
BA_ "GenSigSendType" SG_ 294 Rolling_Counter_0x126 0;
BA_ "GenSigInvalidValue" SG_ 294 BMS_AllowRegCurrPeak 65535;
BA_ "GenSigSendType" SG_ 294 BMS_AllowRegCurrPeak 0;
BA_ "GenSigInvalidValue" SG_ 294 BMS_AllowRegCurr 65535;
BA_ "GenSigSendType" SG_ 294 BMS_AllowRegCurr 0;
BA_ "GenSigStartValue" SG_ 521 Checksum_0x209 255;
BA_ "GenSigSendType" SG_ 521 Checksum_0x209 0;
BA_ "GenSigInvalidValue" SG_ 521 Rolling_Counter_0x209 15;
BA_ "GenSigSendType" SG_ 521 Rolling_Counter_0x209 0;
BA_ "GenSigInvalidValue" SG_ 521 BMS_MaxDischgPwr_ALW 4095;
BA_ "GenSigSendType" SG_ 521 BMS_MaxDischgPwr_ALW 0;
BA_ "GenSigInvalidValue" SG_ 521 BMS_MaxChgPwr_ALW 4095;
BA_ "GenSigSendType" SG_ 521 BMS_MaxChgPwr_ALW 0;
BA_ "GenSigInvalidValue" SG_ 521 BMS_MaxDischgPwr_Peak 4095;
BA_ "GenSigSendType" SG_ 521 BMS_MaxDischgPwr_Peak 0;
BA_ "GenSigInvalidValue" SG_ 521 BMS_MaxChgPwr_Peak 4095;
BA_ "GenSigSendType" SG_ 521 BMS_MaxChgPwr_Peak 0;
BA_ "GenSigStartValue" SG_ 585 Checksum_0x249 255;
BA_ "GenSigSendType" SG_ 585 Checksum_0x249 0;
BA_ "GenSigInvalidValue" SG_ 585 Rolling_Counter_0x249 15;
BA_ "GenSigSendType" SG_ 585 Rolling_Counter_0x249 0;
BA_ "GenSigStartValue" SG_ 585 BMS_CoolantOutletTemp 80;
BA_ "GenSigInvalidValue" SG_ 585 BMS_CoolantOutletTemp 255;
BA_ "GenSigSendType" SG_ 585 BMS_CoolantOutletTemp 0;
BA_ "GenSigStartValue" SG_ 585 BMS_CoolantInletTemp 80;
BA_ "GenSigInvalidValue" SG_ 585 BMS_CoolantInletTemp 255;
BA_ "GenSigSendType" SG_ 585 BMS_CoolantInletTemp 0;
BA_ "GenSigStartValue" SG_ 584 Checksum_0x248 255;
BA_ "GenSigSendType" SG_ 584 Checksum_0x248 0;
BA_ "GenSigInvalidValue" SG_ 584 Rolling_Counter_0x248 15;
BA_ "GenSigSendType" SG_ 584 Rolling_Counter_0x248 0;
BA_ "GenSigInvalidValue" SG_ 584 BMS_FlowRate_Req 255;
BA_ "GenSigSendType" SG_ 584 BMS_FlowRate_Req 0;
BA_ "GenSigInvalidValue" SG_ 584 BMS_CoolPwrDemand 4095;
BA_ "GenSigSendType" SG_ 584 BMS_CoolPwrDemand 0;
BA_ "GenSigSendType" SG_ 584 BMS_VCU_ValveOnOff_Req 0;
BA_ "GenSigInvalidValue" SG_ 584 BMS_HeatPwrDemand 4095;
BA_ "GenSigSendType" SG_ 584 BMS_HeatPwrDemand 0;
BA_ "GenSigSendType" SG_ 584 BMS_VCU_PTCOnOff_Req 0;
BA_ "GenSigStartValue" SG_ 518 Checksum_0x206 255;
BA_ "GenSigSendType" SG_ 518 Checksum_0x206 0;
BA_ "GenSigInvalidValue" SG_ 518 Rolling_Counter_0x206 15;
BA_ "GenSigSendType" SG_ 518 Rolling_Counter_0x206 0;
BA_ "GenSigInvalidValue" SG_ 518 BMS_MaxMinDiffCellVol 8191;
BA_ "GenSigSendType" SG_ 518 BMS_MaxMinDiffCellVol 0;
BA_ "GenSigStartValue" SG_ 818 Checksum_0x332 255;
BA_ "GenSigSendType" SG_ 818 Checksum_0x332 0;
BA_ "GenSigInvalidValue" SG_ 818 Rolling_Counter_0x332 15;
BA_ "GenSigSendType" SG_ 818 Rolling_Counter_0x332 0;
BA_ "GenSigStartValue" SG_ 818 BMS_PackTemp_Infor 80;
BA_ "GenSigInvalidValue" SG_ 818 BMS_PackTemp_Infor 255;
BA_ "GenSigSendType" SG_ 818 BMS_PackTemp_Infor 0;
BA_ "GenSigInvalidValue" SG_ 818 BMS_PackCNom 65535;
BA_ "GenSigSendType" SG_ 818 BMS_PackCNom 0;
BA_ "GenSigStartValue" SG_ 816 Checksum_0x330 255;
BA_ "GenSigSendType" SG_ 816 Checksum_0x330 0;
BA_ "GenSigInvalidValue" SG_ 816 Rolling_Counter_0x330 15;
BA_ "GenSigSendType" SG_ 816 Rolling_Counter_0x330 0;
BA_ "GenSigInvalidValue" SG_ 816 BMS_ContactorAging 255;
BA_ "GenSigSendType" SG_ 816 BMS_ContactorAging 0;
VAL_ 171 ALIVE_VCU_0xAB 15 "Invalid" ;
VAL_ 171 VCU_EDS_CtrModeReq 2 "Speed" 1 "Tqctr" 0 "inactive" ;
VAL_ 171 VCU_EDS_TargetTrqReq 4095 "Invalid" ;
VAL_ 171 VCU_EDS_TargetTrqReqV 0 "Valid" 1 "Invalid" ;
VAL_ 171 VCU_EDS_TargetSpeedReq 65535 "Invalid" ;
VAL_ 171 VCU_EDS_TargetSpeedReqV 0 "Valid" 1 "Invalid" ;
VAL_ 171 VCU_EDS_StsModeReq 15 "invaild" 14 "power oFF" 13 "Failure" 12 "aFter run" 11 "shut down" 5 "HVReady" 4 "normal" 3 "precharge" 2 "standby" 1 "init" 0 "deFault" ;
VAL_ 570 VCU_ACEnaReq 0 "No request" 1 "request" ;
VAL_ 570 VCU_ACSpdReq 8191 "Invalid" ;
VAL_ 570 VCU_ACPanelReqLevel 3 "Invalid" 2 "level 2 " 1 "level 1" 0 "oFF" ;
VAL_ 570 VCU_FanControl_Sts 0 "oFF" 1 "on" ;
VAL_ 570 VCU_ACPipePressSw_Sts 1 "close" 0 "open" ;
VAL_ 570 VCU_HVACInletTemp 1023 "Invalid" ;
VAL_ 341 ALIVE_VCU_0x155 15 "Invalid" ;
VAL_ 341 VCU_VecChrgRqst 0 "Default" 1 "permit" 2 "forbid" ;
VAL_ 341 VCU_Vechg_Status 3 "Charging Fault" 2 "Charging Complete" 1 "Charging in process" 0 "Charging not in process" ;
VAL_ 341 VCU_VecOptMod 0 "Sleep(休眠)" 1 "Initial(初始化)" 2 "PowerOn(上电)" 3 "Drive(行驶)" 4 "Charging(充电)" 5 "PowerOFF(下电)" 6 "Err(故障)" 7 "LimpHome" 8 "LVCharging(馈电补电)" ;
VAL_ 341 VCU_BMSHvPowOnRqst 1 "allow" 0 "forbid" ;
VAL_ 341 VCU_VecActGearStsV 1 "Invalid" 0 "Valid" ;
VAL_ 341 VCU_VecActGearSts 7 "Fault" 6 "Reserved" 5 "Reserved" 4 "Reserved" 3 "D" 2 "N" 1 "R" 0 "P" ;
VAL_ 341 VCU_LV_topupSts 3 "Rserved" 2 "Finish supply" 1 "suppling" 0 "dissupply" ;
VAL_ 341 VCU_DrTorqRqstV 1 "Invalid" 0 "Valid" ;
VAL_ 341 VCU_ABS_TrqReqOrLmt 65535 "Invalid" ;
VAL_ 1221 VCU_CreepDisable_stt 0 "Enable" 1 "disable" ;
VAL_ 1221 VCU_RDCSts 0 "inactive" 1 "Active" ;
VAL_ 1221 VCU_RBCSts 0 "inactive" 1 "Active" ;
VAL_ 1221 VCU_BrkPedalSWSts 0 "Notpressed" 1 "pressed" 2 "notused" 3 "Invalid" ;
VAL_ 1221 Brakefluid_levelSts 0 "Normal" 1 "Low" 2 "Disconnect" 3 "reserve" ;
VAL_ 1221 VCU_HandBrakeSts 0 "released" 1 "notreleased" ;
VAL_ 1221 VCU_RegenLevelfeed 0 "OFF" 1 "ON" ;
VAL_ 1221 VCU_PowerLimit 0 "NoLimit" 1 "Limit" ;
VAL_ 1221 VCU_AccPedaPosValid 0 "Valid" 1 "Invalid" ;
VAL_ 1221 VCU_VehicleHVStatus 0 "NotReady" 1 "HVOn" 2 "Ready" ;
VAL_ 1221 VCUVacuumPresWrn 0 "Normal" 1 "Slight Insufficient" 2 "Serious Insufficient" 3 "Invalid" ;
VAL_ 1221 VCUVacuumSts 0 "Normal" 1 "slow leak" 2 "quick leak" 3 "Invalid" ;
VAL_ 1221 VCU_InstantPowerConsump 1023 "Invalid" ;
VAL_ 1221 VCU_AveragePowerConsump 1023 "Invalid" ;
VAL_ 1221 VCU_LowSOCWarning 0 "Normal" 1 "Low SOC" ;
VAL_ 1221 VCU_TqReductionRqstResponse 0 "inactive" 1 "Active" ;
VAL_ 1221 VCU_DrvModeSts 0 "Normal(正常模式)" 1 "Eco(经济模式)" 2 "Sport(运动模式)" 3 "Reserved(预留)" ;
VAL_ 905 VCU_VacuumPumpEna 1 "Enable" 0 "Disable" ;
VAL_ 1145 VCU_VehicleFailureLevel 0 "Normal" 1 "Slight Fault" 2 "Minor fault" 3 "General fault" 4 "Serious Fault" 5 "Fatal fault" ;
VAL_ 1145 VCU_EDSCAN_ERR 1 "Error" 0 "Normal" ;
VAL_ 1145 VCU_BmsCAN_ERR 1 "Error" 0 "Normal" ;
VAL_ 1145 VCU_DcdcCAN_ERR 1 "Error" 0 "Normal" ;
VAL_ 1145 VCU_AbsCAN_ERR 1 "Error" 0 "Normal" ;
VAL_ 1145 VCU_ACUCAN_ERR 1 "Error" 0 "Normal" ;
VAL_ 1145 VCU_BcmCAN_ERR_reserved 1 "Error" 0 "Normal" ;
VAL_ 1145 VCU_BrakeSys_Err 1 "Error" 0 "Normal" ;
VAL_ 1145 VCU_AccPed_ERR 1 "Error" 0 "Normal" ;
VAL_ 1145 VCU_Shift_ERR 1 "Error" 0 "Normal" ;
VAL_ 1145 VCU_EPSCAN_ERR 1 "Error" 0 "Normal" ;
VAL_ 1145 VCU_EvccCAN_ERR 1 "Error" 0 "Normal" ;
VAL_ 1145 VCU_FlgHVIL_ERR 1 "Error" 0 "Normal" ;
VAL_ 1145 VCU_ObcCAN_ERR 1 "Error" 0 "Normal" ;
VAL_ 1145 VCU_SSCAN_ERR 1 "Error" 0 "Normal" ;
VAL_ 1145 VCU_EacCAN_ERR 1 "Error" 0 "Normal" ;
VAL_ 1145 VCU_AccPedalOutRange 1 "Error" 0 "Normal" ;
VAL_ 201 EDS_VCU_CtrMode 0 "Inactive" 1 "Toque control mode" 2 "Anti-slide slope" 3 "reserved" ;
VAL_ 201 EDS_MotorSpdVD 0 "Valid" 1 "Invalid" ;
VAL_ 201 EDS_MotorTqVD 0 "Valid" 1 "Invalid" ;
VAL_ 201 EDS_MotorTq 65534 "Abnormal" 65535 "Invaild" ;
VAL_ 201 EDS_MotorSpd 65534 "Abnormal" 65535 "Invaild" ;
VAL_ 201 EDS_HSA_Sts 0 "Inactive" 1 "Active" 2 "Reserved" 3 "Invalid" ;
VAL_ 201 EDS_DriveSTS 0 "Regeneration control" 1 "Drive control" 2 "Zero control" ;
VAL_ 201 EDS_StsMode 0 "DeFault(默认值)" 1 "Init(初始化)" 2 "Standby(待机)" 3 "Precharge(预充)" 4 "Normal(正常运行)" 5 "HVReady(高压上电完成)" 11 "ShutDown(关闭)" 12 "AFterRun(运行后)" 13 "Failure" 14 "PowerOFF(下电)" ;
VAL_ 201 EDS_VehicleFailureLevel 0 "Normal" 1 "Slight Fault" 2 "Minor fault" 3 "General fault" 4 "Serious Fault" 5 "Fatal fault" ;
VAL_ 201 EDS_HSA_Fault 0 "Normal" 1 "Level 1" 2 "Level 2" 3 "Invalid" ;
VAL_ 202 ALIVE_EDS_0xCA 15 "Invalid" ;
VAL_ 202 EDS_ActHV_VoltVD 1 "valid" 0 "invalid" ;
VAL_ 202 EDS_ActHV_CurVD 1 "valid" 0 "invalid" ;
VAL_ 202 EDS_ActHV_Cur 4095 "Invalid" ;
VAL_ 202 EDS_ActHV_Volt 4095 "Invalid" ;
VAL_ 206 ALIVE_EDS_0xCE 15 "Invalid" ;
VAL_ 206 EDS_MaxSpeedLimit 65535 "Invalid" ;
VAL_ 871 ALIVE_EDS_0x367 15 "Invalid" ;
VAL_ 872 EDS_MotTempSenFault 0 "Normal" 1 "Error" ;
VAL_ 872 EDS_EDSOverTempAlarm 0 "Normal" 1 "Error" ;
VAL_ 872 EDS_EDSOverTempFault 0 "Normal" 1 "Error" ;
VAL_ 872 EDS_LV_VotagtFault 0 "Normal" 1 "Error" ;
VAL_ 872 EDS_PhashOverCurrentSWFault 0 "Normal" 1 "Error" ;
VAL_ 872 EDS_EDSCurrentSenVFault 0 "Normal" 1 "Error" ;
VAL_ 872 EDS_EDSCurrentSenWFault 0 "Normal" 1 "Error" ;
VAL_ 872 EDS_EDSHVOverVoltageAlarm 0 "Normal" 1 "Error" ;
VAL_ 872 EDS_EDSHVOverVoltageFault 0 "Normal" 1 "Error" ;
VAL_ 872 EDS_EDSHVUnderVoltageAlarm 0 "Normal" 1 "Error" ;
VAL_ 872 EDS_EDSHVUnderVoltageFault 0 "Normal" 1 "Error" ;
VAL_ 872 EDS_MotOverTempAlarm 0 "Normal" 1 "Error" ;
VAL_ 872 EDS_MotOverTempFault 0 "Normal" 1 "Error" ;
VAL_ 872 EDS_EDSDisChgFault 0 "Normal" 1 "Error" ;
VAL_ 872 EDS_EDSHVSenFault 0 "Normal" 1 "Error" ;
VAL_ 872 EDS_12VOverVoltageAlarm 0 "Normal" 1 "Error" ;
VAL_ 872 EDS_12VUnderVoltageAlarm 0 "Normal" 1 "Error" ;
VAL_ 872 EDS_MotOverAlarm 0 "Normal" 1 "Error" ;
VAL_ 872 EDS_MotOverFault 0 "Normal" 1 "Error" ;
VAL_ 872 EDS_PhashOverCurrentHWFault 0 "Normal" 1 "Error" ;
VAL_ 872 EDS_EDSCurrentSenUFault 0 "Normal" 1 "Error" ;
VAL_ 872 EDS_VCULostFault 0 "Normal" 1 "Error" ;
VAL_ 872 EDS_BMSLostFault 0 "Normal" 1 "Error" ;
VAL_ 872 EDS_MotRotSenFault 0 "Normal" 1 "Error" ;
VAL_ 872 EDS_MotBlockedFault 0 "Normal" 1 "Error" ;
VAL_ 872 EDS_EDSChksumFault 0 "Normal" 1 "Error" ;
VAL_ 872 EDS_MotTrqLimtFault 0 "Normal" 1 "Error" ;
VAL_ 872 EDS_VCUChksumFault 0 "Normal" 1 "Error" ;
VAL_ 872 EDS_EDSEnableFault 0 "Normal" 1 "Error" ;
VAL_ 872 EDS_IGBTFault 0 "Normal" 1 "Error" ;
VAL_ 872 EDS_CANBUSOFFFault 0 "Normal" 1 "Error" ;
VAL_ 872 EDS_EDSTempSensorErr 0 "Normal" 1 "Error" ;
VAL_ 872 EDS_HWCapOverVolt 0 "Normal" 1 "Error" ;
VAL_ 872 EDS_SWCapOverVolt 0 "Normal" 1 "Error" ;
VAL_ 872 EDS_EDSMemoryFlt 0 "Normal" 1 "Error" ;
VAL_ 872 EDS_InitMode 0 "Normal" 1 "Error" ;
VAL_ 873 ALIVE_EDS_0x369 15 "Invalid" ;
VAL_ 873 EDS_IGBTState 3 "Normal operation" 2 "ASC From lower bridge arm" 1 "Enter ASC From upper bridge arm " 0 "OFF" ;
VAL_ 873 EDS_DampingState 1 "Dampingactive" 0 "Dampingdisable" ;
VAL_ 873 EDS_StsActiveDisChg 0 "NotActiveDischarge" 1 "ActiveDischarge" 2 "FailedActiveDischarge" 3 "FinishedActiveDischarge" ;
VAL_ 873 EDS_Motor_Phase_Curr 65535 "Invalid" ;
VAL_ 382 Rolling_counter_0x17E 15 "Invalid" ;
VAL_ 382 EPS_S_WarningLampYellow 0 "OFF" 1 "ON" ;
VAL_ 382 EPS_S_SaFeLampRed 0 "OFF" 1 "ON" ;
VAL_ 382 EPS_SteerWheelAngle 65535 "Invalid" ;
VAL_ 382 EPS_SteerWhlRotSpd 16383 "Invalid" ;
VAL_ 382 EPS_SteerWheelRotSpdStatus 0 "Valid" 1 "Invalid" ;
VAL_ 382 EPS_SteeringAngleValid 0 "Valid" 1 "Invalid" ;
VAL_ 382 EPS_VehicleFailureLevel 0 "Normal" 1 "Slight Fault" 2 "Minor fault" 3 "General fault" 4 "Serious Fault" 5 "Fatal fault" ;
VAL_ 382 EPS_status 0 "NoFailure" 1 "SlightFailure" 2 "CriticalFailure" 3 "FatalFailure" ;
VAL_ 382 EPS_Calibrated 0 "NotCalibrated" 1 "Calibrated" ;
VAL_ 382 EPS_Systemstatus 0 "NoFailure" 1 "SlightFailure" 2 "CriticalFailure" 3 "FatalFailure" ;
VAL_ 383 Alive_SAS_0x17F 15 "Invalid" ;
VAL_ 383 EPS_SteeringTorque 4095 "Invalid" ;
VAL_ 383 EPS_SASFailure 0 "Failure" 1 "No failure" ;
VAL_ 383 EPS_SASStsSnsr 1 "sensor value valid" 0 "sensor value Invalid" ;
VAL_ 383 EPS_TorqSensorStatus 0 "Valid" 1 "Invalid" ;
VAL_ 383 EPS_Mode 3 " Invalid" 1 "low assist" 0 "Full assist" ;
VAL_ 383 EPS_EpsFailed 1 "Failed" 0 "not Failed" ;
VAL_ 571 EAC_Sts 0 "Stop" 1 "Work" ;
VAL_ 571 EAC_VehicleFailureLevel 0 "Normal" 1 "Slight Fault" 2 "Minor fault" 3 "General fault" 4 "Serious Fault" 5 "Fatal fault" ;
VAL_ 571 EAC_ErrorCode 0 "Normal" 1 "Under Voltage" 2 "Over Voltage" 3 "Over Temperature" 4 "Over Current" 5 "IGBT Fault" 6 "Over Pressure" ;
VAL_ 133 Rolling_Counter_0x85 15 "Invalid" ;
VAL_ 133 ACU_Crash_Sts 3 "Invalid Value" 2 "Invalid Value" 1 "Crash_Detected" 0 "No_Event" ;
VAL_ 133 ACU_Airbag_Deployment_Status 3 "Invalid Value" 2 "Invalid Value" 1 "Airbag_Deployment" 0 "No_Airbag_Deployment" ;
VAL_ 280 ALIVE_ABS_0x118 15 "Invalid" ;
VAL_ 280 ABS_HazardLightsOnReq 0 "No request" 1 "request" ;
VAL_ 280 ABS_BrakeLightsOnReq 0 "No request" 1 "request" ;
VAL_ 280 ABS_TcsFlgFlt 1 "Failure" 0 "no Failure" ;
VAL_ 280 ABS_TCS_Active 1 "active" 0 "inactive" ;
VAL_ 280 ABS_ABSActive 1 "active" 0 "inactive" ;
VAL_ 280 ABS_EBDFault 1 "Fault" 0 "Normal" ;
VAL_ 280 ABS_ABSFault 1 "Fault" 0 "Normal" ;
VAL_ 280 ABS_TCS_OFF_State 1 "open" 0 "close" ;
VAL_ 280 ABS_VehicleFailureLevel 0 "Normal" 1 "Slight Fault" 2 "Minor fault" 3 "General fault" 4 "Serious Fault" 5 "Fatal fault" ;
VAL_ 280 ABS_RBSInhibitFlag 0 "Not Inhibit" 1 "Inhibit" ;
VAL_ 280 ABS_EBDActive 1 "active" 0 "inactive" ;
VAL_ 280 ABS_VehicleSpeed 32767 "Invalid" ;
VAL_ 280 ABS_VehicleSpeedV 0 "Invalid" 1 "Valid" ;
VAL_ 1236 BCM_FrontLeftDoorAjarStatus 0 "Closed" 1 "Opened" 2 "Reserved" 3 "Signal invalid" ;
VAL_ 1236 BCM_FrontRightDoorAjarStatus 0 "Closed" 1 "Opened" 2 "Reserved" 3 "Signal invalid" ;
VAL_ 1236 BCM_RightDoorLockStatusDrv 0 "Unlcoked" 1 "Locked" 2 "Reserved" 3 "Signal invalid" ;
VAL_ 1236 BCM_LeftDoorLockStatusDrv 0 "Unlcoked" 1 "Locked" 2 "Reserved" 3 "Signal invalid" ;
VAL_ 1236 BCM_ATWS_St 0 "Secured" 1 "Unsecured" 2 "Alarm" 3 "Partly secured" 4 "Security Failure" 5 "Reserved" 6 "Reserved" 7 "Signal invalid" ;
VAL_ 1236 BCM_STAT_DoorSpeedLock 0 "OFF" 1 "5KMH" 2 "10KMH" 3 "15KMH" 4 "20KMH" 5 "25KMH" 6 "Signal invalid" ;
VAL_ 513 BCM_LV_topupReq 0 "inactive" 1 "Active" 2 "Rserved" 3 "Rserved" ;
VAL_ 513 BCM_BatteryVoltage 597 "Invalid" ;
VAL_ 513 BCM_Key_CheckSts 0 "Passed" 1 "Invalid" ;
VAL_ 513 BCM_Press_BrkPedal_Alert 0 "inactive" 1 "Active" ;
VAL_ 513 BCM_EmergencyStop 0 "Normal" 1 "EmergencyStop" 2 "Rserved" 3 "Invalid" ;
VAL_ 513 BCM_IGN1RelayOutputSts 0 "inactive" 1 "Active" 2 "Reserved" 3 "Reserved" ;
VAL_ 513 BCM_ACCRelayOutputSts 0 "inactive" 1 "Active" 2 "Reserved" 3 "Reserved" ;
VAL_ 513 BCM_FLWIN_Postion_Reserved 0 "NotActive" 1 "Closed(Top)" 2 "Open(Bottom)" 3 "80%-Close(Reserved)" 4 "Open-80%(Reserved)" 5 "opening" 6 "closing" 7 "Reserved" ;
VAL_ 513 BCM_KEY_MatchSts 0 "No Match" 1 "Match Success" 2 "Match Failed" 3 "Matching" ;
VAL_ 513 BCM_FRWIN_Postion_Reserved 0 "NotActive" 1 "Closed(Top)" 2 "Open(Bottom)" 3 "80%-Close(Reserved)" 4 "Open-80%(Reserved)" 5 "opening" 6 "closing" 7 "Reserved" ;
VAL_ 513 BCM_PowerMode 0 "OFF" 1 "ACC" 2 "ON" 3 "START" ;
VAL_ 513 BCM_BrakeSwSts 0 "Notpressed" 1 "pressed" 2 "notused" 3 "Invalid" ;
VAL_ 513 BCM_VehicleFailureLevel 0 "Normal" 1 "Slight Fault" 2 "Minor fault" 3 "General fault" 4 "Serious Fault" 5 "Fatal fault" ;
VAL_ 513 BCM_Anti_theftAlarmSetSts 0 "Light" 1 "Horn" 2 "Both" 3 "Invalid" ;
VAL_ 513 BCM_FMH_SetSts 0 "OFF" 1 "30s" 2 "60s" 3 "90s" ;
VAL_ 513 BCM_IGN1RelayFaultSts 0 "No Fault" 1 "Fault" 2 "Reserved" 3 "Signal Invalid" ;
VAL_ 513 BCM_ACCRelayFaultSts 0 "No Fault" 1 "Fault" 2 "Reserved" 3 "Signal Invalid" ;
VAL_ 676 IPC_EnergyRecSet 0 "OFF(关闭)" 1 "ON(开启)" 2 "Reserved(预留)" 3 "Reserved(预留)" ;
VAL_ 676 IPC_HSA_Set 0 "OFF" 1 "ON" 2 "Reserved" 3 "Invalid" ;
VAL_ 676 IPC_DriveModeSet 0 "NoReq" 1 "NormalMode" 2 "ECOmode" 3 "SportMode(预留)" ;
VAL_ 676 IPC_VCU_CreepDisable_Stt 0 "No request" 1 "request" ;
VAL_ 676 IPC_DriveLockSpeedCtl 0 "OFF" 1 "5KMH" 2 "10KMH" 3 "15KMH" 4 "20KMH" 5 "25KMH" 6 "Signal invalid" ;
VAL_ 1074 Rolling_Counter_0x432 15 "Invalid" ;
VAL_ 1074 IPC_FOTA_State 0 "INIT" 1 "NORMAL" 2 "FOTA FLASHING" 3 "Reserved" 4 "FAIL-SAFE-ERROR" 5 "Reserved" 6 "REMOTE DIAGNOSTICS" 7 "Invalid" ;
VAL_ 677 IPC_ChargeScheduleSet 0 "Disable" 1 "Enabled" 2 "No Action" 3 "Reserved" ;
VAL_ 677 IPC_ChargingRequest 0 "No Effect" 1 "Request scheduled start charging" 2 "Request stop" 3 "Reserved" ;
VAL_ 1087 IPC_Year 255 "Invalid" ;
VAL_ 1087 IPC_Month 15 "Invalid" ;
VAL_ 1087 IPC_SelFCheckStatus 1 "selF-check Finish" 0 "selF-checking" ;
VAL_ 1087 IPC_Day 31 "Invalid" ;
VAL_ 1087 IPC_Hour 31 "Invalid" ;
VAL_ 1087 IPC_Min 63 "Invalid" ;
VAL_ 1087 IPC_Sec 63 "Invalid" ;
VAL_ 524 IPC_ODO 1048575 "Invalid" ;
VAL_ 264 Rolling_Counter_0x108 15 "Invalid" ;
VAL_ 264 SS_DriveModeReq_reserved 1 "press" 0 "no press" ;
VAL_ 264 SS_TargetGearReq 7 "Reserved" 4 "Invalid" 3 "D" 2 "N" 1 "R" 0 "Stop Charging" ;
VAL_ 264 SS_Fault 6 "Received Date from BCM is invalid" 5 "Received Date from VCU is invalid" 4 "Supply voltage failure" 3 "Position sensor failure" 2 "CAN communication fail" 1 "Shifter failure" 0 "normal" ;
VAL_ 264 FR_Wipercontrol_switch 7 "Invalid " 6 "reserved " 5 "reserved " 4 "High " 3 "Int2 " 2 "Int1 " 1 "Low " 0 "OFF" ;
VAL_ 264 Front_Wash 3 "Invalid " 2 "Wash " 1 "Mist" 0 "OFF" ;
VAL_ 264 SS_FogLight_reserved 0 "OFF" 1 "ON" ;
VAL_ 264 RR_Wiper 3 "Invalid " 2 "Wash " 1 "Wipe " 0 "OFF" ;
VAL_ 264 SS_lane_change_lampSts 0 "OFF" 1 "Left lane change" 2 "Right lane change" 3 "Reserved" ;
VAL_ 264 SS_Overtaking_lamp 0 "OFF" 1 "ON" ;
VAL_ 264 SS_TurnIndicatorSts 0 "OFF" 1 "Left On" 2 "Right On" 3 "Reserved" ;
VAL_ 264 SS_PosLmpSts 0 "OFF " 1 "ON" ;
VAL_ 264 SS_LowBeamSts 0 "OFF" 1 "ON" ;
VAL_ 264 SS_HighBeamSts 0 "OFF" 1 "ON" ;
VAL_ 534 Rolling_Counter_0x216 15 "Invalid" ;
VAL_ 534 BMS_RemainChargeTime 16383 "Invalid" ;
VAL_ 534 BMS_ChgVoltage_REQ 16383 "Invalid" ;
VAL_ 534 BMS_ChgCurrent_REQ 65535 "Invalid" ;
VAL_ 294 Rolling_Counter_0x126 15 "Invalid" ;
VAL_ 294 BMS_AllowRegCurrPeak 65535 "Invalid" ;
VAL_ 294 BMS_AllowRegCurr 65535 "Invalid" ;
VAL_ 521 Rolling_Counter_0x209 15 "Invalid" ;
VAL_ 521 BMS_MaxDischgPwr_ALW 4095 "Invalid" ;
VAL_ 521 BMS_MaxChgPwr_ALW 4095 "Invalid" ;
VAL_ 521 BMS_MaxDischgPwr_Peak 4095 "Invalid" ;
VAL_ 521 BMS_MaxChgPwr_Peak 4095 "Invalid" ;
VAL_ 585 Rolling_Counter_0x249 15 "Invalid" ;
VAL_ 584 Rolling_Counter_0x248 15 "Invalid" ;
VAL_ 584 BMS_FlowRate_Req 255 "Invalid" ;
VAL_ 584 BMS_CoolPwrDemand 4095 "Invalid" ;
VAL_ 584 BMS_VCU_ValveOnOff_Req 1 "open " 0 "close" ;
VAL_ 584 BMS_HeatPwrDemand 4095 "Invalid" ;
VAL_ 584 BMS_VCU_PTCOnOff_Req 1 "ON" 0 "OFF" ;
VAL_ 518 Rolling_Counter_0x206 15 "Invalid" ;
VAL_ 518 BMS_MaxMinDiffCellVol 8191 "Invalid value if diff > 500mV" ;
VAL_ 818 Rolling_Counter_0x332 15 "Invalid" ;
VAL_ 818 BMS_PackTemp_Infor 255 "Invalid" ;
VAL_ 816 Rolling_Counter_0x330 15 "Invalid" ;
VAL_ 816 BMS_ContactorAging 2 "Fault: counter reach 98%" 1 "Warning: counter reach 90%" 0 "Normal" ;
